VERSION ""

NS_ :

BS_:

BU_: VMCU TECU OBDScanT2 IC3 EMS ECUspare2 ECUspare1 DACU CIOM BBM

BO_ 2147484579 VMCU_BB2_07P: 8 VMCU
 SG_ Pto1BadCondition : 4|4@1+ (1,0) [0|0] ""  BBM,IC3
 SG_ PtosStatus_UB_ISig_4 : 40|1@1+ (1,0) [0|0] ""  EMS,CIOM,BBM,IC3
 SG_ Pto4BadCondition : 12|4@1+ (1,0) [0|0] ""  IC3,BBM
 SG_ Pto2BadCondition : 8|4@1+ (1,0) [0|0] ""  IC3,BBM
 SG_ PtoRequest : 18|2@1+ (1,0) [0|0] ""  EMS
 SG_ Pto2ConsentRequest : 32|2@1+ (1,0) [0|0] ""  TECU
 SG_ PBStatusDisplay_cmd_ISig_4 : 42|2@1+ (1,0) [0|0] ""  IC3
 SG_ Pto4DrivingRequest : 28|2@1+ (1,0) [0|0] ""  BBM
 SG_ Pto3Indication : 58|2@1+ (1,0) [0|0] ""  CIOM
 SG_ Pto2Status_ISig_4 : 22|2@1+ (1,0) [0|0] ""  IC3,TECU,CIOM,BBM
 SG_ Pto4Status_ISig_4 : 34|2@1+ (1,0) [0|0] ""  CIOM,IC3,BBM
 SG_ RampLevelRequestACK_ISig_4 : 44|2@1+ (1,0) [0|0] ""  CIOM
 SG_ Pto3BadCondition : 0|4@1+ (1,0) [0|0] ""  IC3,BBM
 SG_ PtosStatus_ISig_4 : 36|2@1+ (1,0) [0|0] ""  BBM,CIOM,EMS,IC3
 SG_ FrontWheelDriveAutoStatus_ISig_4 : 46|2@1+ (1,0) [0|0] ""  BBM,IC3
 SG_ Pto1ConsentRequest : 24|2@1+ (1,0) [0|0] ""  TECU
 SG_ Pto4Indication : 60|2@1+ (1,0) [0|0] ""  CIOM
 SG_ Pto1FeedbackStatus_UB_ISig_4 : 41|1@1+ (1,0) [0|0] ""  BBM,IC3
 SG_ Pto1Indication : 53|2@1+ (1,0) [0|0] ""  CIOM
 SG_ Pto3Status_ISig_4 : 16|2@1+ (1,0) [0|0] ""  BBM,IC3,CIOM
 SG_ Pto2Indication : 56|2@1+ (1,0) [0|0] ""  CIOM
 SG_ Pto1FeedbackStatus_ISig_4 : 38|2@1+ (1,0) [0|0] ""  BBM
 SG_ TransferCaseOrSplitboxPTOMode_IS : 26|2@1+ (1,0) [0|0] ""  TECU,BBM
 SG_ DirIndRearLamp_Stat_ISig_4 : 50|3@1+ (1,0) [0|0] ""  IC3
 SG_ Pto1Status_ISig_4 : 20|2@1+ (1,0) [0|0] ""  CIOM,TECU,BBM,IC3
 SG_ Pto3DrivingRequest : 30|2@1+ (1,0) [0|0] ""  BBM

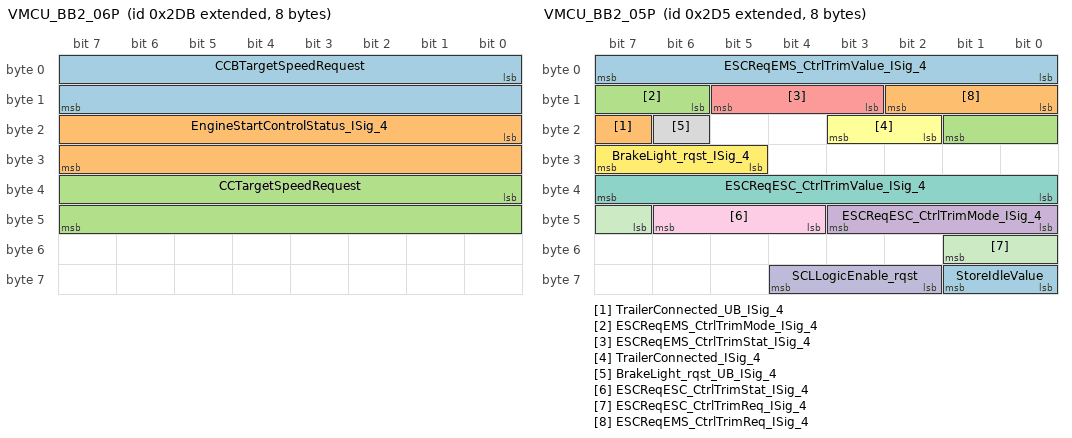
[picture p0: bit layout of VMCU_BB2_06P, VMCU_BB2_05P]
BO_ 2147484379 VMCU_BB2_06P: 8 VMCU
 SG_ CCBTargetSpeedRequest : 0|16@1+ (0.00390625,0) [0|255.99609375] "Km_per_h"  EMS,TECU
 SG_ EngineStartControlStatus_ISig_4 : 16|16@1+ (1,0) [0|0] ""  IC3,BBM
 SG_ CCTargetSpeedRequest : 32|16@1+ (0.00390625,0) [0|255.99609375] "Km_per_h"  TECU,EMS

BO_ 2147484373 VMCU_BB2_05P: 8 VMCU
 SG_ StoreIdleValue : 56|2@1+ (1,0) [0|0] ""  IC3,EMS
 SG_ TrailerConnected_UB_ISig_4 : 23|1@1+ (1,0) [0|0] ""  IC3,EMS,DACU,TECU,BBM
 SG_ ESCReqEMS_CtrlTrimMode_ISig_4 : 14|4@1+ (1,0) [0|0] ""  EMS,TECU,IC3
 SG_ ESCReqESC_CtrlTrimMode_ISig_4 : 40|4@1+ (1,0) [0|0] ""  CIOM,IC3,BBM
 SG_ ESCReqEMS_CtrlTrimStat_ISig_4 : 11|3@1+ (1,0) [0|0] ""  IC3,EMS,TECU
 SG_ TrailerConnected_ISig_4 : 18|2@1+ (1,0) [0|0] ""  TECU,IC3,EMS,DACU,BBM
 SG_ ESCReqESC_CtrlTrimValue_ISig_4 : 32|8@1+ (10,0) [0|2550] ""  BBM,IC3,CIOM
 SG_ BrakeLight_rqst_UB_ISig_4 : 22|1@1+ (1,0) [0|0] ""  BBM
 SG_ ESCReqESC_CtrlTrimStat_ISig_4 : 44|3@1+ (1,0) [0|0] ""  CIOM,BBM,IC3
 SG_ SCLLogicEnable_rqst : 58|3@1+ (1,0) [0|0] ""  CIOM
 SG_ ESCReqESC_CtrlTrimReq_ISig_4 : 47|3@1+ (1,0) [0|0] ""  IC3,CIOM,BBM
 SG_ BrakeLight_rqst_ISig_4 : 29|3@1+ (1,0) [0|0] ""  BBM
 SG_ ESCReqEMS_CtrlTrimValue_ISig_4 : 0|8@1+ (10,0) [0|2550] ""  IC3,TECU,EMS
 SG_ ESCReqEMS_CtrlTrimReq_ISig_4 : 8|3@1+ (1,0) [0|0] ""  IC3,TECU,EMS

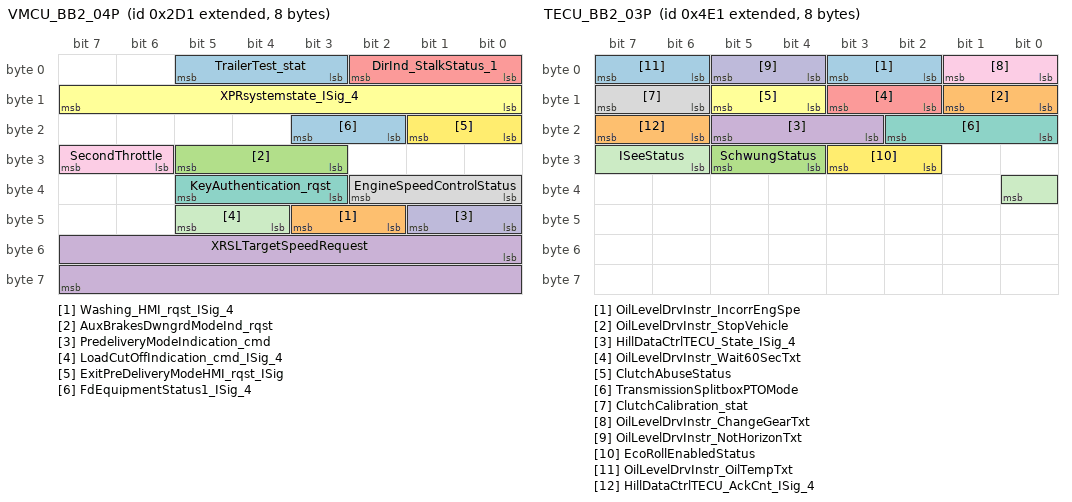
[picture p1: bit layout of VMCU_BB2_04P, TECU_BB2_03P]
BO_ 2147484369 VMCU_BB2_04P: 8 VMCU
 SG_ TrailerTest_stat : 3|3@1+ (1,0) [0|0] ""  IC3
 SG_ Washing_HMI_rqst_ISig_4 : 42|2@1+ (1,0) [0|0] ""  CIOM
 SG_ AuxBrakesDwngrdModeInd_rqst : 27|3@1+ (1,0) [0|0] ""  IC3
 SG_ XRSLTargetSpeedRequest : 48|16@1+ (0.00390625,0) [0|255.99609375] "Km_per_h"  EMS
 SG_ DirInd_StalkStatus_1 : 0|3@1+ (1,0) [0|0] ""  IC3
 SG_ XPRsystemstate_ISig_4 : 8|8@1+ (1,0) [0|255] "NotApplicable"  DACU,BBM
 SG_ KeyAuthentication_rqst : 35|3@1+ (1,0) [0|0] ""  CIOM
 SG_ EngineSpeedControlStatus : 32|3@1+ (1,0) [0|0] ""  CIOM,IC3,BBM
 SG_ SecondThrottle : 30|2@1+ (1,0) [0|0] ""  EMS,DACU
 SG_ PredeliveryModeIndication_cmd : 40|2@1+ (1,0) [0|0] ""  IC3,CIOM
 SG_ LoadCutOffIndication_cmd_ISig_4 : 44|2@1+ (1,0) [0|0] ""  IC3
 SG_ ExitPreDeliveryModeHMI_rqst_ISig : 16|2@1+ (1,0) [0|0] ""  CIOM
 SG_ FdEquipmentStatus1_ISig_4 : 18|2@1+ (1,0) [0|0] ""  BBM,IC3,CIOM

BO_ 2147484182 VMCU_BB2_03P: 8 VMCU
 SG_ ParkBrakeAlert_ISig_4 : 42|2@1+ (1,0) [0|0] ""  IC3
 SG_ IntLightMode_CoreRqst_IL_Mode : 48|3@1+ (1,0) [0|0] ""  IC3,CIOM
 SG_ WiperModeStatus_UB_ISig_4 : 55|1@1+ (1,0) [0|0] ""  CIOM,BBM,IC3,DACU
 SG_ SteeringColumnLockErrInd_rqst : 27|3@1+ (1,0) [0|0] ""  IC3
 SG_ ParkingLight_Indication : 30|2@1+ (1,0) [0|0] ""  CIOM
 SG_ DaytimeRunningLight_Indication : 16|2@1+ (1,0) [0|0] ""  CIOM
 SG_ EPBBackupMode_ISig_4 : 44|4@1+ (1,0) [0|0] ""  IC3
 SG_ WiperModeStatus_ISig_4 : 32|3@1+ (1,0) [0|0] ""  CIOM,DACU,IC3,BBM
 SG_ FrontFog_Indication : 22|2@1+ (1,0) [0|0] ""  CIOM
 SG_ PBReleaseAcceptance_stat_ISig_4 : 37|3@1+ (1,0) [0|0] ""  IC3
 SG_ ParkingBrake_stat_UB_ISig_4 : 54|1@1+ (1,0) [0|0] ""  IC3,EMS,CIOM,TECU,BBM
 SG_ DrivingLightPlus_Indication : 8|2@1+ (1,0) [0|0] ""  CIOM
 SG_ IntLightMode_CoreRqst_EventFlag : 51|1@1+ (1,0) [0|0] ""  CIOM,IC3
 SG_ ParkingBrake_stat_ISig_4 : 40|2@1+ (1,0) [0|0] ""  EMS,IC3,CIOM,BBM,TECU
 SG_ DrivingLight_Indication : 4|2@1+ (1,0) [0|0] ""  CIOM
 SG_ MirrorHeatingMode_ISig_4 : 24|3@1+ (1,0) [0|0] ""  CIOM
 SG_ RearFog_Indication : 35|2@1+ (1,0) [0|0] ""  CIOM
 SG_ InteriorLightLevelInd_cmd : 56|8@1+ (1,0) [0|255] "Percent"  CIOM

BO_ 2147484180 VMCU_BB2_02P: 8 VMCU
 SG_ LevelControlInformation_UB_ISig_ : 22|1@1+ (1,0) [0|0] ""  CIOM,IC3,TECU
 SG_ LiftAxle2LiftFuncSelected_ISig_4 : 11|3@1+ (1,0) [0|0] ""  IC3
 SG_ StopLevelChangeAck_ISig_4 : 6|2@1+ (1,0) [0|0] ""  CIOM
 SG_ HeightAdjustmentAllowed_ISig_4 : 38|2@1+ (1,0) [0|0] ""  CIOM
 SG_ LiftAxle2LowerACK_ISig_4 : 27|3@1+ (1,0) [0|0] ""  IC3
 SG_ LiftAxle2UpRequestACK_ISig_4 : 0|3@1+ (1,0) [0|0] ""  CIOM,IC3
 SG_ RideHeightStatus_ISig_4 : 44|4@1+ (1,0) [0|0] ""  CIOM,BBM
 SG_ RideHeightOutsideTargetRange_ISi : 32|3@1+ (1,0) [0|0] ""  IC3,CIOM
 SG_ LoadDistributionFuncSelected_ISi : 56|4@1+ (1,0) [0|0] ""  CIOM
 SG_ RideHeightStorageAck_ISig_4 : 30|2@1+ (1,0) [0|0] ""  CIOM
 SG_ LiftAxle2AutoLiftSelected_ISig_4 : 54|2@1+ (1,0) [0|0] ""  IC3
 SG_ LiftAxle1UpRequestACK_ISig_4 : 3|3@1+ (1,0) [0|0] ""  IC3,CIOM
 SG_ LiftAxle1PositionStatus_ISig_4 : 16|3@1+ (1,0) [0|0] ""  BBM,CIOM,TECU,DACU,IC3
 SG_ LiftAxle1LowerACK_ISig_4 : 24|3@1+ (1,0) [0|0] ""  IC3
 SG_ LiftAxle1AutoLiftSelected_ISig_4 : 52|2@1+ (1,0) [0|0] ""  IC3
 SG_ LiftAxle2PositionStatus_ISig_4 : 19|3@1+ (1,0) [0|0] ""  IC3,BBM,CIOM
 SG_ LevelControlInformation_ISig_4 : 48|4@1+ (1,0) [0|0] ""  TECU,IC3,CIOM
 SG_ LiftAxle1LiftFuncSelected_ISig_4 : 8|3@1+ (1,0) [0|0] ""  IC3
 SG_ LoadDistributionChangeACK_ISig_4 : 35|3@1+ (1,0) [0|0] ""  CIOM,IC3
 SG_ RampLevelStorageAck_ISig_4 : 14|2@1+ (1,0) [0|0] ""  CIOM
 SG_ LoadDistributionSelected_ISig_4 : 60|4@1+ (1,0) [0|0] ""  IC3,BBM,CIOM
 SG_ RideHeightFunctionStatus_ISig_4 : 40|4@1+ (1,0) [0|0] ""  CIOM

BO_ 2147484168 VMCU_BB2_01P: 8 VMCU
 SG_ GearSplit_Status_UB_ISig_4 : 13|1@1+ (1,0) [0|0] ""  IC3,BBM
 SG_ TransmLowRangeSenseSwitch_ISig_4 : 34|2@1+ (1,0) [0|0] ""  IC3,EMS
 SG_ TransmSystemPowerDown_rqst : 30|2@1+ (1,0) [0|0] ""  TECU
 SG_ TransmissionNeutralSwitch_ISig_4 : 8|2@1+ (1,0) [0|0] ""  BBM,EMS
 SG_ SecuredNeutralPosition_ISig_4 : 36|2@1+ (1,0) [0|0] ""  EMS,IC3,BBM
 SG_ EngineStopRequest_ISig_4 : 4|2@1+ (1,0) [0|0] ""  EMS
 SG_ TransmissionNeutralSwitch_UB_ISi : 32|1@1+ (1,0) [0|0] ""  EMS,BBM
 SG_ ReverseGearEngaged_ISig_4 : 0|2@1+ (1,0) [0|0] ""  DACU,EMS,CIOM,BBM,IC3
 SG_ TransmSystemPowerDown_rqst_UB : 33|1@1+ (1,0) [0|0] ""  TECU
 SG_ EngineCrankRequest : 14|2@1+ (1,0) [0|0] ""  EMS
 SG_ ParkBrakeActuationStatus_UB : 39|1@1+ (1,0) [0|0] ""  IC3,TECU,BBM
 SG_ ParkBrakeActuationStatus : 40|3@1+ (1,0) [0|0] ""  TECU,DACU,BBM,IC3
 SG_ EnginePreheat_rqst : 28|2@1+ (1,0) [0|0] ""  EMS
 SG_ ReverseGearEngaged_UB_ISig_4 : 12|1@1+ (1,0) [0|0] ""  EMS,DACU,IC3,CIOM,BBM
 SG_ AcceleratorPedalPositionBackup : 56|8@1+ (0.4,0) [0|102] "Percent"  EMS,TECU
 SG_ KeyPosition_ISig_4 : 16|3@1+ (1,0) [0|0] ""  CIOM,IC3
 SG_ GearSplit_Status_ISig_4 : 2|2@1+ (1,0) [0|0] ""  IC3,BBM
 SG_ FerryFunctionSwitchChangeACK_ISi : 45|2@1+ (1,0) [0|0] ""  CIOM
 SG_ SecuredNeutralPosition_UB_ISig_4 : 38|1@1+ (1,0) [0|0] ""  BBM,IC3,EMS
 SG_ DirectionIndication_cmd : 24|4@1+ (1,0) [0|0] ""  IC3
 SG_ IdleShutdownWarning : 6|2@1+ (1,0) [0|0] ""  IC3
 SG_ BackToDriveReqACK_ISig_4 : 43|2@1+ (1,0) [0|0] ""  CIOM
 SG_ EngineSystemPowerDownRequest_ISi : 22|2@1+ (1,0) [0|0] ""  EMS,IC3

BO_ 2671902706 TesterFuncDiagMsg_BB2: 8 VMCU
 SG_ FuncDiagDataTester_ISig_4 : 0|64@1+ (1,0) [0|0] ""  IC3,BBM,EMS,DACU,CIOM,TECU

BO_ 2147485094 TECU_BB2_06S_FCM: 8 CIOM
 SG_ TECU_BB2_06S_FCS : 0|64@1+ (1,0) [0|0] ""  TECU

BO_ 2147485093 TECU_BB2_06S: 11 TECU
 SG_ ECU5VIN_stat : 0|88@1+ (1,0) [0|0] ""  CIOM

BO_ 2147484587 TECU_BB2_05S_FCM: 8 CIOM
 SG_ TECU_BB2_05S_FCS : 0|64@1+ (1,0) [0|0] ""  TECU

BO_ 2147484586 TECU_BB2_05S: 16 TECU
 SG_ KeyID_EncryptedGBUnlockAuth : 0|128@1+ (1,0) [0|0] ""  CIOM

BO_ 2147485128 TECU_BB2_04S_FCM: 8 IC3
 SG_ TECU_BB2_04S_FCS : 0|64@1+ (1,0) [0|0] ""  TECU

BO_ 2147485127 TECU_BB2_04S: 284 TECU
 SG_ HillDataPkgTECU_ISig_4 : 0|2272@1+ (1,0) [0|0] ""  IC3

BO_ 2147484897 TECU_BB2_03P: 8 TECU
 SG_ OilLevelDrvInstr_IncorrEngSpe : 2|2@1+ (1,0) [0|0] ""  IC3
 SG_ OilLevelDrvInstr_StopVehicle : 8|2@1+ (1,0) [0|0] ""  IC3
 SG_ SchwungStatus : 28|2@1+ (1,0) [0|0] ""  VMCU
 SG_ HillDataCtrlTECU_State_ISig_4 : 19|3@1+ (1,0) [0|0] ""  IC3
 SG_ OilLevelDrvInstr_Wait60SecTxt : 10|2@1+ (1,0) [0|0] ""  IC3
 SG_ ClutchAbuseStatus : 12|2@1+ (1,0) [0|0] ""  IC3
 SG_ TransmissionSplitboxPTOMode : 16|3@1+ (1,0) [0|0] ""  IC3
 SG_ ClutchCalibration_stat : 14|2@1+ (1,0) [0|0] ""  IC3
 SG_ OilLevelDrvInstr_ChangeGearTxt : 0|2@1+ (1,0) [0|0] ""  IC3
 SG_ OilLevelDrvInstr_NotHorizonTxt : 4|2@1+ (1,0) [0|0] ""  IC3
 SG_ ISeeStatus : 30|3@1+ (1,0) [0|0] ""  IC3
 SG_ EcoRollEnabledStatus : 26|2@1+ (1,0) [0|0] ""  IC3
 SG_ OilLevelDrvInstr_OilTempTxt : 6|2@1+ (1,0) [0|0] ""  IC3
 SG_ HillDataCtrlTECU_AckCnt_ISig_4 : 22|2@1+ (1,0) [0|3] ""  IC3

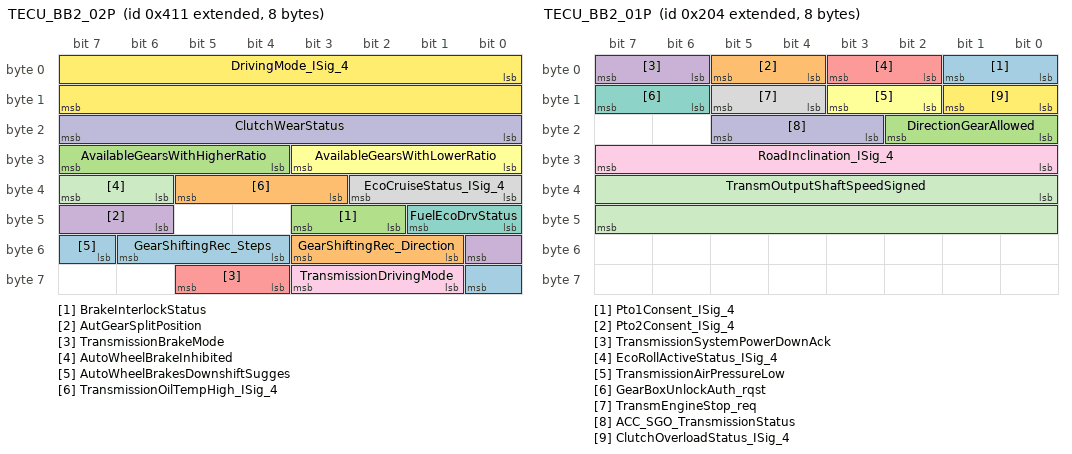
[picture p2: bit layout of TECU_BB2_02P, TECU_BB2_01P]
BO_ 2147484689 TECU_BB2_02P: 8 TECU
 SG_ GearShiftingRec_Steps : 52|3@1+ (1,0) [0|0] ""  IC3
 SG_ GearShiftingRec_Direction : 49|3@1+ (1,0) [0|0] ""  IC3
 SG_ BrakeInterlockStatus : 42|2@1+ (1,0) [0|0] ""  IC3,VMCU
 SG_ AutGearSplitPosition : 46|3@1+ (1,0) [0|0] ""  IC3
 SG_ TransmissionBrakeMode : 60|2@1+ (1,0) [0|0] ""  IC3
 SG_ AvailableGearsWithLowerRatio : 24|4@1+ (1,0) [0|15] "Count"  IC3
 SG_ FuelEcoDrvStatus : 40|2@1+ (1,0) [0|0] ""  VMCU
 SG_ EcoCruiseStatus_ISig_4 : 32|3@1+ (1,0) [0|0] ""  IC3,EMS
 SG_ TransmissionDrivingMode : 57|3@1+ (1,0) [0|0] ""  IC3
 SG_ ClutchWearStatus : 16|8@1+ (0.4,0) [0|102] "Percent"  VMCU
 SG_ AutoWheelBrakeInhibited : 38|2@1+ (1,0) [0|0] ""  EMS
 SG_ DrivingMode_ISig_4 : 0|16@1+ (1,0) [0|0] ""  VMCU,IC3
 SG_ AutoWheelBrakesDownshiftSugges : 55|2@1+ (1,0) [0|0] ""  IC3
 SG_ TransmissionOilTempHigh_ISig_4 : 35|3@1+ (1,0) [0|0] ""  BBM,IC3
 SG_ AvailableGearsWithHigherRatio : 28|4@1+ (1,0) [0|15] "Count"  VMCU,IC3

BO_ 2147484164 TECU_BB2_01P: 8 TECU
 SG_ Pto1Consent_ISig_4 : 0|2@1+ (1,0) [0|0] ""  BBM,VMCU
 SG_ Pto2Consent_ISig_4 : 4|2@1+ (1,0) [0|0] ""  BBM,VMCU
 SG_ DirectionGearAllowed : 16|3@1+ (1,0) [0|0] ""  VMCU
 SG_ TransmissionSystemPowerDownAck : 6|2@1+ (1,0) [0|0] ""  VMCU
 SG_ EcoRollActiveStatus_ISig_4 : 2|2@1+ (1,0) [0|0] ""  IC3,VMCU
 SG_ TransmissionAirPressureLow : 10|2@1+ (1,0) [0|0] ""  IC3
 SG_ GearBoxUnlockAuth_rqst : 14|2@1+ (1,0) [0|0] ""  CIOM
 SG_ TransmEngineStop_req : 12|2@1+ (1,0) [0|0] ""  EMS
 SG_ RoadInclination_ISig_4 : 24|8@1+ (0.2,-25) [-25|26] "Percent"  IC3,VMCU,EMS,DACU
 SG_ ACC_SGO_TransmissionStatus : 19|3@1+ (1,0) [0|0] ""  EMS,DACU
 SG_ TransmOutputShaftSpeedSigned : 32|16@1+ (0.125,-4000) [-4000|4191.875] "rpm"  DACU
 SG_ ClutchOverloadStatus_ISig_4 : 8|2@1+ (1,0) [0|0] ""  IC3,BBM

BO_ 2365530173 Reserved_CANid_02_BB2: 8 Vector__XXX

BO_ 2365530429 Reserved_CANid_01_BB2: 8 Vector__XXX

BO_ 2671833830 PhysDiagRespMsg_F2_E6_BB2: 8 BBM
 SG_ PhysDiagRespSig_F2_E6_ISig_4 : 0|64@1+ (1,0) [0|0] ""  VMCU

BO_ 2671833829 PhysDiagRespMsg_F2_E5_BB2: 8 BBM
 SG_ PhysDiagRespSig_F2_E5_ISig_4 : 0|64@1+ (1,0) [0|0] ""  VMCU

BO_ 2671833792 PhysDiagRespMsg_F2_C0_BB2: 8 CIOM
 SG_ PhysDiagRespSig_F2_C0_ISig_4 : 0|64@1+ (1,0) [0|0] ""  VMCU

BO_ 2671833762 PhysDiagRespMsg_F2_A2_BB2: 8 CIOM
 SG_ PhysDiagRespSig_F2_A2_ISig_4 : 0|64@1+ (1,0) [0|0] ""  VMCU

BO_ 2671833761 PhysDiagRespMsg_F2_A1_BB2: 8 CIOM
 SG_ PhysDiagRespSig_F2_A1_ISig_4 : 0|64@1+ (1,0) [0|0] ""  VMCU

BO_ 2671833760 PhysDiagRespMsg_F2_A0_BB2: 8 CIOM
 SG_ PhysDiagRespSig_F2_A0_ISig_4 : 0|64@1+ (1,0) [0|0] ""  VMCU

BO_ 2671833752 PhysDiagRespMsg_F2_98_BB2: 8 CIOM
 SG_ PhysDiagRespSig_F2_98_ISig_4 : 0|64@1+ (1,0) [0|0] ""  VMCU

BO_ 2671833731 PhysDiagRespMsg_F2_83_BB2: 8 IC3
 SG_ PhysDiagRespSig_F2_83_ISig_4 : 0|64@1+ (1,0) [0|0] ""  VMCU

BO_ 2671833730 PhysDiagRespMsg_F2_82_BB2: 8 IC3
 SG_ PhysDiagRespSig_F2_82_ISig_4 : 0|64@1+ (1,0) [0|0] ""  VMCU

BO_ 2671833697 PhysDiagRespMsg_F2_61_BB2: 8 IC3
 SG_ PhysDiagRespSig_F2_61_ISig_4 : 0|64@1+ (1,0) [0|0] ""  VMCU

BO_ 2671833696 PhysDiagRespMsg_F2_60_BB2: 8 IC3
 SG_ PhysDiagRespSig_F2_60_ISig_4 : 0|64@1+ (1,0) [0|0] ""  VMCU

BO_ 2671833683 PhysDiagRespMsg_F2_53_BB2: 8 CIOM
 SG_ PhysDiagRespSig_F2_53_ISig_4 : 0|64@1+ (1,0) [0|0] ""  VMCU

BO_ 2671833682 PhysDiagRespMsg_F2_52_BB2: 8 DACU
 SG_ PhysDiagRespSig_F2_52_ISig_4 : 0|64@1+ (1,0) [0|0] ""  VMCU

BO_ 2671833681 PhysDiagRespMsg_F2_51_BB2: 8 DACU
 SG_ PhysDiagRespSig_F2_51_ISig_4 : 0|64@1+ (1,0) [0|0] ""  VMCU

BO_ 2671833680 PhysDiagRespMsg_F2_50_BB2: 8 DACU
 SG_ PhysDiagRespSig_F2_50_ISig_4 : 0|64@1+ (1,0) [0|0] ""  VMCU

BO_ 2671833665 PhysDiagRespMsg_F2_41_BB2: 8 IC3
 SG_ PhysDiagRespSig_F2_41_ISig_4 : 0|64@1+ (1,0) [0|0] ""  VMCU

BO_ 2671833664 PhysDiagRespMsg_F2_40_BB2: 8 CIOM
 SG_ PhysDiagRespSig_F2_40_ISig_4 : 0|64@1+ (1,0) [0|0] ""  VMCU

BO_ 2671833638 PhysDiagRespMsg_F2_26_BB2: 8 CIOM
 SG_ PhysDiagRespSig_F2_26_ISig_4 : 0|64@1+ (1,0) [0|0] ""  VMCU

BO_ 2671833624 PhysDiagRespMsg_F2_18_BB2: 8 TECU
 SG_ PhysDiagRespSig_F2_18_ISig_4 : 0|64@1+ (1,0) [0|0] ""  VMCU

BO_ 2671833616 PhysDiagRespMsg_F2_10_BB2: 8 EMS
 SG_ PhysDiagRespSig_F2_10_ISig_4 : 0|64@1+ (1,0) [0|0] ""  VMCU

BO_ 2564485459 PhysDiagRespMsg_F1_53_BB2: 8 CIOM
 SG_ PhysDiagRespSig_F1_53_ISig_4 : 0|64@1+ (1,0) [0|0] ""  VMCU

BO_ 2564485392 PhysDiagRespMsg_F1_10_BB2_extra: 8 EMS
 SG_ PhysDiagRespSig_F1_10_extra : 0|64@1+ (1,0) [0|0] ""  OBDScanT2

BO_ 2671833360 PhysDiagRespMsg_F1_10_BB2: 8 EMS
 SG_ PhysDiagRespSig_F1_10_ISig_4 : 0|64@1+ (1,0) [0|0] ""  VMCU

BO_ 2671833700 PhysDiagReqMsg_F2_64_BB2: 8 IC3
 SG_ PhysDiagRespSig_F2_64_ISig_4 : 0|64@1+ (1,0) [0|0] ""  VMCU

BO_ 2671830770 PhysDiagReqMsg_E6_F2_BB2: 8 VMCU
 SG_ PhysDiagReqSig_E6_F2_ISig_4 : 0|64@1+ (1,0) [0|0] ""  BBM

BO_ 2671830514 PhysDiagReqMsg_E5_F2_BB2: 8 VMCU
 SG_ PhysDiagReqSig_E5_F2_ISig_4 : 0|64@1+ (1,0) [0|0] ""  BBM

BO_ 2671821042 PhysDiagReqMsg_C0_F2_BB2: 8 VMCU
 SG_ PhysDiagReqSig_C0_F2_ISig_4 : 0|64@1+ (1,0) [0|0] ""  CIOM

BO_ 2671813362 PhysDiagReqMsg_A2_F2_BB2: 8 VMCU
 SG_ PhysDiagReqSig_A2_F2_ISig_4 : 0|64@1+ (1,0) [0|0] ""  CIOM

BO_ 2671813106 PhysDiagReqMsg_A1_F2_BB2: 8 VMCU
 SG_ PhysDiagReqSig_A1_F2_ISig_4 : 0|64@1+ (1,0) [0|0] ""  CIOM

BO_ 2671812850 PhysDiagReqMsg_A0_F2_BB2: 8 VMCU
 SG_ PhysDiagReqSig_A0_F2_ISig_4 : 0|64@1+ (1,0) [0|0] ""  CIOM

BO_ 2671810802 PhysDiagReqMsg_98_F2_BB2: 8 VMCU
 SG_ PhysDiagReqSig_98_F2_ISig_4 : 0|64@1+ (1,0) [0|0] ""  CIOM

BO_ 2671805426 PhysDiagReqMsg_83_F2_BB2: 8 VMCU
 SG_ PhysDiagReqSig_83_F2_ISig_4 : 0|64@1+ (1,0) [0|0] ""  IC3

BO_ 2671805170 PhysDiagReqMsg_82_F2_BB2: 8 VMCU
 SG_ PhysDiagReqSig_82_F2_ISig_4 : 0|64@1+ (1,0) [0|0] ""  IC3

BO_ 2671797490 PhysDiagReqMsg_64_F2_BB2: 8 VMCU
 SG_ PhysDiagReqSig_64_F2_ISig_4 : 0|64@1+ (1,0) [0|0] ""  IC3

BO_ 2671796722 PhysDiagReqMsg_61_F2_BB2: 8 VMCU
 SG_ PhysDiagReqSig_61_F2_ISig_4 : 0|64@1+ (1,0) [0|0] ""  IC3

BO_ 2671796466 PhysDiagReqMsg_60_F2_BB2: 8 VMCU
 SG_ PhysDiagReqSig_60_F2_ISig_4 : 0|64@1+ (1,0) [0|0] ""  IC3

BO_ 2671793138 PhysDiagReqMsg_53_F2_BB2: 8 VMCU
 SG_ PhysDiagReqSig_53_F2_ISig_4 : 0|64@1+ (1,0) [0|0] ""  CIOM

BO_ 2564445169 PhysDiagReqMsg_53_F1_BB2: 8 VMCU
 SG_ PhysDiagReqSig_53_F1_ISig_4 : 0|64@1+ (1,0) [0|0] ""  CIOM

BO_ 2671792882 PhysDiagReqMsg_52_F2_BB2: 8 VMCU
 SG_ PhysDiagReqSig_52_F2_ISig_4 : 0|64@1+ (1,0) [0|0] ""  DACU

BO_ 2671792626 PhysDiagReqMsg_51_F2_BB2: 8 VMCU
 SG_ PhysDiagReqSig_51_F2_ISig_4 : 0|64@1+ (1,0) [0|0] ""  DACU

BO_ 2671792370 PhysDiagReqMsg_50_F2_BB2: 8 VMCU
 SG_ PhysDiagReqSig_50_F2_ISig_4 : 0|64@1+ (1,0) [0|0] ""  DACU

BO_ 2671788530 PhysDiagReqMsg_41_F2_BB2: 8 VMCU
 SG_ PhysDiagReqSig_41_F2_ISig_4 : 0|64@1+ (1,0) [0|0] ""  IC3

BO_ 2671788274 PhysDiagReqMsg_40_F2_BB2: 8 VMCU
 SG_ PhysDiagReqSig_40_F2_ISig_4 : 0|64@1+ (1,0) [0|0] ""  CIOM

BO_ 2671781618 PhysDiagReqMsg_26_F2_BB2: 8 VMCU
 SG_ PhysDiagReqSig_26_F2_ISig_4 : 0|64@1+ (1,0) [0|0] ""  CIOM

BO_ 2671778034 PhysDiagReqMsg_18_F2_BB2: 8 VMCU
 SG_ PhysDiagReqSig_18_F2_ISig_4 : 0|64@1+ (1,0) [0|0] ""  TECU

BO_ 2671775986 PhysDiagReqMsg_10_F2_BB2: 8 VMCU
 SG_ PhysDiagReqSig_10_F2_ISig_4 : 0|64@1+ (1,0) [0|0] ""  EMS

BO_ 2564428017 PhysDiagReqMsg_10_F1_BB2_extra: 8 OBDScanT2
 SG_ PhysDiagReqSig_10_F1_extra : 0|64@1+ (1,0) [0|0] ""  EMS

BO_ 2671775985 PhysDiagReqMsg_10_F1_BB2: 8 VMCU
 SG_ PhysDiagReqSig_10_F1_ISig_4 : 0|64@1+ (1,0) [0|0] ""  EMS

BO_ 2564502513 OBDFuncDiagMsg_BB2_extra: 8 OBDScanT2
 SG_ FuncDiagDataOBD_extra : 0|64@1+ (1,0) [0|0] ""  EMS

CM_ SG_ 2147484379 CCBTargetSpeedRequest "65024 - 65279 Error ; 65280 - 65535 Not available";
CM_ SG_ 2147484379 EngineStartControlStatus_ISig_4 "65534 Error ; 65535 Not available";
CM_ SG_ 2147484379 CCTargetSpeedRequest "65024 - 65279 Error ; 65280 - 65535 Not available";
CM_ SG_ 2147484373 ESCReqESC_CtrlTrimValue_ISig_4 "254 Error ; 255 Not available";
CM_ SG_ 2147484373 ESCReqEMS_CtrlTrimValue_ISig_4 "254 Error ; 255 Not available";
CM_ SG_ 2147484369 XRSLTargetSpeedRequest "65024 - 65279 Error ; 65280 - 65535 Not available";
CM_ SG_ 2147484689 AvailableGearsWithLowerRatio "14 Error ; 15 Not available";
CM_ SG_ 2147484689 ClutchWearStatus "254 Error ; 255 Not available";
CM_ SG_ 2147484689 AvailableGearsWithHigherRatio "14 Error ; 15 Not available";
CM_ SG_ 2147484164 RoadInclination_ISig_4 "254 Error ; 255 Not available";
CM_ BO_ 2365530173 "Request to reserve CANid from Powertrain (ACM ECU)";
CM_ BO_ 2365530429 "Request to reserve CANid from Powertrain (ACM ECU)";
CM_ BO_ 2671833696 "Note: old interface for HMIIOM, can be deleted when IC3 is configured with address 0x61.";
CM_ BO_ 2671796466 "Note: old interface for HMIIOM, can be deleted when IC3 is configured with address 0x61.";
BA_DEF_ BO_  "GenMsgStartDelayTime" INT 0 0;
BA_DEF_ BO_  "GenMsgDelayTime" INT 0 0;
BA_DEF_ BO_  "GenMsgCycleTime" INT 0 0;
BA_DEF_ BO_  "GenMsgSendType" ENUM  "Cyclic","NotUsed","NotUsed","NotUsed","NotUsed","NotUsed","NotUsed","IfActive","NoMsgSendType","NotUsed";
BA_DEF_ SG_  "GenSigStartValue" INT 0 0;
BA_DEF_ SG_  "GenSigCycleTimeActive" INT 0 0;
BA_DEF_ SG_  "GenSigCycleTime" INT 0 0;
BA_DEF_ SG_  "GenSigSendType" ENUM  "Cyclic","OnWrite","OnWriteWithRepetition","OnChange","OnChangeWithRepetition","IfActive","IfActiveWithRepetition","NoSigSendType","NotUsed","NotUsed","NotUsed","NotUsed","NotUsed";
BA_DEF_ BO_  "VFrameFormat" ENUM  "StandardCAN","ExtendedCAN","reserved","J1939PG";
BA_DEF_ SG_  "SigType" ENUM  "Default","Range","RangeSigned","ASCII","Discrete","Control","ReferencePGN","DTC","StringDelimiter","StringLength","StringLengthControl";
BA_DEF_ SG_  "SeToolVersion_SIGNAL" STRING ;
BA_DEF_ SG_  "SeToolUniqueID_SIGNAL" STRING ;
BA_DEF_ SG_  "SeToolOwnerSigGroup_SIGNAL" STRING ;
BA_DEF_ SG_  "SeToolOwnerSigGroupID_SIGNAL" STRING ;
BA_DEF_ SG_  "SeToolName_SIGNAL" STRING ;
BA_DEF_ SG_  "SeToolItemID_SIGNAL" STRING ;
BA_DEF_ SG_  "SeToolAncestorID_SIGNAL" STRING ;
BA_DEF_ SG_  "Platform_VMCU1_Sig" ENUM  "No","Yes";
BA_DEF_ BO_  "NmAsrMessage" ENUM  "No","Yes";
BA_DEF_ SG_  "NeedsUpdateBit" ENUM  "No","Yes";
BA_DEF_ SG_  "MmAnSignal" ENUM  "No","Yes";
BA_DEF_ SG_  "GenSigMaxLatency" INT 0 65535;
BA_DEF_ SG_  "GenSigILSupport" ENUM  "Yes","No";
BA_DEF_ BO_  "GenMsgRequestable" INT 0 1;
BA_DEF_ BO_  "GenMsgILSupport" ENUM  "No","Yes";
BA_DEF_ BO_  "DiagUUDTResponse" ENUM  "No","Yes";
BA_DEF_ BO_  "DiagState" ENUM  "No","Yes";
BA_DEF_ BO_  "DiagResponse" ENUM  "No","Yes";
BA_DEF_ BO_  "DiagRequest" ENUM  "No","Yes";
BA_DEF_ BO_  "DiagConnection" HEX 0 65535;
BA_DEF_ BO_  "CanTpSTmin" INT 0 255;
BA_DEF_ BO_  "CanTpFcFrameId" HEX 0 2147483647;
BA_DEF_ BO_  "CanTpBs" INT 0 255;
BA_DEF_ SG_  "SystemSignalLongSymbol" STRING ;
BA_DEF_REL_ BU_SG_REL_  "GenSigTimeoutTime" INT 0 65535;
BA_DEF_REL_ BU_SG_REL_  "GenSigFirstTimeoutTime" INT 0 65535;
BA_DEF_DEF_  "GenMsgStartDelayTime" 0;
BA_DEF_DEF_  "GenMsgDelayTime" 0;
BA_DEF_DEF_  "GenMsgCycleTime" 0;
BA_DEF_DEF_  "GenMsgSendType" "Cyclic";
BA_DEF_DEF_  "GenSigStartValue" 0;
BA_DEF_DEF_  "GenSigCycleTimeActive" 0;
BA_DEF_DEF_  "GenSigCycleTime" 0;
BA_DEF_DEF_  "GenSigSendType" "Cyclic";
BA_DEF_DEF_  "VFrameFormat" "ExtendedCAN";
BA_DEF_DEF_  "SigType" "Default";
BA_DEF_DEF_  "SeToolVersion_SIGNAL" "";
BA_DEF_DEF_  "SeToolUniqueID_SIGNAL" "";
BA_DEF_DEF_  "SeToolOwnerSigGroup_SIGNAL" "";
BA_DEF_DEF_  "SeToolOwnerSigGroupID_SIGNAL" "";
BA_DEF_DEF_  "SeToolName_SIGNAL" "";
BA_DEF_DEF_  "SeToolItemID_SIGNAL" "";
BA_DEF_DEF_  "SeToolAncestorID_SIGNAL" "";
BA_DEF_DEF_  "Platform_VMCU1_Sig" "No";
BA_DEF_DEF_  "NmAsrMessage" "No";
BA_DEF_DEF_  "NeedsUpdateBit" "No";
BA_DEF_DEF_  "MmAnSignal" "No";
BA_DEF_DEF_  "GenSigMaxLatency" 0;
BA_DEF_DEF_  "GenSigILSupport" "Yes";
BA_DEF_DEF_  "GenMsgRequestable" 1;
BA_DEF_DEF_  "GenMsgILSupport" "Yes";
BA_DEF_DEF_  "DiagUUDTResponse" "No";
BA_DEF_DEF_  "DiagState" "No";
BA_DEF_DEF_  "DiagResponse" "No";
BA_DEF_DEF_  "DiagRequest" "No";
BA_DEF_DEF_  "DiagConnection" 0;
BA_DEF_DEF_  "CanTpSTmin" 0;
BA_DEF_DEF_  "CanTpFcFrameId" 2147483647;
BA_DEF_DEF_  "CanTpBs" 255;
BA_DEF_DEF_REL_ "GenSigTimeoutTime" 0;
BA_DEF_DEF_REL_ "GenSigFirstTimeoutTime" 0;
BA_DEF_DEF_  "SystemSignalLongSymbol" "";
BA_ "GenMsgCycleTime" BO_ 2147484579 75;
BA_ "GenMsgStartDelayTime" BO_ 2147484579 25;
BA_ "GenMsgCycleTime" BO_ 2147484379 45;
BA_ "GenMsgStartDelayTime" BO_ 2147484379 5;
BA_ "GenMsgCycleTime" BO_ 2147484373 45;
BA_ "GenMsgStartDelayTime" BO_ 2147484373 10;
BA_ "GenMsgCycleTime" BO_ 2147484369 45;
BA_ "GenMsgStartDelayTime" BO_ 2147484369 25;
BA_ "GenMsgCycleTime" BO_ 2147484182 25;
BA_ "GenMsgStartDelayTime" BO_ 2147484182 5;
BA_ "GenMsgCycleTime" BO_ 2147484180 25;
BA_ "GenMsgStartDelayTime" BO_ 2147484180 10;
BA_ "GenMsgCycleTime" BO_ 2147484168 20;
BA_ "DiagConnection" BO_ 2671902706 62182;
BA_ "DiagState" BO_ 2671902706 1;
BA_ "GenMsgILSupport" BO_ 2671902706 0;
BA_ "GenMsgSendType" BO_ 2671902706 8;
BA_ "GenMsgILSupport" BO_ 2147485094 0;
BA_ "GenMsgSendType" BO_ 2147485094 8;
BA_ "CanTpFcFrameId" BO_ 2147485093 1446;
BA_ "GenMsgSendType" BO_ 2147485093 8;
BA_ "GenMsgDelayTime" BO_ 2147485093 110;
BA_ "GenMsgILSupport" BO_ 2147484587 0;
BA_ "GenMsgSendType" BO_ 2147484587 8;
BA_ "CanTpFcFrameId" BO_ 2147484586 939;
BA_ "GenMsgSendType" BO_ 2147484586 8;
BA_ "GenMsgDelayTime" BO_ 2147484586 20;
BA_ "CanTpSTmin" BO_ 2147485128 5;
BA_ "GenMsgILSupport" BO_ 2147485128 0;
BA_ "GenMsgSendType" BO_ 2147485128 8;
BA_ "CanTpFcFrameId" BO_ 2147485127 1480;
BA_ "CanTpSTmin" BO_ 2147485127 5;
BA_ "GenMsgSendType" BO_ 2147485127 8;
BA_ "GenMsgDelayTime" BO_ 2147485127 2290;
BA_ "GenMsgStartDelayTime" BO_ 2147485127 50;
BA_ "GenMsgCycleTime" BO_ 2147484897 500;
BA_ "GenMsgStartDelayTime" BO_ 2147484897 100;
BA_ "GenMsgCycleTime" BO_ 2147484689 100;
BA_ "GenMsgStartDelayTime" BO_ 2147484689 10;
BA_ "GenMsgCycleTime" BO_ 2147484164 25;
BA_ "GenMsgStartDelayTime" BO_ 2147484164 5;
BA_ "DiagConnection" BO_ 2671833830 62182;
BA_ "DiagResponse" BO_ 2671833830 1;
BA_ "GenMsgILSupport" BO_ 2671833830 0;
BA_ "GenMsgSendType" BO_ 2671833830 8;
BA_ "DiagConnection" BO_ 2671833829 62181;
BA_ "DiagResponse" BO_ 2671833829 1;
BA_ "GenMsgILSupport" BO_ 2671833829 0;
BA_ "GenMsgSendType" BO_ 2671833829 8;
BA_ "DiagConnection" BO_ 2671833792 62144;
BA_ "DiagResponse" BO_ 2671833792 1;
BA_ "GenMsgILSupport" BO_ 2671833792 0;
BA_ "GenMsgSendType" BO_ 2671833792 8;
BA_ "DiagConnection" BO_ 2671833762 62114;
BA_ "DiagResponse" BO_ 2671833762 1;
BA_ "GenMsgILSupport" BO_ 2671833762 0;
BA_ "GenMsgSendType" BO_ 2671833762 8;
BA_ "DiagConnection" BO_ 2671833761 62113;
BA_ "DiagResponse" BO_ 2671833761 1;
BA_ "GenMsgILSupport" BO_ 2671833761 0;
BA_ "GenMsgSendType" BO_ 2671833761 8;
BA_ "DiagConnection" BO_ 2671833760 62112;
BA_ "DiagResponse" BO_ 2671833760 1;
BA_ "GenMsgILSupport" BO_ 2671833760 0;
BA_ "GenMsgSendType" BO_ 2671833760 8;
BA_ "DiagConnection" BO_ 2671833752 62104;
BA_ "DiagResponse" BO_ 2671833752 1;
BA_ "GenMsgILSupport" BO_ 2671833752 0;
BA_ "GenMsgSendType" BO_ 2671833752 8;
BA_ "DiagConnection" BO_ 2671833731 62083;
BA_ "DiagResponse" BO_ 2671833731 1;
BA_ "GenMsgILSupport" BO_ 2671833731 0;
BA_ "GenMsgSendType" BO_ 2671833731 8;
BA_ "DiagConnection" BO_ 2671833730 62082;
BA_ "DiagResponse" BO_ 2671833730 1;
BA_ "GenMsgILSupport" BO_ 2671833730 0;
BA_ "GenMsgSendType" BO_ 2671833730 8;
BA_ "DiagConnection" BO_ 2671833697 62049;
BA_ "DiagResponse" BO_ 2671833697 1;
BA_ "GenMsgILSupport" BO_ 2671833697 0;
BA_ "GenMsgSendType" BO_ 2671833697 8;
BA_ "DiagConnection" BO_ 2671833696 62048;
BA_ "DiagResponse" BO_ 2671833696 1;
BA_ "GenMsgILSupport" BO_ 2671833696 0;
BA_ "GenMsgSendType" BO_ 2671833696 8;
BA_ "DiagConnection" BO_ 2671833683 62035;
BA_ "DiagResponse" BO_ 2671833683 1;
BA_ "GenMsgILSupport" BO_ 2671833683 0;
BA_ "GenMsgSendType" BO_ 2671833683 8;
BA_ "DiagConnection" BO_ 2671833682 62034;
BA_ "DiagResponse" BO_ 2671833682 1;
BA_ "GenMsgILSupport" BO_ 2671833682 0;
BA_ "GenMsgSendType" BO_ 2671833682 8;
BA_ "DiagConnection" BO_ 2671833681 62033;
BA_ "DiagResponse" BO_ 2671833681 1;
BA_ "GenMsgILSupport" BO_ 2671833681 0;
BA_ "GenMsgSendType" BO_ 2671833681 8;
BA_ "DiagConnection" BO_ 2671833680 62032;
BA_ "DiagResponse" BO_ 2671833680 1;
BA_ "GenMsgILSupport" BO_ 2671833680 0;
BA_ "GenMsgSendType" BO_ 2671833680 8;
BA_ "DiagConnection" BO_ 2671833665 62017;
BA_ "DiagResponse" BO_ 2671833665 1;
BA_ "GenMsgILSupport" BO_ 2671833665 0;
BA_ "GenMsgSendType" BO_ 2671833665 8;
BA_ "DiagConnection" BO_ 2671833664 62016;
BA_ "DiagResponse" BO_ 2671833664 1;
BA_ "GenMsgILSupport" BO_ 2671833664 0;
BA_ "GenMsgSendType" BO_ 2671833664 8;
BA_ "DiagConnection" BO_ 2671833638 61990;
BA_ "DiagResponse" BO_ 2671833638 1;
BA_ "GenMsgILSupport" BO_ 2671833638 0;
BA_ "GenMsgSendType" BO_ 2671833638 8;
BA_ "DiagConnection" BO_ 2671833624 61976;
BA_ "DiagResponse" BO_ 2671833624 1;
BA_ "GenMsgILSupport" BO_ 2671833624 0;
BA_ "GenMsgSendType" BO_ 2671833624 8;
BA_ "DiagConnection" BO_ 2671833616 61968;
BA_ "DiagResponse" BO_ 2671833616 1;
BA_ "GenMsgILSupport" BO_ 2671833616 0;
BA_ "GenMsgSendType" BO_ 2671833616 8;
BA_ "DiagConnection" BO_ 2564485459 61779;
BA_ "DiagResponse" BO_ 2564485459 1;
BA_ "GenMsgILSupport" BO_ 2564485459 0;
BA_ "GenMsgSendType" BO_ 2564485459 8;
BA_ "DiagConnection" BO_ 2564485392 63504;
BA_ "DiagResponse" BO_ 2564485392 1;
BA_ "GenMsgILSupport" BO_ 2564485392 0;
BA_ "GenMsgSendType" BO_ 2564485392 8;
BA_ "DiagConnection" BO_ 2671833360 61712;
BA_ "DiagResponse" BO_ 2671833360 1;
BA_ "GenMsgILSupport" BO_ 2671833360 0;
BA_ "GenMsgSendType" BO_ 2671833360 8;
BA_ "DiagConnection" BO_ 2671833700 62052;
BA_ "DiagResponse" BO_ 2671833700 1;
BA_ "GenMsgILSupport" BO_ 2671833700 0;
BA_ "GenMsgSendType" BO_ 2671833700 8;
BA_ "DiagConnection" BO_ 2671830770 62182;
BA_ "DiagRequest" BO_ 2671830770 1;
BA_ "GenMsgILSupport" BO_ 2671830770 0;
BA_ "GenMsgSendType" BO_ 2671830770 8;
BA_ "DiagConnection" BO_ 2671830514 62181;
BA_ "DiagRequest" BO_ 2671830514 1;
BA_ "GenMsgILSupport" BO_ 2671830514 0;
BA_ "GenMsgSendType" BO_ 2671830514 8;
BA_ "DiagConnection" BO_ 2671821042 62144;
BA_ "DiagRequest" BO_ 2671821042 1;
BA_ "GenMsgILSupport" BO_ 2671821042 0;
BA_ "GenMsgSendType" BO_ 2671821042 8;
BA_ "DiagConnection" BO_ 2671813362 62114;
BA_ "DiagRequest" BO_ 2671813362 1;
BA_ "GenMsgILSupport" BO_ 2671813362 0;
BA_ "GenMsgSendType" BO_ 2671813362 8;
BA_ "DiagConnection" BO_ 2671813106 62113;
BA_ "DiagRequest" BO_ 2671813106 1;
BA_ "GenMsgILSupport" BO_ 2671813106 0;
BA_ "GenMsgSendType" BO_ 2671813106 8;
BA_ "DiagConnection" BO_ 2671812850 62112;
BA_ "DiagRequest" BO_ 2671812850 1;
BA_ "GenMsgILSupport" BO_ 2671812850 0;
BA_ "GenMsgSendType" BO_ 2671812850 8;
BA_ "DiagConnection" BO_ 2671810802 62104;
BA_ "DiagRequest" BO_ 2671810802 1;
BA_ "GenMsgILSupport" BO_ 2671810802 0;
BA_ "GenMsgSendType" BO_ 2671810802 8;
BA_ "DiagConnection" BO_ 2671805426 62083;
BA_ "DiagRequest" BO_ 2671805426 1;
BA_ "GenMsgILSupport" BO_ 2671805426 0;
BA_ "GenMsgSendType" BO_ 2671805426 8;
BA_ "DiagConnection" BO_ 2671805170 62082;
BA_ "DiagRequest" BO_ 2671805170 1;
BA_ "GenMsgILSupport" BO_ 2671805170 0;
BA_ "GenMsgSendType" BO_ 2671805170 8;
BA_ "DiagConnection" BO_ 2671797490 62052;
BA_ "DiagRequest" BO_ 2671797490 1;
BA_ "GenMsgILSupport" BO_ 2671797490 0;
BA_ "GenMsgSendType" BO_ 2671797490 8;
BA_ "DiagConnection" BO_ 2671796722 62049;
BA_ "DiagRequest" BO_ 2671796722 1;
BA_ "GenMsgILSupport" BO_ 2671796722 0;
BA_ "GenMsgSendType" BO_ 2671796722 8;
BA_ "DiagConnection" BO_ 2671796466 62048;
BA_ "DiagRequest" BO_ 2671796466 1;
BA_ "GenMsgILSupport" BO_ 2671796466 0;
BA_ "GenMsgSendType" BO_ 2671796466 8;
BA_ "DiagConnection" BO_ 2671793138 62035;
BA_ "DiagRequest" BO_ 2671793138 1;
BA_ "GenMsgILSupport" BO_ 2671793138 0;
BA_ "GenMsgSendType" BO_ 2671793138 8;
BA_ "DiagConnection" BO_ 2564445169 61779;
BA_ "DiagRequest" BO_ 2564445169 1;
BA_ "GenMsgILSupport" BO_ 2564445169 0;
BA_ "GenMsgSendType" BO_ 2564445169 8;
BA_ "DiagConnection" BO_ 2671792882 62034;
BA_ "DiagRequest" BO_ 2671792882 1;
BA_ "GenMsgILSupport" BO_ 2671792882 0;
BA_ "GenMsgSendType" BO_ 2671792882 8;
BA_ "DiagConnection" BO_ 2671792626 62033;
BA_ "DiagRequest" BO_ 2671792626 1;
BA_ "GenMsgILSupport" BO_ 2671792626 0;
BA_ "GenMsgSendType" BO_ 2671792626 8;
BA_ "DiagConnection" BO_ 2671792370 62032;
BA_ "DiagRequest" BO_ 2671792370 1;
BA_ "GenMsgILSupport" BO_ 2671792370 0;
BA_ "GenMsgSendType" BO_ 2671792370 8;
BA_ "DiagConnection" BO_ 2671788530 62017;
BA_ "DiagRequest" BO_ 2671788530 1;
BA_ "GenMsgILSupport" BO_ 2671788530 0;
BA_ "GenMsgSendType" BO_ 2671788530 8;
BA_ "DiagConnection" BO_ 2671788274 62016;
BA_ "DiagRequest" BO_ 2671788274 1;
BA_ "GenMsgILSupport" BO_ 2671788274 0;
BA_ "GenMsgSendType" BO_ 2671788274 8;
BA_ "DiagConnection" BO_ 2671781618 61990;
BA_ "DiagRequest" BO_ 2671781618 1;
BA_ "GenMsgILSupport" BO_ 2671781618 0;
BA_ "GenMsgSendType" BO_ 2671781618 8;
BA_ "DiagConnection" BO_ 2671778034 61976;
BA_ "DiagRequest" BO_ 2671778034 1;
BA_ "GenMsgILSupport" BO_ 2671778034 0;
BA_ "GenMsgSendType" BO_ 2671778034 8;
BA_ "DiagConnection" BO_ 2671775986 61968;
BA_ "DiagRequest" BO_ 2671775986 1;
BA_ "GenMsgILSupport" BO_ 2671775986 0;
BA_ "GenMsgSendType" BO_ 2671775986 8;
BA_ "DiagConnection" BO_ 2564428017 63504;
BA_ "DiagRequest" BO_ 2564428017 1;
BA_ "GenMsgILSupport" BO_ 2564428017 0;
BA_ "GenMsgSendType" BO_ 2564428017 8;
BA_ "DiagConnection" BO_ 2671775985 61712;
BA_ "DiagRequest" BO_ 2671775985 1;
BA_ "GenMsgILSupport" BO_ 2671775985 0;
BA_ "GenMsgSendType" BO_ 2671775985 8;
BA_ "DiagConnection" BO_ 2564502513 63504;
BA_ "DiagState" BO_ 2564502513 1;
BA_ "GenMsgILSupport" BO_ 2564502513 0;
BA_ "GenMsgSendType" BO_ 2564502513 8;
BA_ "GenSigCycleTime" SG_ 2147484579 Pto1BadCondition 100;
BA_ "GenSigCycleTimeActive" SG_ 2147484579 Pto1BadCondition 100;
BA_ "GenSigStartValue" SG_ 2147484579 Pto1BadCondition 15;
BA_ "GenSigMaxLatency" SG_ 2147484579 Pto1BadCondition 110;
BA_ "Platform_VMCU1_Sig" SG_ 2147484579 Pto1BadCondition 1;
BA_ "SeToolAncestorID_SIGNAL" SG_ 2147484579 Pto1BadCondition "x0000001D042DDF2A";
BA_ "SeToolItemID_SIGNAL" SG_ 2147484579 Pto1BadCondition "x0000001D042DDF2A";
BA_ "SeToolName_SIGNAL" SG_ 2147484579 Pto1BadCondition "Pto1BadCondition";
BA_ "SeToolVersion_SIGNAL" SG_ 2147484579 Pto1BadCondition "1";
BA_ "GenSigSendType" SG_ 2147484579 PtosStatus_UB_ISig_4 7;
BA_ "Platform_VMCU1_Sig" SG_ 2147484579 PtosStatus_UB_ISig_4 1;
BA_ "GenSigCycleTime" SG_ 2147484579 Pto4BadCondition 100;
BA_ "GenSigCycleTimeActive" SG_ 2147484579 Pto4BadCondition 100;
BA_ "GenSigStartValue" SG_ 2147484579 Pto4BadCondition 15;
BA_ "GenSigMaxLatency" SG_ 2147484579 Pto4BadCondition 110;
BA_ "Platform_VMCU1_Sig" SG_ 2147484579 Pto4BadCondition 1;
BA_ "SeToolAncestorID_SIGNAL" SG_ 2147484579 Pto4BadCondition "x0000001D042DE32A";
BA_ "SeToolItemID_SIGNAL" SG_ 2147484579 Pto4BadCondition "x0000001D042DE32A";
BA_ "SeToolName_SIGNAL" SG_ 2147484579 Pto4BadCondition "Pto4BadCondition";
BA_ "SeToolVersion_SIGNAL" SG_ 2147484579 Pto4BadCondition "1";
BA_ "GenSigCycleTime" SG_ 2147484579 Pto2BadCondition 100;
BA_ "GenSigCycleTimeActive" SG_ 2147484579 Pto2BadCondition 100;
BA_ "GenSigStartValue" SG_ 2147484579 Pto2BadCondition 15;
BA_ "GenSigMaxLatency" SG_ 2147484579 Pto2BadCondition 110;
BA_ "Platform_VMCU1_Sig" SG_ 2147484579 Pto2BadCondition 1;
BA_ "SeToolAncestorID_SIGNAL" SG_ 2147484579 Pto2BadCondition "x0000001D042DE326";
BA_ "SeToolItemID_SIGNAL" SG_ 2147484579 Pto2BadCondition "x0000001D042DE326";
BA_ "SeToolName_SIGNAL" SG_ 2147484579 Pto2BadCondition "Pto2BadCondition";
BA_ "SeToolVersion_SIGNAL" SG_ 2147484579 Pto2BadCondition "1";
BA_ "GenSigCycleTime" SG_ 2147484579 PtoRequest 100;
BA_ "GenSigCycleTimeActive" SG_ 2147484579 PtoRequest 100;
BA_ "GenSigStartValue" SG_ 2147484579 PtoRequest 3;
BA_ "Platform_VMCU1_Sig" SG_ 2147484579 PtoRequest 1;
BA_ "GenSigCycleTime" SG_ 2147484579 Pto2ConsentRequest 100;
BA_ "GenSigCycleTimeActive" SG_ 2147484579 Pto2ConsentRequest 100;
BA_ "GenSigStartValue" SG_ 2147484579 Pto2ConsentRequest 3;
BA_ "GenSigMaxLatency" SG_ 2147484579 Pto2ConsentRequest 110;
BA_ "Platform_VMCU1_Sig" SG_ 2147484579 Pto2ConsentRequest 1;
BA_ "SeToolAncestorID_SIGNAL" SG_ 2147484579 Pto2ConsentRequest "x0000001D04156EA0";
BA_ "SeToolItemID_SIGNAL" SG_ 2147484579 Pto2ConsentRequest "x0000001D043A5C95";
BA_ "SeToolName_SIGNAL" SG_ 2147484579 Pto2ConsentRequest "Pto2ConsentRequest";
BA_ "SeToolVersion_SIGNAL" SG_ 2147484579 Pto2ConsentRequest "2";
BA_ "GenSigCycleTime" SG_ 2147484579 PBStatusDisplay_cmd_ISig_4 100;
BA_ "GenSigCycleTimeActive" SG_ 2147484579 PBStatusDisplay_cmd_ISig_4 100;
BA_ "GenSigStartValue" SG_ 2147484579 PBStatusDisplay_cmd_ISig_4 3;
BA_ "Platform_VMCU1_Sig" SG_ 2147484579 PBStatusDisplay_cmd_ISig_4 1;
BA_ "GenSigCycleTime" SG_ 2147484579 Pto4DrivingRequest 100;
BA_ "GenSigCycleTimeActive" SG_ 2147484579 Pto4DrivingRequest 100;
BA_ "GenSigStartValue" SG_ 2147484579 Pto4DrivingRequest 3;
BA_ "GenSigMaxLatency" SG_ 2147484579 Pto4DrivingRequest 110;
BA_ "Platform_VMCU1_Sig" SG_ 2147484579 Pto4DrivingRequest 1;
BA_ "SeToolAncestorID_SIGNAL" SG_ 2147484579 Pto4DrivingRequest "x0000001D041538FE";
BA_ "SeToolItemID_SIGNAL" SG_ 2147484579 Pto4DrivingRequest "x0000001D041538FE";
BA_ "SeToolName_SIGNAL" SG_ 2147484579 Pto4DrivingRequest "Pto4DrivingRequest";
BA_ "SeToolVersion_SIGNAL" SG_ 2147484579 Pto4DrivingRequest "1";
BA_ "GenSigCycleTime" SG_ 2147484579 Pto3Indication 100;
BA_ "GenSigCycleTimeActive" SG_ 2147484579 Pto3Indication 100;
BA_ "GenSigStartValue" SG_ 2147484579 Pto3Indication 3;
BA_ "Platform_VMCU1_Sig" SG_ 2147484579 Pto3Indication 1;
BA_ "GenSigCycleTime" SG_ 2147484579 Pto2Status_ISig_4 100;
BA_ "GenSigCycleTimeActive" SG_ 2147484579 Pto2Status_ISig_4 100;
BA_ "GenSigStartValue" SG_ 2147484579 Pto2Status_ISig_4 3;
BA_ "GenSigMaxLatency" SG_ 2147484579 Pto2Status_ISig_4 110;
BA_ "Platform_VMCU1_Sig" SG_ 2147484579 Pto2Status_ISig_4 1;
BA_ "SeToolAncestorID_SIGNAL" SG_ 2147484579 Pto2Status_ISig_4 "x0000001D041534A5";
BA_ "SeToolItemID_SIGNAL" SG_ 2147484579 Pto2Status_ISig_4 "x0000001D04321002";
BA_ "SeToolName_SIGNAL" SG_ 2147484579 Pto2Status_ISig_4 "Pto2Status";
BA_ "SeToolVersion_SIGNAL" SG_ 2147484579 Pto2Status_ISig_4 "3";
BA_ "GenSigCycleTime" SG_ 2147484579 Pto4Status_ISig_4 100;
BA_ "GenSigCycleTimeActive" SG_ 2147484579 Pto4Status_ISig_4 100;
BA_ "GenSigStartValue" SG_ 2147484579 Pto4Status_ISig_4 3;
BA_ "GenSigMaxLatency" SG_ 2147484579 Pto4Status_ISig_4 110;
BA_ "Platform_VMCU1_Sig" SG_ 2147484579 Pto4Status_ISig_4 1;
BA_ "SeToolAncestorID_SIGNAL" SG_ 2147484579 Pto4Status_ISig_4 "x0000001D041534AC";
BA_ "SeToolItemID_SIGNAL" SG_ 2147484579 Pto4Status_ISig_4 "x0000001D04321056";
BA_ "SeToolName_SIGNAL" SG_ 2147484579 Pto4Status_ISig_4 "Pto4Status";
BA_ "SeToolVersion_SIGNAL" SG_ 2147484579 Pto4Status_ISig_4 "3";
BA_ "GenSigCycleTime" SG_ 2147484579 RampLevelRequestACK_ISig_4 100;
BA_ "GenSigCycleTimeActive" SG_ 2147484579 RampLevelRequestACK_ISig_4 100;
BA_ "GenSigStartValue" SG_ 2147484579 RampLevelRequestACK_ISig_4 3;
BA_ "Platform_VMCU1_Sig" SG_ 2147484579 RampLevelRequestACK_ISig_4 1;
BA_ "GenSigCycleTime" SG_ 2147484579 Pto3BadCondition 100;
BA_ "GenSigCycleTimeActive" SG_ 2147484579 Pto3BadCondition 100;
BA_ "GenSigStartValue" SG_ 2147484579 Pto3BadCondition 15;
BA_ "GenSigMaxLatency" SG_ 2147484579 Pto3BadCondition 110;
BA_ "Platform_VMCU1_Sig" SG_ 2147484579 Pto3BadCondition 1;
BA_ "SeToolAncestorID_SIGNAL" SG_ 2147484579 Pto3BadCondition "x0000001D042DE328";
BA_ "SeToolItemID_SIGNAL" SG_ 2147484579 Pto3BadCondition "x0000001D042DE328";
BA_ "SeToolName_SIGNAL" SG_ 2147484579 Pto3BadCondition "Pto3BadCondition";
BA_ "SeToolVersion_SIGNAL" SG_ 2147484579 Pto3BadCondition "1";
BA_ "GenSigCycleTime" SG_ 2147484579 PtosStatus_ISig_4 100;
BA_ "GenSigCycleTimeActive" SG_ 2147484579 PtosStatus_ISig_4 100;
BA_ "GenSigStartValue" SG_ 2147484579 PtosStatus_ISig_4 3;
BA_ "GenSigMaxLatency" SG_ 2147484579 PtosStatus_ISig_4 110;
BA_ "NeedsUpdateBit" SG_ 2147484579 PtosStatus_ISig_4 1;
BA_ "Platform_VMCU1_Sig" SG_ 2147484579 PtosStatus_ISig_4 1;
BA_ "SeToolAncestorID_SIGNAL" SG_ 2147484579 PtosStatus_ISig_4 "x0000001D042CA490";
BA_ "SeToolItemID_SIGNAL" SG_ 2147484579 PtosStatus_ISig_4 "x0000001D042CA490";
BA_ "SeToolName_SIGNAL" SG_ 2147484579 PtosStatus_ISig_4 "PtosStatus";
BA_ "SeToolVersion_SIGNAL" SG_ 2147484579 PtosStatus_ISig_4 "1";
BA_ "GenSigCycleTime" SG_ 2147484579 FrontWheelDriveAutoStatus_ISig_4 100;
BA_ "GenSigCycleTimeActive" SG_ 2147484579 FrontWheelDriveAutoStatus_ISig_4 100;
BA_ "GenSigStartValue" SG_ 2147484579 FrontWheelDriveAutoStatus_ISig_4 3;
BA_ "Platform_VMCU1_Sig" SG_ 2147484579 FrontWheelDriveAutoStatus_ISig_4 1;
BA_ "GenSigCycleTime" SG_ 2147484579 Pto1ConsentRequest 100;
BA_ "GenSigCycleTimeActive" SG_ 2147484579 Pto1ConsentRequest 100;
BA_ "GenSigStartValue" SG_ 2147484579 Pto1ConsentRequest 3;
BA_ "GenSigMaxLatency" SG_ 2147484579 Pto1ConsentRequest 110;
BA_ "Platform_VMCU1_Sig" SG_ 2147484579 Pto1ConsentRequest 1;
BA_ "SeToolAncestorID_SIGNAL" SG_ 2147484579 Pto1ConsentRequest "x0000001D04156E9D";
BA_ "SeToolItemID_SIGNAL" SG_ 2147484579 Pto1ConsentRequest "x0000001D043A5C3F";
BA_ "SeToolName_SIGNAL" SG_ 2147484579 Pto1ConsentRequest "Pto1ConsentRequest";
BA_ "SeToolVersion_SIGNAL" SG_ 2147484579 Pto1ConsentRequest "2";
BA_ "GenSigCycleTime" SG_ 2147484579 Pto4Indication 100;
BA_ "GenSigCycleTimeActive" SG_ 2147484579 Pto4Indication 100;
BA_ "GenSigStartValue" SG_ 2147484579 Pto4Indication 3;
BA_ "Platform_VMCU1_Sig" SG_ 2147484579 Pto4Indication 1;
BA_ "GenSigSendType" SG_ 2147484579 Pto1FeedbackStatus_UB_ISig_4 7;
BA_ "Platform_VMCU1_Sig" SG_ 2147484579 Pto1FeedbackStatus_UB_ISig_4 1;
BA_ "GenSigCycleTime" SG_ 2147484579 Pto1Indication 100;
BA_ "GenSigCycleTimeActive" SG_ 2147484579 Pto1Indication 100;
BA_ "GenSigStartValue" SG_ 2147484579 Pto1Indication 3;
BA_ "Platform_VMCU1_Sig" SG_ 2147484579 Pto1Indication 1;
BA_ "GenSigCycleTime" SG_ 2147484579 Pto3Status_ISig_4 100;
BA_ "GenSigCycleTimeActive" SG_ 2147484579 Pto3Status_ISig_4 100;
BA_ "GenSigStartValue" SG_ 2147484579 Pto3Status_ISig_4 3;
BA_ "GenSigMaxLatency" SG_ 2147484579 Pto3Status_ISig_4 110;
BA_ "Platform_VMCU1_Sig" SG_ 2147484579 Pto3Status_ISig_4 1;
BA_ "SeToolAncestorID_SIGNAL" SG_ 2147484579 Pto3Status_ISig_4 "x0000001D041534A7";
BA_ "SeToolItemID_SIGNAL" SG_ 2147484579 Pto3Status_ISig_4 "x0000001D04321034";
BA_ "SeToolName_SIGNAL" SG_ 2147484579 Pto3Status_ISig_4 "Pto3Status";
BA_ "SeToolVersion_SIGNAL" SG_ 2147484579 Pto3Status_ISig_4 "3";
BA_ "GenSigCycleTime" SG_ 2147484579 Pto2Indication 100;
BA_ "GenSigCycleTimeActive" SG_ 2147484579 Pto2Indication 100;
BA_ "GenSigStartValue" SG_ 2147484579 Pto2Indication 3;
BA_ "Platform_VMCU1_Sig" SG_ 2147484579 Pto2Indication 1;
BA_ "GenSigCycleTime" SG_ 2147484579 Pto1FeedbackStatus_ISig_4 100;
BA_ "GenSigCycleTimeActive" SG_ 2147484579 Pto1FeedbackStatus_ISig_4 100;
BA_ "GenSigStartValue" SG_ 2147484579 Pto1FeedbackStatus_ISig_4 3;
BA_ "GenSigMaxLatency" SG_ 2147484579 Pto1FeedbackStatus_ISig_4 110;
BA_ "NeedsUpdateBit" SG_ 2147484579 Pto1FeedbackStatus_ISig_4 1;
BA_ "Platform_VMCU1_Sig" SG_ 2147484579 Pto1FeedbackStatus_ISig_4 1;
BA_ "SeToolAncestorID_SIGNAL" SG_ 2147484579 Pto1FeedbackStatus_ISig_4 "x0000001D041538D8";
BA_ "SeToolItemID_SIGNAL" SG_ 2147484579 Pto1FeedbackStatus_ISig_4 "x0000001D041538D8";
BA_ "SeToolName_SIGNAL" SG_ 2147484579 Pto1FeedbackStatus_ISig_4 "Pto1FeedbackStatus";
BA_ "SeToolVersion_SIGNAL" SG_ 2147484579 Pto1FeedbackStatus_ISig_4 "1";
BA_ "GenSigCycleTime" SG_ 2147484579 TransferCaseOrSplitboxPTOMode_IS 100;
BA_ "GenSigCycleTimeActive" SG_ 2147484579 TransferCaseOrSplitboxPTOMode_IS 100;
BA_ "GenSigStartValue" SG_ 2147484579 TransferCaseOrSplitboxPTOMode_IS 3;
BA_ "Platform_VMCU1_Sig" SG_ 2147484579 TransferCaseOrSplitboxPTOMode_IS 1;
BA_ "SeToolAncestorID_SIGNAL" SG_ 2147484579 TransferCaseOrSplitboxPTOMode_IS "x0000001D0419DC89";
BA_ "SeToolItemID_SIGNAL" SG_ 2147484579 TransferCaseOrSplitboxPTOMode_IS "x0000001D0419DC89";
BA_ "SeToolName_SIGNAL" SG_ 2147484579 TransferCaseOrSplitboxPTOMode_IS "SplitBoxPtoStatus";
BA_ "SeToolVersion_SIGNAL" SG_ 2147484579 TransferCaseOrSplitboxPTOMode_IS "1";
BA_ "SystemSignalLongSymbol" SG_ 2147484579 TransferCaseOrSplitboxPTOMode_IS "TransferCaseOrSplitboxPTOMode_ISig_4";
BA_ "GenSigCycleTime" SG_ 2147484579 DirIndRearLamp_Stat_ISig_4 100;
BA_ "GenSigCycleTimeActive" SG_ 2147484579 DirIndRearLamp_Stat_ISig_4 100;
BA_ "GenSigStartValue" SG_ 2147484579 DirIndRearLamp_Stat_ISig_4 7;
BA_ "Platform_VMCU1_Sig" SG_ 2147484579 DirIndRearLamp_Stat_ISig_4 1;
BA_ "GenSigCycleTime" SG_ 2147484579 Pto1Status_ISig_4 100;
BA_ "GenSigCycleTimeActive" SG_ 2147484579 Pto1Status_ISig_4 100;
BA_ "GenSigStartValue" SG_ 2147484579 Pto1Status_ISig_4 3;
BA_ "GenSigMaxLatency" SG_ 2147484579 Pto1Status_ISig_4 110;
BA_ "Platform_VMCU1_Sig" SG_ 2147484579 Pto1Status_ISig_4 1;
BA_ "SeToolAncestorID_SIGNAL" SG_ 2147484579 Pto1Status_ISig_4 "x0000001D041534A3";
BA_ "SeToolItemID_SIGNAL" SG_ 2147484579 Pto1Status_ISig_4 "x0000001D04320FF9";
BA_ "SeToolName_SIGNAL" SG_ 2147484579 Pto1Status_ISig_4 "Pto1Status";
BA_ "SeToolVersion_SIGNAL" SG_ 2147484579 Pto1Status_ISig_4 "3";
BA_ "GenSigCycleTime" SG_ 2147484579 Pto3DrivingRequest 100;
BA_ "GenSigCycleTimeActive" SG_ 2147484579 Pto3DrivingRequest 100;
BA_ "GenSigStartValue" SG_ 2147484579 Pto3DrivingRequest 3;
BA_ "GenSigMaxLatency" SG_ 2147484579 Pto3DrivingRequest 110;
BA_ "Platform_VMCU1_Sig" SG_ 2147484579 Pto3DrivingRequest 1;
BA_ "SeToolAncestorID_SIGNAL" SG_ 2147484579 Pto3DrivingRequest "x0000001D041538FC";
BA_ "SeToolItemID_SIGNAL" SG_ 2147484579 Pto3DrivingRequest "x0000001D041538FC";
BA_ "SeToolName_SIGNAL" SG_ 2147484579 Pto3DrivingRequest "Pto3DrivingRequest";
BA_ "SeToolVersion_SIGNAL" SG_ 2147484579 Pto3DrivingRequest "1";
BA_ "GenSigCycleTime" SG_ 2147484379 CCBTargetSpeedRequest 100;
BA_ "GenSigCycleTimeActive" SG_ 2147484379 CCBTargetSpeedRequest 100;
BA_ "GenSigStartValue" SG_ 2147484379 CCBTargetSpeedRequest 65535;
BA_ "GenSigMaxLatency" SG_ 2147484379 CCBTargetSpeedRequest 57;
BA_ "Platform_VMCU1_Sig" SG_ 2147484379 CCBTargetSpeedRequest 1;
BA_ "SeToolAncestorID_SIGNAL" SG_ 2147484379 CCBTargetSpeedRequest "x0000001D043FE028";
BA_ "SeToolItemID_SIGNAL" SG_ 2147484379 CCBTargetSpeedRequest "x0000001D043FE028";
BA_ "SeToolName_SIGNAL" SG_ 2147484379 CCBTargetSpeedRequest "CCBTargetSpeedRequest";
BA_ "SeToolVersion_SIGNAL" SG_ 2147484379 CCBTargetSpeedRequest "1";
BA_ "GenSigCycleTime" SG_ 2147484379 EngineStartControlStatus_ISig_4 100;
BA_ "GenSigCycleTimeActive" SG_ 2147484379 EngineStartControlStatus_ISig_4 100;
BA_ "GenSigStartValue" SG_ 2147484379 EngineStartControlStatus_ISig_4 65535;
BA_ "GenSigMaxLatency" SG_ 2147484379 EngineStartControlStatus_ISig_4 57;
BA_ "Platform_VMCU1_Sig" SG_ 2147484379 EngineStartControlStatus_ISig_4 1;
BA_ "SeToolAncestorID_SIGNAL" SG_ 2147484379 EngineStartControlStatus_ISig_4 "x0000001D041E8EE9";
BA_ "SeToolItemID_SIGNAL" SG_ 2147484379 EngineStartControlStatus_ISig_4 "x0000001D0425C909";
BA_ "SeToolName_SIGNAL" SG_ 2147484379 EngineStartControlStatus_ISig_4 "EngineStartControlStatus";
BA_ "SeToolVersion_SIGNAL" SG_ 2147484379 EngineStartControlStatus_ISig_4 "3";
BA_ "GenSigCycleTime" SG_ 2147484379 CCTargetSpeedRequest 100;
BA_ "GenSigCycleTimeActive" SG_ 2147484379 CCTargetSpeedRequest 100;
BA_ "GenSigStartValue" SG_ 2147484379 CCTargetSpeedRequest 65535;
BA_ "GenSigMaxLatency" SG_ 2147484379 CCTargetSpeedRequest 57;
BA_ "Platform_VMCU1_Sig" SG_ 2147484379 CCTargetSpeedRequest 1;
BA_ "SeToolAncestorID_SIGNAL" SG_ 2147484379 CCTargetSpeedRequest "x0000001D043FE024";
BA_ "SeToolItemID_SIGNAL" SG_ 2147484379 CCTargetSpeedRequest "x0000001D043FE024";
BA_ "SeToolName_SIGNAL" SG_ 2147484379 CCTargetSpeedRequest "CCTargetSpeedRequest";
BA_ "SeToolVersion_SIGNAL" SG_ 2147484379 CCTargetSpeedRequest "1";
BA_ "GenSigCycleTime" SG_ 2147484373 StoreIdleValue 100;
BA_ "GenSigCycleTimeActive" SG_ 2147484373 StoreIdleValue 100;
BA_ "GenSigStartValue" SG_ 2147484373 StoreIdleValue 3;
BA_ "Platform_VMCU1_Sig" SG_ 2147484373 StoreIdleValue 1;
BA_ "GenSigSendType" SG_ 2147484373 TrailerConnected_UB_ISig_4 7;
BA_ "Platform_VMCU1_Sig" SG_ 2147484373 TrailerConnected_UB_ISig_4 1;
BA_ "GenSigCycleTime" SG_ 2147484373 ESCReqEMS_CtrlTrimMode_ISig_4 100;
BA_ "GenSigCycleTimeActive" SG_ 2147484373 ESCReqEMS_CtrlTrimMode_ISig_4 100;
BA_ "GenSigStartValue" SG_ 2147484373 ESCReqEMS_CtrlTrimMode_ISig_4 15;
BA_ "GenSigMaxLatency" SG_ 2147484373 ESCReqEMS_CtrlTrimMode_ISig_4 56;
BA_ "Platform_VMCU1_Sig" SG_ 2147484373 ESCReqEMS_CtrlTrimMode_ISig_4 1;
BA_ "SeToolAncestorID_SIGNAL" SG_ 2147484373 ESCReqEMS_CtrlTrimMode_ISig_4 "x0000001D042A710F";
BA_ "SeToolItemID_SIGNAL" SG_ 2147484373 ESCReqEMS_CtrlTrimMode_ISig_4 "x0000001D042A710F";
BA_ "SeToolName_SIGNAL" SG_ 2147484373 ESCReqEMS_CtrlTrimMode_ISig_4 "CtrlTrimMode";
BA_ "SeToolOwnerSigGroupID_SIGNAL" SG_ 2147484373 ESCReqEMS_CtrlTrimMode_ISig_4 "x0000001D043D5DDC";
BA_ "SeToolOwnerSigGroup_SIGNAL" SG_ 2147484373 ESCReqEMS_CtrlTrimMode_ISig_4 "ESCReqEMS";
BA_ "SeToolVersion_SIGNAL" SG_ 2147484373 ESCReqEMS_CtrlTrimMode_ISig_4 "1";
BA_ "GenSigCycleTime" SG_ 2147484373 ESCReqESC_CtrlTrimMode_ISig_4 100;
BA_ "GenSigCycleTimeActive" SG_ 2147484373 ESCReqESC_CtrlTrimMode_ISig_4 100;
BA_ "GenSigStartValue" SG_ 2147484373 ESCReqESC_CtrlTrimMode_ISig_4 15;
BA_ "GenSigMaxLatency" SG_ 2147484373 ESCReqESC_CtrlTrimMode_ISig_4 56;
BA_ "Platform_VMCU1_Sig" SG_ 2147484373 ESCReqESC_CtrlTrimMode_ISig_4 1;
BA_ "SeToolAncestorID_SIGNAL" SG_ 2147484373 ESCReqESC_CtrlTrimMode_ISig_4 "x0000001D042A710F";
BA_ "SeToolItemID_SIGNAL" SG_ 2147484373 ESCReqESC_CtrlTrimMode_ISig_4 "x0000001D042A710F";
BA_ "SeToolName_SIGNAL" SG_ 2147484373 ESCReqESC_CtrlTrimMode_ISig_4 "CtrlTrimMode";
BA_ "SeToolOwnerSigGroupID_SIGNAL" SG_ 2147484373 ESCReqESC_CtrlTrimMode_ISig_4 "x0000001D043D5DD2";
BA_ "SeToolOwnerSigGroup_SIGNAL" SG_ 2147484373 ESCReqESC_CtrlTrimMode_ISig_4 "ESCReqESC";
BA_ "SeToolVersion_SIGNAL" SG_ 2147484373 ESCReqESC_CtrlTrimMode_ISig_4 "1";
BA_ "GenSigCycleTime" SG_ 2147484373 ESCReqEMS_CtrlTrimStat_ISig_4 100;
BA_ "GenSigCycleTimeActive" SG_ 2147484373 ESCReqEMS_CtrlTrimStat_ISig_4 100;
BA_ "GenSigStartValue" SG_ 2147484373 ESCReqEMS_CtrlTrimStat_ISig_4 7;
BA_ "GenSigMaxLatency" SG_ 2147484373 ESCReqEMS_CtrlTrimStat_ISig_4 56;
BA_ "Platform_VMCU1_Sig" SG_ 2147484373 ESCReqEMS_CtrlTrimStat_ISig_4 1;
BA_ "SeToolAncestorID_SIGNAL" SG_ 2147484373 ESCReqEMS_CtrlTrimStat_ISig_4 "x0000001D042A710D";
BA_ "SeToolItemID_SIGNAL" SG_ 2147484373 ESCReqEMS_CtrlTrimStat_ISig_4 "x0000001D042A710D";
BA_ "SeToolName_SIGNAL" SG_ 2147484373 ESCReqEMS_CtrlTrimStat_ISig_4 "CtrlTrimStat";
BA_ "SeToolOwnerSigGroupID_SIGNAL" SG_ 2147484373 ESCReqEMS_CtrlTrimStat_ISig_4 "x0000001D043D5DDC";
BA_ "SeToolOwnerSigGroup_SIGNAL" SG_ 2147484373 ESCReqEMS_CtrlTrimStat_ISig_4 "ESCReqEMS";
BA_ "SeToolVersion_SIGNAL" SG_ 2147484373 ESCReqEMS_CtrlTrimStat_ISig_4 "1";
BA_ "GenSigCycleTime" SG_ 2147484373 TrailerConnected_ISig_4 100;
BA_ "GenSigCycleTimeActive" SG_ 2147484373 TrailerConnected_ISig_4 100;
BA_ "GenSigStartValue" SG_ 2147484373 TrailerConnected_ISig_4 3;
BA_ "NeedsUpdateBit" SG_ 2147484373 TrailerConnected_ISig_4 1;
BA_ "Platform_VMCU1_Sig" SG_ 2147484373 TrailerConnected_ISig_4 1;
BA_ "GenSigCycleTime" SG_ 2147484373 ESCReqESC_CtrlTrimValue_ISig_4 100;
BA_ "GenSigCycleTimeActive" SG_ 2147484373 ESCReqESC_CtrlTrimValue_ISig_4 100;
BA_ "GenSigStartValue" SG_ 2147484373 ESCReqESC_CtrlTrimValue_ISig_4 255;
BA_ "GenSigMaxLatency" SG_ 2147484373 ESCReqESC_CtrlTrimValue_ISig_4 56;
BA_ "Platform_VMCU1_Sig" SG_ 2147484373 ESCReqESC_CtrlTrimValue_ISig_4 1;
BA_ "SeToolAncestorID_SIGNAL" SG_ 2147484373 ESCReqESC_CtrlTrimValue_ISig_4 "x0000001D042A7114";
BA_ "SeToolItemID_SIGNAL" SG_ 2147484373 ESCReqESC_CtrlTrimValue_ISig_4 "x0000001D042A7114";
BA_ "SeToolName_SIGNAL" SG_ 2147484373 ESCReqESC_CtrlTrimValue_ISig_4 "CtrlTrimValue";
BA_ "SeToolOwnerSigGroupID_SIGNAL" SG_ 2147484373 ESCReqESC_CtrlTrimValue_ISig_4 "x0000001D043D5DD2";
BA_ "SeToolOwnerSigGroup_SIGNAL" SG_ 2147484373 ESCReqESC_CtrlTrimValue_ISig_4 "ESCReqESC";
BA_ "SeToolVersion_SIGNAL" SG_ 2147484373 ESCReqESC_CtrlTrimValue_ISig_4 "1";
BA_ "GenSigSendType" SG_ 2147484373 BrakeLight_rqst_UB_ISig_4 7;
BA_ "Platform_VMCU1_Sig" SG_ 2147484373 BrakeLight_rqst_UB_ISig_4 1;
BA_ "GenSigCycleTime" SG_ 2147484373 ESCReqESC_CtrlTrimStat_ISig_4 100;
BA_ "GenSigCycleTimeActive" SG_ 2147484373 ESCReqESC_CtrlTrimStat_ISig_4 100;
BA_ "GenSigStartValue" SG_ 2147484373 ESCReqESC_CtrlTrimStat_ISig_4 7;
BA_ "GenSigMaxLatency" SG_ 2147484373 ESCReqESC_CtrlTrimStat_ISig_4 56;
BA_ "Platform_VMCU1_Sig" SG_ 2147484373 ESCReqESC_CtrlTrimStat_ISig_4 1;
BA_ "SeToolAncestorID_SIGNAL" SG_ 2147484373 ESCReqESC_CtrlTrimStat_ISig_4 "x0000001D042A710D";
BA_ "SeToolItemID_SIGNAL" SG_ 2147484373 ESCReqESC_CtrlTrimStat_ISig_4 "x0000001D042A710D";
BA_ "SeToolName_SIGNAL" SG_ 2147484373 ESCReqESC_CtrlTrimStat_ISig_4 "CtrlTrimStat";
BA_ "SeToolOwnerSigGroupID_SIGNAL" SG_ 2147484373 ESCReqESC_CtrlTrimStat_ISig_4 "x0000001D043D5DD2";
BA_ "SeToolOwnerSigGroup_SIGNAL" SG_ 2147484373 ESCReqESC_CtrlTrimStat_ISig_4 "ESCReqESC";
BA_ "SeToolVersion_SIGNAL" SG_ 2147484373 ESCReqESC_CtrlTrimStat_ISig_4 "1";
BA_ "GenSigCycleTime" SG_ 2147484373 SCLLogicEnable_rqst 100;
BA_ "GenSigCycleTimeActive" SG_ 2147484373 SCLLogicEnable_rqst 100;
BA_ "GenSigStartValue" SG_ 2147484373 SCLLogicEnable_rqst 7;
BA_ "GenSigMaxLatency" SG_ 2147484373 SCLLogicEnable_rqst 55;
BA_ "Platform_VMCU1_Sig" SG_ 2147484373 SCLLogicEnable_rqst 1;
BA_ "SeToolAncestorID_SIGNAL" SG_ 2147484373 SCLLogicEnable_rqst "x0000001D043B4FEF";
BA_ "SeToolItemID_SIGNAL" SG_ 2147484373 SCLLogicEnable_rqst "x0000001D043FB671";
BA_ "SeToolName_SIGNAL" SG_ 2147484373 SCLLogicEnable_rqst "SCLLogicEnable_rqst";
BA_ "SeToolVersion_SIGNAL" SG_ 2147484373 SCLLogicEnable_rqst "2";
BA_ "GenSigCycleTime" SG_ 2147484373 ESCReqESC_CtrlTrimReq_ISig_4 100;
BA_ "GenSigCycleTimeActive" SG_ 2147484373 ESCReqESC_CtrlTrimReq_ISig_4 100;
BA_ "GenSigStartValue" SG_ 2147484373 ESCReqESC_CtrlTrimReq_ISig_4 7;
BA_ "GenSigMaxLatency" SG_ 2147484373 ESCReqESC_CtrlTrimReq_ISig_4 56;
BA_ "Platform_VMCU1_Sig" SG_ 2147484373 ESCReqESC_CtrlTrimReq_ISig_4 1;
BA_ "SeToolAncestorID_SIGNAL" SG_ 2147484373 ESCReqESC_CtrlTrimReq_ISig_4 "x0000001D042A710B";
BA_ "SeToolItemID_SIGNAL" SG_ 2147484373 ESCReqESC_CtrlTrimReq_ISig_4 "x0000001D042A710B";
BA_ "SeToolName_SIGNAL" SG_ 2147484373 ESCReqESC_CtrlTrimReq_ISig_4 "CtrlTrimReq";
BA_ "SeToolOwnerSigGroupID_SIGNAL" SG_ 2147484373 ESCReqESC_CtrlTrimReq_ISig_4 "x0000001D043D5DD2";
BA_ "SeToolOwnerSigGroup_SIGNAL" SG_ 2147484373 ESCReqESC_CtrlTrimReq_ISig_4 "ESCReqESC";
BA_ "SeToolVersion_SIGNAL" SG_ 2147484373 ESCReqESC_CtrlTrimReq_ISig_4 "1";
BA_ "GenSigCycleTime" SG_ 2147484373 BrakeLight_rqst_ISig_4 100;
BA_ "GenSigCycleTimeActive" SG_ 2147484373 BrakeLight_rqst_ISig_4 100;
BA_ "GenSigStartValue" SG_ 2147484373 BrakeLight_rqst_ISig_4 7;
BA_ "NeedsUpdateBit" SG_ 2147484373 BrakeLight_rqst_ISig_4 1;
BA_ "Platform_VMCU1_Sig" SG_ 2147484373 BrakeLight_rqst_ISig_4 1;
BA_ "GenSigCycleTime" SG_ 2147484373 ESCReqEMS_CtrlTrimValue_ISig_4 100;
BA_ "GenSigCycleTimeActive" SG_ 2147484373 ESCReqEMS_CtrlTrimValue_ISig_4 100;
BA_ "GenSigStartValue" SG_ 2147484373 ESCReqEMS_CtrlTrimValue_ISig_4 255;
BA_ "GenSigMaxLatency" SG_ 2147484373 ESCReqEMS_CtrlTrimValue_ISig_4 56;
BA_ "Platform_VMCU1_Sig" SG_ 2147484373 ESCReqEMS_CtrlTrimValue_ISig_4 1;
BA_ "SeToolAncestorID_SIGNAL" SG_ 2147484373 ESCReqEMS_CtrlTrimValue_ISig_4 "x0000001D042A7114";
BA_ "SeToolItemID_SIGNAL" SG_ 2147484373 ESCReqEMS_CtrlTrimValue_ISig_4 "x0000001D042A7114";
BA_ "SeToolName_SIGNAL" SG_ 2147484373 ESCReqEMS_CtrlTrimValue_ISig_4 "CtrlTrimValue";
BA_ "SeToolOwnerSigGroupID_SIGNAL" SG_ 2147484373 ESCReqEMS_CtrlTrimValue_ISig_4 "x0000001D043D5DDC";
BA_ "SeToolOwnerSigGroup_SIGNAL" SG_ 2147484373 ESCReqEMS_CtrlTrimValue_ISig_4 "ESCReqEMS";
BA_ "SeToolVersion_SIGNAL" SG_ 2147484373 ESCReqEMS_CtrlTrimValue_ISig_4 "1";
BA_ "GenSigCycleTime" SG_ 2147484373 ESCReqEMS_CtrlTrimReq_ISig_4 100;
BA_ "GenSigCycleTimeActive" SG_ 2147484373 ESCReqEMS_CtrlTrimReq_ISig_4 100;
BA_ "GenSigStartValue" SG_ 2147484373 ESCReqEMS_CtrlTrimReq_ISig_4 7;
BA_ "GenSigMaxLatency" SG_ 2147484373 ESCReqEMS_CtrlTrimReq_ISig_4 56;
BA_ "Platform_VMCU1_Sig" SG_ 2147484373 ESCReqEMS_CtrlTrimReq_ISig_4 1;
BA_ "SeToolAncestorID_SIGNAL" SG_ 2147484373 ESCReqEMS_CtrlTrimReq_ISig_4 "x0000001D042A710B";
BA_ "SeToolItemID_SIGNAL" SG_ 2147484373 ESCReqEMS_CtrlTrimReq_ISig_4 "x0000001D042A710B";
BA_ "SeToolName_SIGNAL" SG_ 2147484373 ESCReqEMS_CtrlTrimReq_ISig_4 "CtrlTrimReq";
BA_ "SeToolOwnerSigGroupID_SIGNAL" SG_ 2147484373 ESCReqEMS_CtrlTrimReq_ISig_4 "x0000001D043D5DDC";
BA_ "SeToolOwnerSigGroup_SIGNAL" SG_ 2147484373 ESCReqEMS_CtrlTrimReq_ISig_4 "ESCReqEMS";
BA_ "SeToolVersion_SIGNAL" SG_ 2147484373 ESCReqEMS_CtrlTrimReq_ISig_4 "1";
BA_ "GenSigCycleTime" SG_ 2147484369 TrailerTest_stat 100;
BA_ "GenSigCycleTimeActive" SG_ 2147484369 TrailerTest_stat 100;
BA_ "GenSigStartValue" SG_ 2147484369 TrailerTest_stat 7;
BA_ "GenSigMaxLatency" SG_ 2147484369 TrailerTest_stat 55;
BA_ "Platform_VMCU1_Sig" SG_ 2147484369 TrailerTest_stat 1;
BA_ "SeToolAncestorID_SIGNAL" SG_ 2147484369 TrailerTest_stat "x0000001D042E1ADE";
BA_ "SeToolItemID_SIGNAL" SG_ 2147484369 TrailerTest_stat "x0000001D042E1ADE";
BA_ "SeToolName_SIGNAL" SG_ 2147484369 TrailerTest_stat "TrailerTest_stat";
BA_ "SeToolVersion_SIGNAL" SG_ 2147484369 TrailerTest_stat "1";
BA_ "GenSigCycleTime" SG_ 2147484369 Washing_HMI_rqst_ISig_4 100;
BA_ "GenSigCycleTimeActive" SG_ 2147484369 Washing_HMI_rqst_ISig_4 100;
BA_ "GenSigStartValue" SG_ 2147484369 Washing_HMI_rqst_ISig_4 3;
BA_ "Platform_VMCU1_Sig" SG_ 2147484369 Washing_HMI_rqst_ISig_4 1;
BA_ "GenSigCycleTime" SG_ 2147484369 AuxBrakesDwngrdModeInd_rqst 100;
BA_ "GenSigCycleTimeActive" SG_ 2147484369 AuxBrakesDwngrdModeInd_rqst 100;
BA_ "GenSigStartValue" SG_ 2147484369 AuxBrakesDwngrdModeInd_rqst 7;
BA_ "GenSigMaxLatency" SG_ 2147484369 AuxBrakesDwngrdModeInd_rqst 55;
BA_ "Platform_VMCU1_Sig" SG_ 2147484369 AuxBrakesDwngrdModeInd_rqst 1;
BA_ "SeToolAncestorID_SIGNAL" SG_ 2147484369 AuxBrakesDwngrdModeInd_rqst "x0000001D0414CED7";
BA_ "SeToolItemID_SIGNAL" SG_ 2147484369 AuxBrakesDwngrdModeInd_rqst "x0000001D04327A04";
BA_ "SeToolName_SIGNAL" SG_ 2147484369 AuxBrakesDwngrdModeInd_rqst "AuxBrakesDowngradedModeIndicationReq";
BA_ "SeToolVersion_SIGNAL" SG_ 2147484369 AuxBrakesDwngrdModeInd_rqst "2";
BA_ "GenSigCycleTime" SG_ 2147484369 XRSLTargetSpeedRequest 100;
BA_ "GenSigCycleTimeActive" SG_ 2147484369 XRSLTargetSpeedRequest 100;
BA_ "GenSigStartValue" SG_ 2147484369 XRSLTargetSpeedRequest 65535;
BA_ "Platform_VMCU1_Sig" SG_ 2147484369 XRSLTargetSpeedRequest 1;
BA_ "GenSigCycleTime" SG_ 2147484369 DirInd_StalkStatus_1 100;
BA_ "GenSigCycleTimeActive" SG_ 2147484369 DirInd_StalkStatus_1 100;
BA_ "GenSigStartValue" SG_ 2147484369 DirInd_StalkStatus_1 7;
BA_ "SeToolAncestorID_SIGNAL" SG_ 2147484369 DirInd_StalkStatus_1 "x0000001D04261502";
BA_ "SeToolItemID_SIGNAL" SG_ 2147484369 DirInd_StalkStatus_1 "x0000001D043A8A48";
BA_ "SeToolName_SIGNAL" SG_ 2147484369 DirInd_StalkStatus_1 "DirInd_StalkStatus_1";
BA_ "SeToolVersion_SIGNAL" SG_ 2147484369 DirInd_StalkStatus_1 "3";
BA_ "GenSigCycleTime" SG_ 2147484369 XPRsystemstate_ISig_4 100;
BA_ "GenSigCycleTimeActive" SG_ 2147484369 XPRsystemstate_ISig_4 100;
BA_ "GenSigStartValue" SG_ 2147484369 XPRsystemstate_ISig_4 255;
BA_ "Platform_VMCU1_Sig" SG_ 2147484369 XPRsystemstate_ISig_4 1;
BA_ "GenSigCycleTime" SG_ 2147484369 KeyAuthentication_rqst 100;
BA_ "GenSigCycleTimeActive" SG_ 2147484369 KeyAuthentication_rqst 100;
BA_ "GenSigStartValue" SG_ 2147484369 KeyAuthentication_rqst 7;
BA_ "Platform_VMCU1_Sig" SG_ 2147484369 KeyAuthentication_rqst 1;
BA_ "GenSigCycleTime" SG_ 2147484369 EngineSpeedControlStatus 100;
BA_ "GenSigCycleTimeActive" SG_ 2147484369 EngineSpeedControlStatus 100;
BA_ "GenSigStartValue" SG_ 2147484369 EngineSpeedControlStatus 7;
BA_ "GenSigMaxLatency" SG_ 2147484369 EngineSpeedControlStatus 55;
BA_ "Platform_VMCU1_Sig" SG_ 2147484369 EngineSpeedControlStatus 1;
BA_ "SeToolAncestorID_SIGNAL" SG_ 2147484369 EngineSpeedControlStatus "x0000001D04154AB5";
BA_ "SeToolItemID_SIGNAL" SG_ 2147484369 EngineSpeedControlStatus "x0000001D043DFB57";
BA_ "SeToolName_SIGNAL" SG_ 2147484369 EngineSpeedControlStatus "EngineSpeedControlStatus";
BA_ "SeToolVersion_SIGNAL" SG_ 2147484369 EngineSpeedControlStatus "2";
BA_ "GenSigCycleTime" SG_ 2147484369 SecondThrottle 100;
BA_ "GenSigCycleTimeActive" SG_ 2147484369 SecondThrottle 100;
BA_ "GenSigStartValue" SG_ 2147484369 SecondThrottle 3;
BA_ "GenSigMaxLatency" SG_ 2147484369 SecondThrottle 55;
BA_ "Platform_VMCU1_Sig" SG_ 2147484369 SecondThrottle 1;
BA_ "SeToolAncestorID_SIGNAL" SG_ 2147484369 SecondThrottle "x0000001D0425A500";
BA_ "SeToolItemID_SIGNAL" SG_ 2147484369 SecondThrottle "x0000001D0425A500";
BA_ "SeToolName_SIGNAL" SG_ 2147484369 SecondThrottle "SecondThrottle";
BA_ "SeToolVersion_SIGNAL" SG_ 2147484369 SecondThrottle "1";
BA_ "GenSigCycleTime" SG_ 2147484369 PredeliveryModeIndication_cmd 100;
BA_ "GenSigCycleTimeActive" SG_ 2147484369 PredeliveryModeIndication_cmd 100;
BA_ "GenSigStartValue" SG_ 2147484369 PredeliveryModeIndication_cmd 3;
BA_ "Platform_VMCU1_Sig" SG_ 2147484369 PredeliveryModeIndication_cmd 1;
BA_ "GenSigCycleTime" SG_ 2147484369 LoadCutOffIndication_cmd_ISig_4 100;
BA_ "GenSigCycleTimeActive" SG_ 2147484369 LoadCutOffIndication_cmd_ISig_4 100;
BA_ "GenSigStartValue" SG_ 2147484369 LoadCutOffIndication_cmd_ISig_4 3;
BA_ "Platform_VMCU1_Sig" SG_ 2147484369 LoadCutOffIndication_cmd_ISig_4 1;
BA_ "GenSigCycleTime" SG_ 2147484369 ExitPreDeliveryModeHMI_rqst_ISig 100;
BA_ "GenSigCycleTimeActive" SG_ 2147484369 ExitPreDeliveryModeHMI_rqst_ISig 100;
BA_ "GenSigStartValue" SG_ 2147484369 ExitPreDeliveryModeHMI_rqst_ISig 3;
BA_ "Platform_VMCU1_Sig" SG_ 2147484369 ExitPreDeliveryModeHMI_rqst_ISig 1;
BA_ "SystemSignalLongSymbol" SG_ 2147484369 ExitPreDeliveryModeHMI_rqst_ISig "ExitPreDeliveryModeHMI_rqst_ISig_4";
BA_ "GenSigCycleTime" SG_ 2147484369 FdEquipmentStatus1_ISig_4 100;
BA_ "GenSigCycleTimeActive" SG_ 2147484369 FdEquipmentStatus1_ISig_4 100;
BA_ "GenSigStartValue" SG_ 2147484369 FdEquipmentStatus1_ISig_4 3;
BA_ "GenSigMaxLatency" SG_ 2147484369 FdEquipmentStatus1_ISig_4 55;
BA_ "Platform_VMCU1_Sig" SG_ 2147484369 FdEquipmentStatus1_ISig_4 1;
BA_ "SeToolAncestorID_SIGNAL" SG_ 2147484369 FdEquipmentStatus1_ISig_4 "x0000001D041709FA";
BA_ "SeToolItemID_SIGNAL" SG_ 2147484369 FdEquipmentStatus1_ISig_4 "x0000001D041709FA";
BA_ "SeToolName_SIGNAL" SG_ 2147484369 FdEquipmentStatus1_ISig_4 "FdEquipmentStatus1";
BA_ "SeToolVersion_SIGNAL" SG_ 2147484369 FdEquipmentStatus1_ISig_4 "1";
BA_ "GenSigCycleTime" SG_ 2147484182 ParkBrakeAlert_ISig_4 100;
BA_ "GenSigCycleTimeActive" SG_ 2147484182 ParkBrakeAlert_ISig_4 100;
BA_ "GenSigStartValue" SG_ 2147484182 ParkBrakeAlert_ISig_4 3;
BA_ "Platform_VMCU1_Sig" SG_ 2147484182 ParkBrakeAlert_ISig_4 1;
BA_ "GenSigCycleTime" SG_ 2147484182 IntLightMode_CoreRqst_IL_Mode 100;
BA_ "GenSigCycleTimeActive" SG_ 2147484182 IntLightMode_CoreRqst_IL_Mode 100;
BA_ "GenSigStartValue" SG_ 2147484182 IntLightMode_CoreRqst_IL_Mode 7;
BA_ "Platform_VMCU1_Sig" SG_ 2147484182 IntLightMode_CoreRqst_IL_Mode 1;
BA_ "GenSigSendType" SG_ 2147484182 WiperModeStatus_UB_ISig_4 7;
BA_ "Platform_VMCU1_Sig" SG_ 2147484182 WiperModeStatus_UB_ISig_4 1;
BA_ "GenSigCycleTime" SG_ 2147484182 SteeringColumnLockErrInd_rqst 100;
BA_ "GenSigCycleTimeActive" SG_ 2147484182 SteeringColumnLockErrInd_rqst 100;
BA_ "GenSigStartValue" SG_ 2147484182 SteeringColumnLockErrInd_rqst 7;
BA_ "GenSigMaxLatency" SG_ 2147484182 SteeringColumnLockErrInd_rqst 29;
BA_ "Platform_VMCU1_Sig" SG_ 2147484182 SteeringColumnLockErrInd_rqst 1;
BA_ "SeToolAncestorID_SIGNAL" SG_ 2147484182 SteeringColumnLockErrInd_rqst "x0000001D0419C337";
BA_ "SeToolItemID_SIGNAL" SG_ 2147484182 SteeringColumnLockErrInd_rqst "x0000001D0419C337";
BA_ "SeToolName_SIGNAL" SG_ 2147484182 SteeringColumnLockErrInd_rqst "SteeringColumnLockErrorIndication_rqst";
BA_ "SeToolVersion_SIGNAL" SG_ 2147484182 SteeringColumnLockErrInd_rqst "1";
BA_ "GenSigCycleTime" SG_ 2147484182 ParkingLight_Indication 100;
BA_ "GenSigCycleTimeActive" SG_ 2147484182 ParkingLight_Indication 100;
BA_ "GenSigStartValue" SG_ 2147484182 ParkingLight_Indication 3;
BA_ "GenSigMaxLatency" SG_ 2147484182 ParkingLight_Indication 29;
BA_ "Platform_VMCU1_Sig" SG_ 2147484182 ParkingLight_Indication 1;
BA_ "SeToolAncestorID_SIGNAL" SG_ 2147484182 ParkingLight_Indication "x0000001D041A7C03";
BA_ "SeToolItemID_SIGNAL" SG_ 2147484182 ParkingLight_Indication "x0000001D043C4080";
BA_ "SeToolName_SIGNAL" SG_ 2147484182 ParkingLight_Indication "ParkingLight_Indication";
BA_ "SeToolVersion_SIGNAL" SG_ 2147484182 ParkingLight_Indication "3";
BA_ "GenSigCycleTime" SG_ 2147484182 DaytimeRunningLight_Indication 100;
BA_ "GenSigCycleTimeActive" SG_ 2147484182 DaytimeRunningLight_Indication 100;
BA_ "GenSigStartValue" SG_ 2147484182 DaytimeRunningLight_Indication 3;
BA_ "GenSigMaxLatency" SG_ 2147484182 DaytimeRunningLight_Indication 29;
BA_ "Platform_VMCU1_Sig" SG_ 2147484182 DaytimeRunningLight_Indication 1;
BA_ "SeToolAncestorID_SIGNAL" SG_ 2147484182 DaytimeRunningLight_Indication "x0000001D041A7C03";
BA_ "SeToolItemID_SIGNAL" SG_ 2147484182 DaytimeRunningLight_Indication "x0000001D043C4080";
BA_ "SeToolName_SIGNAL" SG_ 2147484182 DaytimeRunningLight_Indication "DaytimeRunningLight_Indication";
BA_ "SeToolVersion_SIGNAL" SG_ 2147484182 DaytimeRunningLight_Indication "3";
BA_ "GenSigCycleTime" SG_ 2147484182 EPBBackupMode_ISig_4 100;
BA_ "GenSigCycleTimeActive" SG_ 2147484182 EPBBackupMode_ISig_4 100;
BA_ "GenSigStartValue" SG_ 2147484182 EPBBackupMode_ISig_4 15;
BA_ "Platform_VMCU1_Sig" SG_ 2147484182 EPBBackupMode_ISig_4 1;
BA_ "GenSigCycleTime" SG_ 2147484182 WiperModeStatus_ISig_4 100;
BA_ "GenSigCycleTimeActive" SG_ 2147484182 WiperModeStatus_ISig_4 100;
BA_ "GenSigStartValue" SG_ 2147484182 WiperModeStatus_ISig_4 7;
BA_ "GenSigMaxLatency" SG_ 2147484182 WiperModeStatus_ISig_4 29;
BA_ "NeedsUpdateBit" SG_ 2147484182 WiperModeStatus_ISig_4 1;
BA_ "Platform_VMCU1_Sig" SG_ 2147484182 WiperModeStatus_ISig_4 1;
BA_ "SeToolAncestorID_SIGNAL" SG_ 2147484182 WiperModeStatus_ISig_4 "x0000001D0410D271";
BA_ "SeToolItemID_SIGNAL" SG_ 2147484182 WiperModeStatus_ISig_4 "x0000001D0410D271";
BA_ "SeToolName_SIGNAL" SG_ 2147484182 WiperModeStatus_ISig_4 "WiperModeStatus";
BA_ "SeToolVersion_SIGNAL" SG_ 2147484182 WiperModeStatus_ISig_4 "1";
BA_ "GenSigCycleTime" SG_ 2147484182 FrontFog_Indication 100;
BA_ "GenSigCycleTimeActive" SG_ 2147484182 FrontFog_Indication 100;
BA_ "GenSigStartValue" SG_ 2147484182 FrontFog_Indication 3;
BA_ "GenSigMaxLatency" SG_ 2147484182 FrontFog_Indication 29;
BA_ "Platform_VMCU1_Sig" SG_ 2147484182 FrontFog_Indication 1;
BA_ "SeToolAncestorID_SIGNAL" SG_ 2147484182 FrontFog_Indication "x0000001D041A7C03";
BA_ "SeToolItemID_SIGNAL" SG_ 2147484182 FrontFog_Indication "x0000001D043C4080";
BA_ "SeToolName_SIGNAL" SG_ 2147484182 FrontFog_Indication "FrontFog_Indication";
BA_ "SeToolVersion_SIGNAL" SG_ 2147484182 FrontFog_Indication "3";
BA_ "GenSigCycleTime" SG_ 2147484182 PBReleaseAcceptance_stat_ISig_4 100;
BA_ "GenSigCycleTimeActive" SG_ 2147484182 PBReleaseAcceptance_stat_ISig_4 100;
BA_ "GenSigStartValue" SG_ 2147484182 PBReleaseAcceptance_stat_ISig_4 7;
BA_ "Platform_VMCU1_Sig" SG_ 2147484182 PBReleaseAcceptance_stat_ISig_4 1;
BA_ "GenSigSendType" SG_ 2147484182 ParkingBrake_stat_UB_ISig_4 7;
BA_ "Platform_VMCU1_Sig" SG_ 2147484182 ParkingBrake_stat_UB_ISig_4 1;
BA_ "GenSigCycleTime" SG_ 2147484182 DrivingLightPlus_Indication 100;
BA_ "GenSigCycleTimeActive" SG_ 2147484182 DrivingLightPlus_Indication 100;
BA_ "GenSigStartValue" SG_ 2147484182 DrivingLightPlus_Indication 3;
BA_ "GenSigMaxLatency" SG_ 2147484182 DrivingLightPlus_Indication 29;
BA_ "Platform_VMCU1_Sig" SG_ 2147484182 DrivingLightPlus_Indication 1;
BA_ "SeToolAncestorID_SIGNAL" SG_ 2147484182 DrivingLightPlus_Indication "x0000001D041A7C03";
BA_ "SeToolItemID_SIGNAL" SG_ 2147484182 DrivingLightPlus_Indication "x0000001D043C4080";
BA_ "SeToolName_SIGNAL" SG_ 2147484182 DrivingLightPlus_Indication "DrivingLightPlus_Indication";
BA_ "SeToolVersion_SIGNAL" SG_ 2147484182 DrivingLightPlus_Indication "3";
BA_ "GenSigCycleTime" SG_ 2147484182 IntLightMode_CoreRqst_EventFlag 100;
BA_ "GenSigCycleTimeActive" SG_ 2147484182 IntLightMode_CoreRqst_EventFlag 100;
BA_ "Platform_VMCU1_Sig" SG_ 2147484182 IntLightMode_CoreRqst_EventFlag 1;
BA_ "GenSigCycleTime" SG_ 2147484182 ParkingBrake_stat_ISig_4 100;
BA_ "GenSigCycleTimeActive" SG_ 2147484182 ParkingBrake_stat_ISig_4 100;
BA_ "GenSigStartValue" SG_ 2147484182 ParkingBrake_stat_ISig_4 3;
BA_ "NeedsUpdateBit" SG_ 2147484182 ParkingBrake_stat_ISig_4 1;
BA_ "Platform_VMCU1_Sig" SG_ 2147484182 ParkingBrake_stat_ISig_4 1;
BA_ "GenSigCycleTime" SG_ 2147484182 DrivingLight_Indication 100;
BA_ "GenSigCycleTimeActive" SG_ 2147484182 DrivingLight_Indication 100;
BA_ "GenSigStartValue" SG_ 2147484182 DrivingLight_Indication 3;
BA_ "GenSigMaxLatency" SG_ 2147484182 DrivingLight_Indication 29;
BA_ "Platform_VMCU1_Sig" SG_ 2147484182 DrivingLight_Indication 1;
BA_ "SeToolAncestorID_SIGNAL" SG_ 2147484182 DrivingLight_Indication "x0000001D041A7C03";
BA_ "SeToolItemID_SIGNAL" SG_ 2147484182 DrivingLight_Indication "x0000001D043C4080";
BA_ "SeToolName_SIGNAL" SG_ 2147484182 DrivingLight_Indication "DrivingLight_Indication";
BA_ "SeToolVersion_SIGNAL" SG_ 2147484182 DrivingLight_Indication "3";
BA_ "GenSigCycleTime" SG_ 2147484182 MirrorHeatingMode_ISig_4 100;
BA_ "GenSigCycleTimeActive" SG_ 2147484182 MirrorHeatingMode_ISig_4 100;
BA_ "GenSigStartValue" SG_ 2147484182 MirrorHeatingMode_ISig_4 7;
BA_ "GenSigMaxLatency" SG_ 2147484182 MirrorHeatingMode_ISig_4 29;
BA_ "Platform_VMCU1_Sig" SG_ 2147484182 MirrorHeatingMode_ISig_4 1;
BA_ "SeToolAncestorID_SIGNAL" SG_ 2147484182 MirrorHeatingMode_ISig_4 "x0000001D0412C1DB";
BA_ "SeToolItemID_SIGNAL" SG_ 2147484182 MirrorHeatingMode_ISig_4 "x0000001D0412C1DB";
BA_ "SeToolName_SIGNAL" SG_ 2147484182 MirrorHeatingMode_ISig_4 "MirrorHeatingMode";
BA_ "SeToolVersion_SIGNAL" SG_ 2147484182 MirrorHeatingMode_ISig_4 "1";
BA_ "GenSigCycleTime" SG_ 2147484182 RearFog_Indication 100;
BA_ "GenSigCycleTimeActive" SG_ 2147484182 RearFog_Indication 100;
BA_ "GenSigStartValue" SG_ 2147484182 RearFog_Indication 3;
BA_ "GenSigMaxLatency" SG_ 2147484182 RearFog_Indication 29;
BA_ "Platform_VMCU1_Sig" SG_ 2147484182 RearFog_Indication 1;
BA_ "SeToolAncestorID_SIGNAL" SG_ 2147484182 RearFog_Indication "x0000001D041A7C03";
BA_ "SeToolItemID_SIGNAL" SG_ 2147484182 RearFog_Indication "x0000001D043C4080";
BA_ "SeToolName_SIGNAL" SG_ 2147484182 RearFog_Indication "RearFog_Indication";
BA_ "SeToolVersion_SIGNAL" SG_ 2147484182 RearFog_Indication "3";
BA_ "GenSigCycleTime" SG_ 2147484182 InteriorLightLevelInd_cmd 100;
BA_ "GenSigCycleTimeActive" SG_ 2147484182 InteriorLightLevelInd_cmd 100;
BA_ "GenSigStartValue" SG_ 2147484182 InteriorLightLevelInd_cmd 255;
BA_ "Platform_VMCU1_Sig" SG_ 2147484182 InteriorLightLevelInd_cmd 1;
BA_ "GenSigSendType" SG_ 2147484180 LevelControlInformation_UB_ISig_ 7;
BA_ "Platform_VMCU1_Sig" SG_ 2147484180 LevelControlInformation_UB_ISig_ 1;
BA_ "SystemSignalLongSymbol" SG_ 2147484180 LevelControlInformation_UB_ISig_ "LevelControlInformation_UB_ISig_4";
BA_ "GenSigCycleTime" SG_ 2147484180 LiftAxle2LiftFuncSelected_ISig_4 100;
BA_ "GenSigCycleTimeActive" SG_ 2147484180 LiftAxle2LiftFuncSelected_ISig_4 100;
BA_ "GenSigStartValue" SG_ 2147484180 LiftAxle2LiftFuncSelected_ISig_4 7;
BA_ "SeToolAncestorID_SIGNAL" SG_ 2147484180 LiftAxle2LiftFuncSelected_ISig_4 "x0000001D04134C4B";
BA_ "SeToolItemID_SIGNAL" SG_ 2147484180 LiftAxle2LiftFuncSelected_ISig_4 "x0000001D04134C4B";
BA_ "SeToolName_SIGNAL" SG_ 2147484180 LiftAxle2LiftFuncSelected_ISig_4 "LiftAxle2LiftAutoFunctionSelected";
BA_ "SeToolVersion_SIGNAL" SG_ 2147484180 LiftAxle2LiftFuncSelected_ISig_4 "1";
BA_ "GenSigCycleTime" SG_ 2147484180 StopLevelChangeAck_ISig_4 100;
BA_ "GenSigCycleTimeActive" SG_ 2147484180 StopLevelChangeAck_ISig_4 100;
BA_ "GenSigStartValue" SG_ 2147484180 StopLevelChangeAck_ISig_4 3;
BA_ "GenSigMaxLatency" SG_ 2147484180 StopLevelChangeAck_ISig_4 28;
BA_ "Platform_VMCU1_Sig" SG_ 2147484180 StopLevelChangeAck_ISig_4 1;
BA_ "SeToolAncestorID_SIGNAL" SG_ 2147484180 StopLevelChangeAck_ISig_4 "x0000001D0412ECBE";
BA_ "SeToolItemID_SIGNAL" SG_ 2147484180 StopLevelChangeAck_ISig_4 "x0000001D0412ECBE";
BA_ "SeToolName_SIGNAL" SG_ 2147484180 StopLevelChangeAck_ISig_4 "StopLevelChangeAck";
BA_ "SeToolVersion_SIGNAL" SG_ 2147484180 StopLevelChangeAck_ISig_4 "1";
BA_ "GenSigCycleTime" SG_ 2147484180 HeightAdjustmentAllowed_ISig_4 100;
BA_ "GenSigCycleTimeActive" SG_ 2147484180 HeightAdjustmentAllowed_ISig_4 100;
BA_ "GenSigStartValue" SG_ 2147484180 HeightAdjustmentAllowed_ISig_4 3;
BA_ "Platform_VMCU1_Sig" SG_ 2147484180 HeightAdjustmentAllowed_ISig_4 1;
BA_ "GenSigCycleTime" SG_ 2147484180 LiftAxle2LowerACK_ISig_4 100;
BA_ "GenSigCycleTimeActive" SG_ 2147484180 LiftAxle2LowerACK_ISig_4 100;
BA_ "GenSigStartValue" SG_ 2147484180 LiftAxle2LowerACK_ISig_4 7;
BA_ "GenSigCycleTime" SG_ 2147484180 LiftAxle2UpRequestACK_ISig_4 100;
BA_ "GenSigCycleTimeActive" SG_ 2147484180 LiftAxle2UpRequestACK_ISig_4 100;
BA_ "GenSigStartValue" SG_ 2147484180 LiftAxle2UpRequestACK_ISig_4 7;
BA_ "GenSigMaxLatency" SG_ 2147484180 LiftAxle2UpRequestACK_ISig_4 28;
BA_ "Platform_VMCU1_Sig" SG_ 2147484180 LiftAxle2UpRequestACK_ISig_4 1;
BA_ "SeToolAncestorID_SIGNAL" SG_ 2147484180 LiftAxle2UpRequestACK_ISig_4 "x0000001D043E0E16";
BA_ "SeToolItemID_SIGNAL" SG_ 2147484180 LiftAxle2UpRequestACK_ISig_4 "x0000001D043E0E16";
BA_ "SeToolName_SIGNAL" SG_ 2147484180 LiftAxle2UpRequestACK_ISig_4 "LiftAxle2UpRequestACK";
BA_ "SeToolVersion_SIGNAL" SG_ 2147484180 LiftAxle2UpRequestACK_ISig_4 "1";
BA_ "GenSigCycleTime" SG_ 2147484180 RideHeightStatus_ISig_4 100;
BA_ "GenSigCycleTimeActive" SG_ 2147484180 RideHeightStatus_ISig_4 100;
BA_ "GenSigStartValue" SG_ 2147484180 RideHeightStatus_ISig_4 15;
BA_ "GenSigMaxLatency" SG_ 2147484180 RideHeightStatus_ISig_4 28;
BA_ "Platform_VMCU1_Sig" SG_ 2147484180 RideHeightStatus_ISig_4 1;
BA_ "SeToolAncestorID_SIGNAL" SG_ 2147484180 RideHeightStatus_ISig_4 "x0000001D041304DF";
BA_ "SeToolItemID_SIGNAL" SG_ 2147484180 RideHeightStatus_ISig_4 "x0000001D0442415B";
BA_ "SeToolName_SIGNAL" SG_ 2147484180 RideHeightStatus_ISig_4 "RideHeightStatus";
BA_ "SeToolVersion_SIGNAL" SG_ 2147484180 RideHeightStatus_ISig_4 "3";
BA_ "GenSigCycleTime" SG_ 2147484180 RideHeightOutsideTargetRange_ISi 100;
BA_ "GenSigCycleTimeActive" SG_ 2147484180 RideHeightOutsideTargetRange_ISi 100;
BA_ "GenSigStartValue" SG_ 2147484180 RideHeightOutsideTargetRange_ISi 7;
BA_ "GenSigMaxLatency" SG_ 2147484180 RideHeightOutsideTargetRange_ISi 28;
BA_ "Platform_VMCU1_Sig" SG_ 2147484180 RideHeightOutsideTargetRange_ISi 1;
BA_ "SeToolAncestorID_SIGNAL" SG_ 2147484180 RideHeightOutsideTargetRange_ISi "x0000001D041F15D9";
BA_ "SeToolItemID_SIGNAL" SG_ 2147484180 RideHeightOutsideTargetRange_ISi "x0000001D041F15D9";
BA_ "SeToolName_SIGNAL" SG_ 2147484180 RideHeightOutsideTargetRange_ISi "RideHeightOutsideTargetRange";
BA_ "SeToolVersion_SIGNAL" SG_ 2147484180 RideHeightOutsideTargetRange_ISi "1";
BA_ "SystemSignalLongSymbol" SG_ 2147484180 RideHeightOutsideTargetRange_ISi "RideHeightOutsideTargetRange_ISig_4";
BA_ "GenSigCycleTime" SG_ 2147484180 LoadDistributionFuncSelected_ISi 100;
BA_ "GenSigCycleTimeActive" SG_ 2147484180 LoadDistributionFuncSelected_ISi 100;
BA_ "GenSigStartValue" SG_ 2147484180 LoadDistributionFuncSelected_ISi 15;
BA_ "GenSigMaxLatency" SG_ 2147484180 LoadDistributionFuncSelected_ISi 28;
BA_ "Platform_VMCU1_Sig" SG_ 2147484180 LoadDistributionFuncSelected_ISi 1;
BA_ "SeToolAncestorID_SIGNAL" SG_ 2147484180 LoadDistributionFuncSelected_ISi "x0000001D04355313";
BA_ "SeToolItemID_SIGNAL" SG_ 2147484180 LoadDistributionFuncSelected_ISi "x0000001D043AB18A";
BA_ "SeToolName_SIGNAL" SG_ 2147484180 LoadDistributionFuncSelected_ISi "LoadDistributionRequested";
BA_ "SeToolVersion_SIGNAL" SG_ 2147484180 LoadDistributionFuncSelected_ISi "2";
BA_ "SystemSignalLongSymbol" SG_ 2147484180 LoadDistributionFuncSelected_ISi "LoadDistributionFuncSelected_ISig_4";
BA_ "GenSigCycleTime" SG_ 2147484180 RideHeightStorageAck_ISig_4 100;
BA_ "GenSigCycleTimeActive" SG_ 2147484180 RideHeightStorageAck_ISig_4 100;
BA_ "GenSigStartValue" SG_ 2147484180 RideHeightStorageAck_ISig_4 3;
BA_ "GenSigMaxLatency" SG_ 2147484180 RideHeightStorageAck_ISig_4 28;
BA_ "Platform_VMCU1_Sig" SG_ 2147484180 RideHeightStorageAck_ISig_4 1;
BA_ "SeToolAncestorID_SIGNAL" SG_ 2147484180 RideHeightStorageAck_ISig_4 "x0000001D0421D044";
BA_ "SeToolItemID_SIGNAL" SG_ 2147484180 RideHeightStorageAck_ISig_4 "x0000001D0421D044";
BA_ "SeToolName_SIGNAL" SG_ 2147484180 RideHeightStorageAck_ISig_4 "RideHeightStorageAck";
BA_ "SeToolVersion_SIGNAL" SG_ 2147484180 RideHeightStorageAck_ISig_4 "1";
BA_ "GenSigCycleTime" SG_ 2147484180 LiftAxle2AutoLiftSelected_ISig_4 100;
BA_ "GenSigCycleTimeActive" SG_ 2147484180 LiftAxle2AutoLiftSelected_ISig_4 100;
BA_ "GenSigStartValue" SG_ 2147484180 LiftAxle2AutoLiftSelected_ISig_4 3;
BA_ "GenSigCycleTime" SG_ 2147484180 LiftAxle1UpRequestACK_ISig_4 100;
BA_ "GenSigCycleTimeActive" SG_ 2147484180 LiftAxle1UpRequestACK_ISig_4 100;
BA_ "GenSigStartValue" SG_ 2147484180 LiftAxle1UpRequestACK_ISig_4 7;
BA_ "GenSigMaxLatency" SG_ 2147484180 LiftAxle1UpRequestACK_ISig_4 28;
BA_ "Platform_VMCU1_Sig" SG_ 2147484180 LiftAxle1UpRequestACK_ISig_4 1;
BA_ "SeToolAncestorID_SIGNAL" SG_ 2147484180 LiftAxle1UpRequestACK_ISig_4 "x0000001D043E0DFD";
BA_ "SeToolItemID_SIGNAL" SG_ 2147484180 LiftAxle1UpRequestACK_ISig_4 "x0000001D043E0DFD";
BA_ "SeToolName_SIGNAL" SG_ 2147484180 LiftAxle1UpRequestACK_ISig_4 "LiftAxle1UpRequestACK";
BA_ "SeToolVersion_SIGNAL" SG_ 2147484180 LiftAxle1UpRequestACK_ISig_4 "1";
BA_ "GenSigCycleTime" SG_ 2147484180 LiftAxle1PositionStatus_ISig_4 100;
BA_ "GenSigCycleTimeActive" SG_ 2147484180 LiftAxle1PositionStatus_ISig_4 100;
BA_ "GenSigStartValue" SG_ 2147484180 LiftAxle1PositionStatus_ISig_4 7;
BA_ "GenSigMaxLatency" SG_ 2147484180 LiftAxle1PositionStatus_ISig_4 28;
BA_ "Platform_VMCU1_Sig" SG_ 2147484180 LiftAxle1PositionStatus_ISig_4 1;
BA_ "SeToolAncestorID_SIGNAL" SG_ 2147484180 LiftAxle1PositionStatus_ISig_4 "x0000001D04131A08";
BA_ "SeToolItemID_SIGNAL" SG_ 2147484180 LiftAxle1PositionStatus_ISig_4 "x0000001D0423C412";
BA_ "SeToolName_SIGNAL" SG_ 2147484180 LiftAxle1PositionStatus_ISig_4 "LiftAxle1PositionStatus";
BA_ "SeToolVersion_SIGNAL" SG_ 2147484180 LiftAxle1PositionStatus_ISig_4 "2";
BA_ "GenSigCycleTime" SG_ 2147484180 LiftAxle1LowerACK_ISig_4 100;
BA_ "GenSigCycleTimeActive" SG_ 2147484180 LiftAxle1LowerACK_ISig_4 100;
BA_ "GenSigStartValue" SG_ 2147484180 LiftAxle1LowerACK_ISig_4 7;
BA_ "GenSigCycleTime" SG_ 2147484180 LiftAxle1AutoLiftSelected_ISig_4 100;
BA_ "GenSigCycleTimeActive" SG_ 2147484180 LiftAxle1AutoLiftSelected_ISig_4 100;
BA_ "GenSigStartValue" SG_ 2147484180 LiftAxle1AutoLiftSelected_ISig_4 3;
BA_ "GenSigCycleTime" SG_ 2147484180 LiftAxle2PositionStatus_ISig_4 100;
BA_ "GenSigCycleTimeActive" SG_ 2147484180 LiftAxle2PositionStatus_ISig_4 100;
BA_ "GenSigStartValue" SG_ 2147484180 LiftAxle2PositionStatus_ISig_4 7;
BA_ "GenSigMaxLatency" SG_ 2147484180 LiftAxle2PositionStatus_ISig_4 28;
BA_ "Platform_VMCU1_Sig" SG_ 2147484180 LiftAxle2PositionStatus_ISig_4 1;
BA_ "SeToolAncestorID_SIGNAL" SG_ 2147484180 LiftAxle2PositionStatus_ISig_4 "x0000001D04131A0A";
BA_ "SeToolItemID_SIGNAL" SG_ 2147484180 LiftAxle2PositionStatus_ISig_4 "x0000001D04295880";
BA_ "SeToolName_SIGNAL" SG_ 2147484180 LiftAxle2PositionStatus_ISig_4 "LiftAxle2PositionStatus";
BA_ "SeToolVersion_SIGNAL" SG_ 2147484180 LiftAxle2PositionStatus_ISig_4 "3";
BA_ "GenSigCycleTime" SG_ 2147484180 LevelControlInformation_ISig_4 100;
BA_ "GenSigCycleTimeActive" SG_ 2147484180 LevelControlInformation_ISig_4 100;
BA_ "GenSigStartValue" SG_ 2147484180 LevelControlInformation_ISig_4 15;
BA_ "GenSigMaxLatency" SG_ 2147484180 LevelControlInformation_ISig_4 28;
BA_ "NeedsUpdateBit" SG_ 2147484180 LevelControlInformation_ISig_4 1;
BA_ "Platform_VMCU1_Sig" SG_ 2147484180 LevelControlInformation_ISig_4 1;
BA_ "SeToolAncestorID_SIGNAL" SG_ 2147484180 LevelControlInformation_ISig_4 "x0000001D04290369";
BA_ "SeToolItemID_SIGNAL" SG_ 2147484180 LevelControlInformation_ISig_4 "x0000001D04290369";
BA_ "SeToolName_SIGNAL" SG_ 2147484180 LevelControlInformation_ISig_4 "LevelControlInformation";
BA_ "SeToolVersion_SIGNAL" SG_ 2147484180 LevelControlInformation_ISig_4 "1";
BA_ "GenSigCycleTime" SG_ 2147484180 LiftAxle1LiftFuncSelected_ISig_4 100;
BA_ "GenSigCycleTimeActive" SG_ 2147484180 LiftAxle1LiftFuncSelected_ISig_4 100;
BA_ "GenSigStartValue" SG_ 2147484180 LiftAxle1LiftFuncSelected_ISig_4 7;
BA_ "SeToolAncestorID_SIGNAL" SG_ 2147484180 LiftAxle1LiftFuncSelected_ISig_4 "x0000001D04134C43";
BA_ "SeToolItemID_SIGNAL" SG_ 2147484180 LiftAxle1LiftFuncSelected_ISig_4 "x0000001D04134C43";
BA_ "SeToolName_SIGNAL" SG_ 2147484180 LiftAxle1LiftFuncSelected_ISig_4 "LiftAxle1LiftAutoFunctionSelected";
BA_ "SeToolVersion_SIGNAL" SG_ 2147484180 LiftAxle1LiftFuncSelected_ISig_4 "1";
BA_ "GenSigCycleTime" SG_ 2147484180 LoadDistributionChangeACK_ISig_4 100;
BA_ "GenSigCycleTimeActive" SG_ 2147484180 LoadDistributionChangeACK_ISig_4 100;
BA_ "GenSigStartValue" SG_ 2147484180 LoadDistributionChangeACK_ISig_4 7;
BA_ "GenSigMaxLatency" SG_ 2147484180 LoadDistributionChangeACK_ISig_4 28;
BA_ "Platform_VMCU1_Sig" SG_ 2147484180 LoadDistributionChangeACK_ISig_4 1;
BA_ "SeToolAncestorID_SIGNAL" SG_ 2147484180 LoadDistributionChangeACK_ISig_4 "x0000001D04176D2D";
BA_ "SeToolItemID_SIGNAL" SG_ 2147484180 LoadDistributionChangeACK_ISig_4 "x0000001D0440C942";
BA_ "SeToolName_SIGNAL" SG_ 2147484180 LoadDistributionChangeACK_ISig_4 "LoadDistributionChangeAck";
BA_ "SeToolVersion_SIGNAL" SG_ 2147484180 LoadDistributionChangeACK_ISig_4 "2";
BA_ "GenSigCycleTime" SG_ 2147484180 RampLevelStorageAck_ISig_4 100;
BA_ "GenSigCycleTimeActive" SG_ 2147484180 RampLevelStorageAck_ISig_4 100;
BA_ "GenSigStartValue" SG_ 2147484180 RampLevelStorageAck_ISig_4 3;
BA_ "GenSigMaxLatency" SG_ 2147484180 RampLevelStorageAck_ISig_4 28;
BA_ "Platform_VMCU1_Sig" SG_ 2147484180 RampLevelStorageAck_ISig_4 1;
BA_ "SeToolAncestorID_SIGNAL" SG_ 2147484180 RampLevelStorageAck_ISig_4 "x0000001D0421FE10";
BA_ "SeToolItemID_SIGNAL" SG_ 2147484180 RampLevelStorageAck_ISig_4 "x0000001D0421FE10";
BA_ "SeToolName_SIGNAL" SG_ 2147484180 RampLevelStorageAck_ISig_4 "RampLevelStorageAck";
BA_ "SeToolVersion_SIGNAL" SG_ 2147484180 RampLevelStorageAck_ISig_4 "1";
BA_ "GenSigCycleTime" SG_ 2147484180 LoadDistributionSelected_ISig_4 100;
BA_ "GenSigCycleTimeActive" SG_ 2147484180 LoadDistributionSelected_ISig_4 100;
BA_ "GenSigStartValue" SG_ 2147484180 LoadDistributionSelected_ISig_4 15;
BA_ "GenSigMaxLatency" SG_ 2147484180 LoadDistributionSelected_ISig_4 112;
BA_ "Platform_VMCU1_Sig" SG_ 2147484180 LoadDistributionSelected_ISig_4 1;
BA_ "GenSigCycleTime" SG_ 2147484180 RideHeightFunctionStatus_ISig_4 100;
BA_ "GenSigCycleTimeActive" SG_ 2147484180 RideHeightFunctionStatus_ISig_4 100;
BA_ "GenSigStartValue" SG_ 2147484180 RideHeightFunctionStatus_ISig_4 15;
BA_ "GenSigMaxLatency" SG_ 2147484180 RideHeightFunctionStatus_ISig_4 28;
BA_ "Platform_VMCU1_Sig" SG_ 2147484180 RideHeightFunctionStatus_ISig_4 1;
BA_ "SeToolAncestorID_SIGNAL" SG_ 2147484180 RideHeightFunctionStatus_ISig_4 "x0000001D042186C7";
BA_ "SeToolItemID_SIGNAL" SG_ 2147484180 RideHeightFunctionStatus_ISig_4 "x0000001D043FB877";
BA_ "SeToolName_SIGNAL" SG_ 2147484180 RideHeightFunctionStatus_ISig_4 "RideHeightFunctionStatus";
BA_ "SeToolVersion_SIGNAL" SG_ 2147484180 RideHeightFunctionStatus_ISig_4 "2";
BA_ "GenSigSendType" SG_ 2147484168 GearSplit_Status_UB_ISig_4 7;
BA_ "Platform_VMCU1_Sig" SG_ 2147484168 GearSplit_Status_UB_ISig_4 1;
BA_ "GenSigCycleTime" SG_ 2147484168 TransmLowRangeSenseSwitch_ISig_4 100;
BA_ "GenSigCycleTimeActive" SG_ 2147484168 TransmLowRangeSenseSwitch_ISig_4 100;
BA_ "GenSigStartValue" SG_ 2147484168 TransmLowRangeSenseSwitch_ISig_4 3;
BA_ "Platform_VMCU1_Sig" SG_ 2147484168 TransmLowRangeSenseSwitch_ISig_4 1;
BA_ "GenSigCycleTime" SG_ 2147484168 TransmSystemPowerDown_rqst 100;
BA_ "GenSigCycleTimeActive" SG_ 2147484168 TransmSystemPowerDown_rqst 100;
BA_ "GenSigStartValue" SG_ 2147484168 TransmSystemPowerDown_rqst 3;
BA_ "GenSigMaxLatency" SG_ 2147484168 TransmSystemPowerDown_rqst 26;
BA_ "NeedsUpdateBit" SG_ 2147484168 TransmSystemPowerDown_rqst 1;
BA_ "Platform_VMCU1_Sig" SG_ 2147484168 TransmSystemPowerDown_rqst 1;
BA_ "SeToolAncestorID_SIGNAL" SG_ 2147484168 TransmSystemPowerDown_rqst "x0000001D0437CB03";
BA_ "SeToolItemID_SIGNAL" SG_ 2147484168 TransmSystemPowerDown_rqst "x0000001D0437CB03";
BA_ "SeToolName_SIGNAL" SG_ 2147484168 TransmSystemPowerDown_rqst "TransmissionSystemPowerDownRequest";
BA_ "SeToolVersion_SIGNAL" SG_ 2147484168 TransmSystemPowerDown_rqst "1";
BA_ "GenSigCycleTime" SG_ 2147484168 TransmissionNeutralSwitch_ISig_4 100;
BA_ "GenSigCycleTimeActive" SG_ 2147484168 TransmissionNeutralSwitch_ISig_4 100;
BA_ "GenSigStartValue" SG_ 2147484168 TransmissionNeutralSwitch_ISig_4 3;
BA_ "GenSigMaxLatency" SG_ 2147484168 TransmissionNeutralSwitch_ISig_4 26;
BA_ "NeedsUpdateBit" SG_ 2147484168 TransmissionNeutralSwitch_ISig_4 1;
BA_ "Platform_VMCU1_Sig" SG_ 2147484168 TransmissionNeutralSwitch_ISig_4 1;
BA_ "SeToolAncestorID_SIGNAL" SG_ 2147484168 TransmissionNeutralSwitch_ISig_4 "x0000001D0412E2B6";
BA_ "SeToolItemID_SIGNAL" SG_ 2147484168 TransmissionNeutralSwitch_ISig_4 "x0000001D042FD0C5";
BA_ "SeToolName_SIGNAL" SG_ 2147484168 TransmissionNeutralSwitch_ISig_4 "TransmissionNeutralSwitch";
BA_ "SeToolVersion_SIGNAL" SG_ 2147484168 TransmissionNeutralSwitch_ISig_4 "2";
BA_ "GenSigCycleTime" SG_ 2147484168 SecuredNeutralPosition_ISig_4 100;
BA_ "GenSigCycleTimeActive" SG_ 2147484168 SecuredNeutralPosition_ISig_4 100;
BA_ "GenSigStartValue" SG_ 2147484168 SecuredNeutralPosition_ISig_4 3;
BA_ "NeedsUpdateBit" SG_ 2147484168 SecuredNeutralPosition_ISig_4 1;
BA_ "Platform_VMCU1_Sig" SG_ 2147484168 SecuredNeutralPosition_ISig_4 1;
BA_ "SeToolAncestorID_SIGNAL" SG_ 2147484168 SecuredNeutralPosition_ISig_4 "x0000001D04127A25";
BA_ "SeToolItemID_SIGNAL" SG_ 2147484168 SecuredNeutralPosition_ISig_4 "x0000001D043C813E";
BA_ "SeToolName_SIGNAL" SG_ 2147484168 SecuredNeutralPosition_ISig_4 "SecuredNeutralPosition";
BA_ "SeToolVersion_SIGNAL" SG_ 2147484168 SecuredNeutralPosition_ISig_4 "2";
BA_ "GenSigCycleTime" SG_ 2147484168 EngineStopRequest_ISig_4 100;
BA_ "GenSigCycleTimeActive" SG_ 2147484168 EngineStopRequest_ISig_4 100;
BA_ "GenSigStartValue" SG_ 2147484168 EngineStopRequest_ISig_4 3;
BA_ "GenSigMaxLatency" SG_ 2147484168 EngineStopRequest_ISig_4 26;
BA_ "Platform_VMCU1_Sig" SG_ 2147484168 EngineStopRequest_ISig_4 1;
BA_ "SeToolAncestorID_SIGNAL" SG_ 2147484168 EngineStopRequest_ISig_4 "x0000001D042883AC";
BA_ "SeToolItemID_SIGNAL" SG_ 2147484168 EngineStopRequest_ISig_4 "x0000001D042883AC";
BA_ "SeToolName_SIGNAL" SG_ 2147484168 EngineStopRequest_ISig_4 "EngineStopRequest";
BA_ "SeToolVersion_SIGNAL" SG_ 2147484168 EngineStopRequest_ISig_4 "1";
BA_ "GenSigSendType" SG_ 2147484168 TransmissionNeutralSwitch_UB_ISi 7;
BA_ "Platform_VMCU1_Sig" SG_ 2147484168 TransmissionNeutralSwitch_UB_ISi 1;
BA_ "SystemSignalLongSymbol" SG_ 2147484168 TransmissionNeutralSwitch_UB_ISi "TransmissionNeutralSwitch_UB_ISig_4";
BA_ "GenSigCycleTime" SG_ 2147484168 ReverseGearEngaged_ISig_4 100;
BA_ "GenSigCycleTimeActive" SG_ 2147484168 ReverseGearEngaged_ISig_4 100;
BA_ "GenSigStartValue" SG_ 2147484168 ReverseGearEngaged_ISig_4 3;
BA_ "GenSigMaxLatency" SG_ 2147484168 ReverseGearEngaged_ISig_4 26;
BA_ "NeedsUpdateBit" SG_ 2147484168 ReverseGearEngaged_ISig_4 1;
BA_ "Platform_VMCU1_Sig" SG_ 2147484168 ReverseGearEngaged_ISig_4 1;
BA_ "SeToolAncestorID_SIGNAL" SG_ 2147484168 ReverseGearEngaged_ISig_4 "x0000001D0413A2F1";
BA_ "SeToolItemID_SIGNAL" SG_ 2147484168 ReverseGearEngaged_ISig_4 "x0000001D0413A2F1";
BA_ "SeToolName_SIGNAL" SG_ 2147484168 ReverseGearEngaged_ISig_4 "ReverseGearEngaged";
BA_ "SeToolVersion_SIGNAL" SG_ 2147484168 ReverseGearEngaged_ISig_4 "1";
BA_ "GenSigSendType" SG_ 2147484168 TransmSystemPowerDown_rqst_UB 7;
BA_ "Platform_VMCU1_Sig" SG_ 2147484168 TransmSystemPowerDown_rqst_UB 1;
BA_ "GenSigCycleTime" SG_ 2147484168 EngineCrankRequest 100;
BA_ "GenSigCycleTimeActive" SG_ 2147484168 EngineCrankRequest 100;
BA_ "GenSigStartValue" SG_ 2147484168 EngineCrankRequest 3;
BA_ "GenSigMaxLatency" SG_ 2147484168 EngineCrankRequest 26;
BA_ "Platform_VMCU1_Sig" SG_ 2147484168 EngineCrankRequest 1;
BA_ "SeToolAncestorID_SIGNAL" SG_ 2147484168 EngineCrankRequest "x0000001D0418E20E";
BA_ "SeToolItemID_SIGNAL" SG_ 2147484168 EngineCrankRequest "x0000001D0421DFDE";
BA_ "SeToolName_SIGNAL" SG_ 2147484168 EngineCrankRequest "EngineCrankRequest";
BA_ "SeToolVersion_SIGNAL" SG_ 2147484168 EngineCrankRequest "2";
BA_ "GenSigSendType" SG_ 2147484168 ParkBrakeActuationStatus_UB 7;
BA_ "Platform_VMCU1_Sig" SG_ 2147484168 ParkBrakeActuationStatus_UB 1;
BA_ "GenSigCycleTime" SG_ 2147484168 ParkBrakeActuationStatus 100;
BA_ "GenSigCycleTimeActive" SG_ 2147484168 ParkBrakeActuationStatus 100;
BA_ "GenSigStartValue" SG_ 2147484168 ParkBrakeActuationStatus 7;
BA_ "NeedsUpdateBit" SG_ 2147484168 ParkBrakeActuationStatus 1;
BA_ "Platform_VMCU1_Sig" SG_ 2147484168 ParkBrakeActuationStatus 1;
BA_ "SeToolAncestorID_SIGNAL" SG_ 2147484168 ParkBrakeActuationStatus "x0000001D041497B7";
BA_ "SeToolItemID_SIGNAL" SG_ 2147484168 ParkBrakeActuationStatus "x0000001D0433084A";
BA_ "SeToolName_SIGNAL" SG_ 2147484168 ParkBrakeActuationStatus "ParkBrakeActuationStatus";
BA_ "SeToolVersion_SIGNAL" SG_ 2147484168 ParkBrakeActuationStatus "2";
BA_ "GenSigCycleTime" SG_ 2147484168 EnginePreheat_rqst 100;
BA_ "GenSigCycleTimeActive" SG_ 2147484168 EnginePreheat_rqst 100;
BA_ "GenSigStartValue" SG_ 2147484168 EnginePreheat_rqst 3;
BA_ "GenSigMaxLatency" SG_ 2147484168 EnginePreheat_rqst 26;
BA_ "Platform_VMCU1_Sig" SG_ 2147484168 EnginePreheat_rqst 1;
BA_ "SeToolAncestorID_SIGNAL" SG_ 2147484168 EnginePreheat_rqst "x0000001D0419A3FC";
BA_ "SeToolItemID_SIGNAL" SG_ 2147484168 EnginePreheat_rqst "x0000001D04218951";
BA_ "SeToolName_SIGNAL" SG_ 2147484168 EnginePreheat_rqst "EnginePreheat_rqst";
BA_ "SeToolVersion_SIGNAL" SG_ 2147484168 EnginePreheat_rqst "2";
BA_ "GenSigSendType" SG_ 2147484168 ReverseGearEngaged_UB_ISig_4 7;
BA_ "Platform_VMCU1_Sig" SG_ 2147484168 ReverseGearEngaged_UB_ISig_4 1;
BA_ "GenSigCycleTime" SG_ 2147484168 AcceleratorPedalPositionBackup 100;
BA_ "GenSigCycleTimeActive" SG_ 2147484168 AcceleratorPedalPositionBackup 100;
BA_ "GenSigStartValue" SG_ 2147484168 AcceleratorPedalPositionBackup 255;
BA_ "Platform_VMCU1_Sig" SG_ 2147484168 AcceleratorPedalPositionBackup 1;
BA_ "GenSigCycleTime" SG_ 2147484168 KeyPosition_ISig_4 100;
BA_ "GenSigCycleTimeActive" SG_ 2147484168 KeyPosition_ISig_4 100;
BA_ "GenSigStartValue" SG_ 2147484168 KeyPosition_ISig_4 7;
BA_ "GenSigMaxLatency" SG_ 2147484168 KeyPosition_ISig_4 26;
BA_ "Platform_VMCU1_Sig" SG_ 2147484168 KeyPosition_ISig_4 1;
BA_ "SeToolAncestorID_SIGNAL" SG_ 2147484168 KeyPosition_ISig_4 "x0000001D0410D5F7";
BA_ "SeToolItemID_SIGNAL" SG_ 2147484168 KeyPosition_ISig_4 "x0000001D0410D5F7";
BA_ "SeToolName_SIGNAL" SG_ 2147484168 KeyPosition_ISig_4 "KeyPosition";
BA_ "SeToolVersion_SIGNAL" SG_ 2147484168 KeyPosition_ISig_4 "1";
BA_ "GenSigCycleTime" SG_ 2147484168 GearSplit_Status_ISig_4 100;
BA_ "GenSigCycleTimeActive" SG_ 2147484168 GearSplit_Status_ISig_4 100;
BA_ "GenSigStartValue" SG_ 2147484168 GearSplit_Status_ISig_4 3;
BA_ "NeedsUpdateBit" SG_ 2147484168 GearSplit_Status_ISig_4 1;
BA_ "Platform_VMCU1_Sig" SG_ 2147484168 GearSplit_Status_ISig_4 1;
BA_ "GenSigCycleTime" SG_ 2147484168 FerryFunctionSwitchChangeACK_ISi 100;
BA_ "GenSigCycleTimeActive" SG_ 2147484168 FerryFunctionSwitchChangeACK_ISi 100;
BA_ "GenSigStartValue" SG_ 2147484168 FerryFunctionSwitchChangeACK_ISi 3;
BA_ "Platform_VMCU1_Sig" SG_ 2147484168 FerryFunctionSwitchChangeACK_ISi 1;
BA_ "SystemSignalLongSymbol" SG_ 2147484168 FerryFunctionSwitchChangeACK_ISi "FerryFunctionSwitchChangeACK_ISig_4";
BA_ "GenSigSendType" SG_ 2147484168 SecuredNeutralPosition_UB_ISig_4 7;
BA_ "Platform_VMCU1_Sig" SG_ 2147484168 SecuredNeutralPosition_UB_ISig_4 1;
BA_ "GenSigCycleTime" SG_ 2147484168 DirectionIndication_cmd 100;
BA_ "GenSigCycleTimeActive" SG_ 2147484168 DirectionIndication_cmd 100;
BA_ "GenSigStartValue" SG_ 2147484168 DirectionIndication_cmd 15;
BA_ "GenSigMaxLatency" SG_ 2147484168 DirectionIndication_cmd 26;
BA_ "Platform_VMCU1_Sig" SG_ 2147484168 DirectionIndication_cmd 1;
BA_ "SeToolAncestorID_SIGNAL" SG_ 2147484168 DirectionIndication_cmd "x0000001D042C9D17";
BA_ "SeToolItemID_SIGNAL" SG_ 2147484168 DirectionIndication_cmd "x0000001D0433EF63";
BA_ "SeToolName_SIGNAL" SG_ 2147484168 DirectionIndication_cmd "DirectionIndication_cmd";
BA_ "SeToolVersion_SIGNAL" SG_ 2147484168 DirectionIndication_cmd "2";
BA_ "GenSigCycleTime" SG_ 2147484168 IdleShutdownWarning 100;
BA_ "GenSigCycleTimeActive" SG_ 2147484168 IdleShutdownWarning 100;
BA_ "GenSigStartValue" SG_ 2147484168 IdleShutdownWarning 3;
BA_ "GenSigMaxLatency" SG_ 2147484168 IdleShutdownWarning 26;
BA_ "Platform_VMCU1_Sig" SG_ 2147484168 IdleShutdownWarning 1;
BA_ "SeToolAncestorID_SIGNAL" SG_ 2147484168 IdleShutdownWarning "x0000001D0417E7DE";
BA_ "SeToolItemID_SIGNAL" SG_ 2147484168 IdleShutdownWarning "x0000001D0417E7DE";
BA_ "SeToolName_SIGNAL" SG_ 2147484168 IdleShutdownWarning "IdleShutdownWarning";
BA_ "SeToolVersion_SIGNAL" SG_ 2147484168 IdleShutdownWarning "1";
BA_ "GenSigCycleTime" SG_ 2147484168 BackToDriveReqACK_ISig_4 100;
BA_ "GenSigCycleTimeActive" SG_ 2147484168 BackToDriveReqACK_ISig_4 100;
BA_ "GenSigStartValue" SG_ 2147484168 BackToDriveReqACK_ISig_4 3;
BA_ "Platform_VMCU1_Sig" SG_ 2147484168 BackToDriveReqACK_ISig_4 1;
BA_ "GenSigCycleTime" SG_ 2147484168 EngineSystemPowerDownRequest_ISi 100;
BA_ "GenSigCycleTimeActive" SG_ 2147484168 EngineSystemPowerDownRequest_ISi 100;
BA_ "GenSigStartValue" SG_ 2147484168 EngineSystemPowerDownRequest_ISi 3;
BA_ "GenSigMaxLatency" SG_ 2147484168 EngineSystemPowerDownRequest_ISi 26;
BA_ "Platform_VMCU1_Sig" SG_ 2147484168 EngineSystemPowerDownRequest_ISi 1;
BA_ "SeToolAncestorID_SIGNAL" SG_ 2147484168 EngineSystemPowerDownRequest_ISi "x0000001D0436C642";
BA_ "SeToolItemID_SIGNAL" SG_ 2147484168 EngineSystemPowerDownRequest_ISi "x0000001D0436C642";
BA_ "SeToolName_SIGNAL" SG_ 2147484168 EngineSystemPowerDownRequest_ISi "EngineSystemPowerDownRequest";
BA_ "SeToolVersion_SIGNAL" SG_ 2147484168 EngineSystemPowerDownRequest_ISi "1";
BA_ "SystemSignalLongSymbol" SG_ 2147484168 EngineSystemPowerDownRequest_ISi "EngineSystemPowerDownRequest_ISig_4";
BA_ "GenSigSendType" SG_ 2671902706 FuncDiagDataTester_ISig_4 7;
BA_ "Platform_VMCU1_Sig" SG_ 2671902706 FuncDiagDataTester_ISig_4 1;
BA_ "GenSigSendType" SG_ 2147485094 TECU_BB2_06S_FCS 7;
BA_ "GenSigSendType" SG_ 2147485093 ECU5VIN_stat 1;
BA_ "GenSigMaxLatency" SG_ 2147485093 ECU5VIN_stat 1000;
BA_ "GenSigSendType" SG_ 2147484587 TECU_BB2_05S_FCS 7;
BA_ "GenSigSendType" SG_ 2147484586 KeyID_EncryptedGBUnlockAuth 1;
BA_ "GenSigMaxLatency" SG_ 2147484586 KeyID_EncryptedGBUnlockAuth 1000;
BA_ "GenSigSendType" SG_ 2147485128 TECU_BB2_04S_FCS 7;
BA_ "Platform_VMCU1_Sig" SG_ 2147485128 TECU_BB2_04S_FCS 1;
BA_ "GenSigSendType" SG_ 2147485127 HillDataPkgTECU_ISig_4 1;
BA_ "GenSigMaxLatency" SG_ 2147485127 HillDataPkgTECU_ISig_4 2500;
BA_ "Platform_VMCU1_Sig" SG_ 2147485127 HillDataPkgTECU_ISig_4 1;
BA_ "GenSigCycleTime" SG_ 2147484897 OilLevelDrvInstr_IncorrEngSpe 100;
BA_ "GenSigCycleTimeActive" SG_ 2147484897 OilLevelDrvInstr_IncorrEngSpe 100;
BA_ "GenSigStartValue" SG_ 2147484897 OilLevelDrvInstr_IncorrEngSpe 3;
BA_ "Platform_VMCU1_Sig" SG_ 2147484897 OilLevelDrvInstr_IncorrEngSpe 1;
BA_ "GenSigCycleTime" SG_ 2147484897 OilLevelDrvInstr_StopVehicle 100;
BA_ "GenSigCycleTimeActive" SG_ 2147484897 OilLevelDrvInstr_StopVehicle 100;
BA_ "GenSigStartValue" SG_ 2147484897 OilLevelDrvInstr_StopVehicle 3;
BA_ "Platform_VMCU1_Sig" SG_ 2147484897 OilLevelDrvInstr_StopVehicle 1;
BA_ "GenSigCycleTime" SG_ 2147484897 SchwungStatus 100;
BA_ "GenSigCycleTimeActive" SG_ 2147484897 SchwungStatus 100;
BA_ "GenSigStartValue" SG_ 2147484897 SchwungStatus 3;
BA_ "GenSigCycleTime" SG_ 2147484897 HillDataCtrlTECU_State_ISig_4 100;
BA_ "GenSigCycleTimeActive" SG_ 2147484897 HillDataCtrlTECU_State_ISig_4 100;
BA_ "GenSigStartValue" SG_ 2147484897 HillDataCtrlTECU_State_ISig_4 7;
BA_ "Platform_VMCU1_Sig" SG_ 2147484897 HillDataCtrlTECU_State_ISig_4 1;
BA_ "GenSigCycleTime" SG_ 2147484897 OilLevelDrvInstr_Wait60SecTxt 100;
BA_ "GenSigCycleTimeActive" SG_ 2147484897 OilLevelDrvInstr_Wait60SecTxt 100;
BA_ "GenSigStartValue" SG_ 2147484897 OilLevelDrvInstr_Wait60SecTxt 3;
BA_ "Platform_VMCU1_Sig" SG_ 2147484897 OilLevelDrvInstr_Wait60SecTxt 1;
BA_ "GenSigCycleTime" SG_ 2147484897 ClutchAbuseStatus 100;
BA_ "GenSigCycleTimeActive" SG_ 2147484897 ClutchAbuseStatus 100;
BA_ "GenSigStartValue" SG_ 2147484897 ClutchAbuseStatus 3;
BA_ "Platform_VMCU1_Sig" SG_ 2147484897 ClutchAbuseStatus 1;
BA_ "GenSigCycleTime" SG_ 2147484897 TransmissionSplitboxPTOMode 100;
BA_ "GenSigCycleTimeActive" SG_ 2147484897 TransmissionSplitboxPTOMode 100;
BA_ "GenSigStartValue" SG_ 2147484897 TransmissionSplitboxPTOMode 7;
BA_ "GenSigCycleTime" SG_ 2147484897 ClutchCalibration_stat 100;
BA_ "GenSigCycleTimeActive" SG_ 2147484897 ClutchCalibration_stat 100;
BA_ "GenSigStartValue" SG_ 2147484897 ClutchCalibration_stat 3;
BA_ "GenSigCycleTime" SG_ 2147484897 OilLevelDrvInstr_ChangeGearTxt 100;
BA_ "GenSigCycleTimeActive" SG_ 2147484897 OilLevelDrvInstr_ChangeGearTxt 100;
BA_ "GenSigStartValue" SG_ 2147484897 OilLevelDrvInstr_ChangeGearTxt 3;
BA_ "Platform_VMCU1_Sig" SG_ 2147484897 OilLevelDrvInstr_ChangeGearTxt 1;
BA_ "GenSigCycleTime" SG_ 2147484897 OilLevelDrvInstr_NotHorizonTxt 100;
BA_ "GenSigCycleTimeActive" SG_ 2147484897 OilLevelDrvInstr_NotHorizonTxt 100;
BA_ "GenSigStartValue" SG_ 2147484897 OilLevelDrvInstr_NotHorizonTxt 3;
BA_ "Platform_VMCU1_Sig" SG_ 2147484897 OilLevelDrvInstr_NotHorizonTxt 1;
BA_ "GenSigCycleTime" SG_ 2147484897 ISeeStatus 100;
BA_ "GenSigCycleTimeActive" SG_ 2147484897 ISeeStatus 100;
BA_ "GenSigStartValue" SG_ 2147484897 ISeeStatus 7;
BA_ "GenSigCycleTime" SG_ 2147484897 EcoRollEnabledStatus 100;
BA_ "GenSigCycleTimeActive" SG_ 2147484897 EcoRollEnabledStatus 100;
BA_ "GenSigStartValue" SG_ 2147484897 EcoRollEnabledStatus 3;
BA_ "GenSigCycleTime" SG_ 2147484897 OilLevelDrvInstr_OilTempTxt 100;
BA_ "GenSigCycleTimeActive" SG_ 2147484897 OilLevelDrvInstr_OilTempTxt 100;
BA_ "GenSigStartValue" SG_ 2147484897 OilLevelDrvInstr_OilTempTxt 3;
BA_ "Platform_VMCU1_Sig" SG_ 2147484897 OilLevelDrvInstr_OilTempTxt 1;
BA_ "GenSigCycleTime" SG_ 2147484897 HillDataCtrlTECU_AckCnt_ISig_4 100;
BA_ "GenSigCycleTimeActive" SG_ 2147484897 HillDataCtrlTECU_AckCnt_ISig_4 100;
BA_ "Platform_VMCU1_Sig" SG_ 2147484897 HillDataCtrlTECU_AckCnt_ISig_4 1;
BA_ "GenSigCycleTime" SG_ 2147484689 GearShiftingRec_Steps 100;
BA_ "GenSigCycleTimeActive" SG_ 2147484689 GearShiftingRec_Steps 100;
BA_ "GenSigStartValue" SG_ 2147484689 GearShiftingRec_Steps 7;
BA_ "GenSigCycleTime" SG_ 2147484689 GearShiftingRec_Direction 100;
BA_ "GenSigCycleTimeActive" SG_ 2147484689 GearShiftingRec_Direction 100;
BA_ "GenSigStartValue" SG_ 2147484689 GearShiftingRec_Direction 7;
BA_ "GenSigCycleTime" SG_ 2147484689 BrakeInterlockStatus 100;
BA_ "GenSigCycleTimeActive" SG_ 2147484689 BrakeInterlockStatus 100;
BA_ "Platform_VMCU1_Sig" SG_ 2147484689 BrakeInterlockStatus 1;
BA_ "GenSigCycleTime" SG_ 2147484689 AutGearSplitPosition 100;
BA_ "GenSigCycleTimeActive" SG_ 2147484689 AutGearSplitPosition 100;
BA_ "GenSigStartValue" SG_ 2147484689 AutGearSplitPosition 7;
BA_ "Platform_VMCU1_Sig" SG_ 2147484689 AutGearSplitPosition 1;
BA_ "GenSigCycleTime" SG_ 2147484689 TransmissionBrakeMode 100;
BA_ "GenSigCycleTimeActive" SG_ 2147484689 TransmissionBrakeMode 100;
BA_ "GenSigStartValue" SG_ 2147484689 TransmissionBrakeMode 3;
BA_ "GenSigCycleTime" SG_ 2147484689 AvailableGearsWithLowerRatio 100;
BA_ "GenSigCycleTimeActive" SG_ 2147484689 AvailableGearsWithLowerRatio 100;
BA_ "GenSigStartValue" SG_ 2147484689 AvailableGearsWithLowerRatio 15;
BA_ "GenSigMaxLatency" SG_ 2147484689 AvailableGearsWithLowerRatio 26;
BA_ "Platform_VMCU1_Sig" SG_ 2147484689 AvailableGearsWithLowerRatio 1;
BA_ "SeToolAncestorID_SIGNAL" SG_ 2147484689 AvailableGearsWithLowerRatio "x0000001D0416F544";
BA_ "SeToolItemID_SIGNAL" SG_ 2147484689 AvailableGearsWithLowerRatio "x0000001D0436DC28";
BA_ "SeToolName_SIGNAL" SG_ 2147484689 AvailableGearsWithLowerRatio "NumberOfAvailableGearsWithLowerRatio";
BA_ "SeToolVersion_SIGNAL" SG_ 2147484689 AvailableGearsWithLowerRatio "2";
BA_ "GenSigCycleTime" SG_ 2147484689 FuelEcoDrvStatus 100;
BA_ "GenSigCycleTimeActive" SG_ 2147484689 FuelEcoDrvStatus 100;
BA_ "GenSigStartValue" SG_ 2147484689 FuelEcoDrvStatus 3;
BA_ "Platform_VMCU1_Sig" SG_ 2147484689 FuelEcoDrvStatus 1;
BA_ "GenSigCycleTime" SG_ 2147484689 EcoCruiseStatus_ISig_4 100;
BA_ "GenSigCycleTimeActive" SG_ 2147484689 EcoCruiseStatus_ISig_4 100;
BA_ "GenSigStartValue" SG_ 2147484689 EcoCruiseStatus_ISig_4 7;
BA_ "Platform_VMCU1_Sig" SG_ 2147484689 EcoCruiseStatus_ISig_4 1;
BA_ "GenSigCycleTime" SG_ 2147484689 TransmissionDrivingMode 100;
BA_ "GenSigCycleTimeActive" SG_ 2147484689 TransmissionDrivingMode 100;
BA_ "GenSigStartValue" SG_ 2147484689 TransmissionDrivingMode 7;
BA_ "GenSigCycleTime" SG_ 2147484689 ClutchWearStatus 100;
BA_ "GenSigCycleTimeActive" SG_ 2147484689 ClutchWearStatus 100;
BA_ "GenSigStartValue" SG_ 2147484689 ClutchWearStatus 255;
BA_ "GenSigMaxLatency" SG_ 2147484689 ClutchWearStatus 26;
BA_ "Platform_VMCU1_Sig" SG_ 2147484689 ClutchWearStatus 1;
BA_ "SeToolAncestorID_SIGNAL" SG_ 2147484689 ClutchWearStatus "x0000001D0419DCE7";
BA_ "SeToolItemID_SIGNAL" SG_ 2147484689 ClutchWearStatus "x0000001D0419DCE7";
BA_ "SeToolName_SIGNAL" SG_ 2147484689 ClutchWearStatus "ClutchWearStatus";
BA_ "SeToolVersion_SIGNAL" SG_ 2147484689 ClutchWearStatus "1";
BA_ "GenSigCycleTime" SG_ 2147484689 AutoWheelBrakeInhibited 100;
BA_ "GenSigCycleTimeActive" SG_ 2147484689 AutoWheelBrakeInhibited 100;
BA_ "GenSigStartValue" SG_ 2147484689 AutoWheelBrakeInhibited 3;
BA_ "Platform_VMCU1_Sig" SG_ 2147484689 AutoWheelBrakeInhibited 1;
BA_ "GenSigCycleTime" SG_ 2147484689 DrivingMode_ISig_4 100;
BA_ "GenSigCycleTimeActive" SG_ 2147484689 DrivingMode_ISig_4 100;
BA_ "GenSigMaxLatency" SG_ 2147484689 DrivingMode_ISig_4 26;
BA_ "Platform_VMCU1_Sig" SG_ 2147484689 DrivingMode_ISig_4 1;
BA_ "SigType" SG_ 2147484689 DrivingMode_ISig_4 3;
BA_ "SeToolAncestorID_SIGNAL" SG_ 2147484689 DrivingMode_ISig_4 "x0000001D0413D7DC";
BA_ "SeToolItemID_SIGNAL" SG_ 2147484689 DrivingMode_ISig_4 "x0000001D0435EBD7";
BA_ "SeToolName_SIGNAL" SG_ 2147484689 DrivingMode_ISig_4 "DrivingMode";
BA_ "SeToolVersion_SIGNAL" SG_ 2147484689 DrivingMode_ISig_4 "4";
BA_ "GenSigCycleTime" SG_ 2147484689 AutoWheelBrakesDownshiftSugges 100;
BA_ "GenSigCycleTimeActive" SG_ 2147484689 AutoWheelBrakesDownshiftSugges 100;
BA_ "GenSigStartValue" SG_ 2147484689 AutoWheelBrakesDownshiftSugges 3;
BA_ "GenSigCycleTime" SG_ 2147484689 TransmissionOilTempHigh_ISig_4 100;
BA_ "GenSigCycleTimeActive" SG_ 2147484689 TransmissionOilTempHigh_ISig_4 100;
BA_ "GenSigStartValue" SG_ 2147484689 TransmissionOilTempHigh_ISig_4 7;
BA_ "GenSigMaxLatency" SG_ 2147484689 TransmissionOilTempHigh_ISig_4 26;
BA_ "Platform_VMCU1_Sig" SG_ 2147484689 TransmissionOilTempHigh_ISig_4 1;
BA_ "SeToolAncestorID_SIGNAL" SG_ 2147484689 TransmissionOilTempHigh_ISig_4 "x0000001D0415A8B5";
BA_ "SeToolItemID_SIGNAL" SG_ 2147484689 TransmissionOilTempHigh_ISig_4 "x0000001D04239BC4";
BA_ "SeToolName_SIGNAL" SG_ 2147484689 TransmissionOilTempHigh_ISig_4 "TransmissionOilTempHigh";
BA_ "SeToolVersion_SIGNAL" SG_ 2147484689 TransmissionOilTempHigh_ISig_4 "2";
BA_ "GenSigCycleTime" SG_ 2147484689 AvailableGearsWithHigherRatio 100;
BA_ "GenSigCycleTimeActive" SG_ 2147484689 AvailableGearsWithHigherRatio 100;
BA_ "GenSigStartValue" SG_ 2147484689 AvailableGearsWithHigherRatio 15;
BA_ "GenSigMaxLatency" SG_ 2147484689 AvailableGearsWithHigherRatio 26;
BA_ "Platform_VMCU1_Sig" SG_ 2147484689 AvailableGearsWithHigherRatio 1;
BA_ "SeToolAncestorID_SIGNAL" SG_ 2147484689 AvailableGearsWithHigherRatio "x0000001D0416F542";
BA_ "SeToolItemID_SIGNAL" SG_ 2147484689 AvailableGearsWithHigherRatio "x0000001D0436D7D6";
BA_ "SeToolName_SIGNAL" SG_ 2147484689 AvailableGearsWithHigherRatio "NumberOfAvailableGearsWithHigherRatio";
BA_ "SeToolVersion_SIGNAL" SG_ 2147484689 AvailableGearsWithHigherRatio "2";
BA_ "GenSigCycleTime" SG_ 2147484164 Pto1Consent_ISig_4 100;
BA_ "GenSigCycleTimeActive" SG_ 2147484164 Pto1Consent_ISig_4 100;
BA_ "GenSigStartValue" SG_ 2147484164 Pto1Consent_ISig_4 3;
BA_ "GenSigMaxLatency" SG_ 2147484164 Pto1Consent_ISig_4 26;
BA_ "Platform_VMCU1_Sig" SG_ 2147484164 Pto1Consent_ISig_4 1;
BA_ "SeToolAncestorID_SIGNAL" SG_ 2147484164 Pto1Consent_ISig_4 "x0000001D04156EBD";
BA_ "SeToolItemID_SIGNAL" SG_ 2147484164 Pto1Consent_ISig_4 "x0000001D043A5CEC";
BA_ "SeToolName_SIGNAL" SG_ 2147484164 Pto1Consent_ISig_4 "Pto1Consent";
BA_ "SeToolVersion_SIGNAL" SG_ 2147484164 Pto1Consent_ISig_4 "2";
BA_ "GenSigCycleTime" SG_ 2147484164 Pto2Consent_ISig_4 100;
BA_ "GenSigCycleTimeActive" SG_ 2147484164 Pto2Consent_ISig_4 100;
BA_ "GenSigStartValue" SG_ 2147484164 Pto2Consent_ISig_4 3;
BA_ "GenSigMaxLatency" SG_ 2147484164 Pto2Consent_ISig_4 26;
BA_ "Platform_VMCU1_Sig" SG_ 2147484164 Pto2Consent_ISig_4 1;
BA_ "SeToolAncestorID_SIGNAL" SG_ 2147484164 Pto2Consent_ISig_4 "x0000001D04156EBF";
BA_ "SeToolItemID_SIGNAL" SG_ 2147484164 Pto2Consent_ISig_4 "x0000001D043A5D14";
BA_ "SeToolName_SIGNAL" SG_ 2147484164 Pto2Consent_ISig_4 "Pto2Consent";
BA_ "SeToolVersion_SIGNAL" SG_ 2147484164 Pto2Consent_ISig_4 "2";
BA_ "GenSigCycleTime" SG_ 2147484164 DirectionGearAllowed 100;
BA_ "GenSigCycleTimeActive" SG_ 2147484164 DirectionGearAllowed 100;
BA_ "GenSigStartValue" SG_ 2147484164 DirectionGearAllowed 7;
BA_ "GenSigMaxLatency" SG_ 2147484164 DirectionGearAllowed 26;
BA_ "Platform_VMCU1_Sig" SG_ 2147484164 DirectionGearAllowed 1;
BA_ "SeToolAncestorID_SIGNAL" SG_ 2147484164 DirectionGearAllowed "x0000001D0416F6B7";
BA_ "SeToolItemID_SIGNAL" SG_ 2147484164 DirectionGearAllowed "x0000001D0416F6B7";
BA_ "SeToolName_SIGNAL" SG_ 2147484164 DirectionGearAllowed "DirectionGearAllowed";
BA_ "SeToolVersion_SIGNAL" SG_ 2147484164 DirectionGearAllowed "1";
BA_ "GenSigCycleTime" SG_ 2147484164 TransmissionSystemPowerDownAck 100;
BA_ "GenSigCycleTimeActive" SG_ 2147484164 TransmissionSystemPowerDownAck 100;
BA_ "GenSigStartValue" SG_ 2147484164 TransmissionSystemPowerDownAck 3;
BA_ "GenSigMaxLatency" SG_ 2147484164 TransmissionSystemPowerDownAck 26;
BA_ "Platform_VMCU1_Sig" SG_ 2147484164 TransmissionSystemPowerDownAck 1;
BA_ "SeToolAncestorID_SIGNAL" SG_ 2147484164 TransmissionSystemPowerDownAck "x0000001D0437CB4B";
BA_ "SeToolItemID_SIGNAL" SG_ 2147484164 TransmissionSystemPowerDownAck "x0000001D0437CB4B";
BA_ "SeToolName_SIGNAL" SG_ 2147484164 TransmissionSystemPowerDownAck "TransmissionSystemPowerDownAck";
BA_ "SeToolVersion_SIGNAL" SG_ 2147484164 TransmissionSystemPowerDownAck "1";
BA_ "GenSigCycleTime" SG_ 2147484164 EcoRollActiveStatus_ISig_4 100;
BA_ "GenSigCycleTimeActive" SG_ 2147484164 EcoRollActiveStatus_ISig_4 100;
BA_ "GenSigStartValue" SG_ 2147484164 EcoRollActiveStatus_ISig_4 3;
BA_ "GenSigMaxLatency" SG_ 2147484164 EcoRollActiveStatus_ISig_4 26;
BA_ "Platform_VMCU1_Sig" SG_ 2147484164 EcoRollActiveStatus_ISig_4 1;
BA_ "SeToolAncestorID_SIGNAL" SG_ 2147484164 EcoRollActiveStatus_ISig_4 "x0000001D043EEFC6";
BA_ "SeToolItemID_SIGNAL" SG_ 2147484164 EcoRollActiveStatus_ISig_4 "x0000001D043EEFC6";
BA_ "SeToolName_SIGNAL" SG_ 2147484164 EcoRollActiveStatus_ISig_4 "Eco-RollActiveStatus";
BA_ "SeToolVersion_SIGNAL" SG_ 2147484164 EcoRollActiveStatus_ISig_4 "1";
BA_ "GenSigCycleTime" SG_ 2147484164 TransmissionAirPressureLow 100;
BA_ "GenSigCycleTimeActive" SG_ 2147484164 TransmissionAirPressureLow 100;
BA_ "GenSigStartValue" SG_ 2147484164 TransmissionAirPressureLow 3;
BA_ "GenSigMaxLatency" SG_ 2147484164 TransmissionAirPressureLow 26;
BA_ "Platform_VMCU1_Sig" SG_ 2147484164 TransmissionAirPressureLow 1;
BA_ "SeToolAncestorID_SIGNAL" SG_ 2147484164 TransmissionAirPressureLow "x0000001D04215F7D";
BA_ "SeToolItemID_SIGNAL" SG_ 2147484164 TransmissionAirPressureLow "x0000001D04215F7D";
BA_ "SeToolName_SIGNAL" SG_ 2147484164 TransmissionAirPressureLow "TransmissionAirPressureLow";
BA_ "SeToolVersion_SIGNAL" SG_ 2147484164 TransmissionAirPressureLow "1";
BA_ "GenSigCycleTime" SG_ 2147484164 GearBoxUnlockAuth_rqst 100;
BA_ "GenSigCycleTimeActive" SG_ 2147484164 GearBoxUnlockAuth_rqst 100;
BA_ "GenSigStartValue" SG_ 2147484164 GearBoxUnlockAuth_rqst 3;
BA_ "GenSigCycleTime" SG_ 2147484164 TransmEngineStop_req 100;
BA_ "GenSigCycleTimeActive" SG_ 2147484164 TransmEngineStop_req 100;
BA_ "GenSigStartValue" SG_ 2147484164 TransmEngineStop_req 3;
BA_ "GenSigMaxLatency" SG_ 2147484164 TransmEngineStop_req 26;
BA_ "Platform_VMCU1_Sig" SG_ 2147484164 TransmEngineStop_req 1;
BA_ "GenSigCycleTime" SG_ 2147484164 RoadInclination_ISig_4 100;
BA_ "GenSigCycleTimeActive" SG_ 2147484164 RoadInclination_ISig_4 100;
BA_ "GenSigStartValue" SG_ 2147484164 RoadInclination_ISig_4 255;
BA_ "GenSigMaxLatency" SG_ 2147484164 RoadInclination_ISig_4 26;
BA_ "Platform_VMCU1_Sig" SG_ 2147484164 RoadInclination_ISig_4 1;
BA_ "SeToolAncestorID_SIGNAL" SG_ 2147484164 RoadInclination_ISig_4 "x0000001D043FA322";
BA_ "SeToolItemID_SIGNAL" SG_ 2147484164 RoadInclination_ISig_4 "x0000001D043FA322";
BA_ "SeToolName_SIGNAL" SG_ 2147484164 RoadInclination_ISig_4 "RoadInclination";
BA_ "SeToolVersion_SIGNAL" SG_ 2147484164 RoadInclination_ISig_4 "1";
BA_ "GenSigCycleTime" SG_ 2147484164 ACC_SGO_TransmissionStatus 100;
BA_ "GenSigCycleTimeActive" SG_ 2147484164 ACC_SGO_TransmissionStatus 100;
BA_ "GenSigStartValue" SG_ 2147484164 ACC_SGO_TransmissionStatus 7;
BA_ "Platform_VMCU1_Sig" SG_ 2147484164 ACC_SGO_TransmissionStatus 1;
BA_ "GenSigCycleTime" SG_ 2147484164 TransmOutputShaftSpeedSigned 100;
BA_ "GenSigCycleTimeActive" SG_ 2147484164 TransmOutputShaftSpeedSigned 100;
BA_ "GenSigStartValue" SG_ 2147484164 TransmOutputShaftSpeedSigned 65535;
BA_ "GenSigCycleTime" SG_ 2147484164 ClutchOverloadStatus_ISig_4 100;
BA_ "GenSigCycleTimeActive" SG_ 2147484164 ClutchOverloadStatus_ISig_4 100;
BA_ "GenSigStartValue" SG_ 2147484164 ClutchOverloadStatus_ISig_4 3;
BA_ "GenSigMaxLatency" SG_ 2147484164 ClutchOverloadStatus_ISig_4 26;
BA_ "Platform_VMCU1_Sig" SG_ 2147484164 ClutchOverloadStatus_ISig_4 1;
BA_ "SeToolAncestorID_SIGNAL" SG_ 2147484164 ClutchOverloadStatus_ISig_4 "x0000001D041744A1";
BA_ "SeToolItemID_SIGNAL" SG_ 2147484164 ClutchOverloadStatus_ISig_4 "x0000001D041744A1";
BA_ "SeToolName_SIGNAL" SG_ 2147484164 ClutchOverloadStatus_ISig_4 "ClutchOverloadStatus";
BA_ "SeToolVersion_SIGNAL" SG_ 2147484164 ClutchOverloadStatus_ISig_4 "1";
BA_ "GenSigSendType" SG_ 2671833830 PhysDiagRespSig_F2_E6_ISig_4 7;
BA_ "Platform_VMCU1_Sig" SG_ 2671833830 PhysDiagRespSig_F2_E6_ISig_4 1;
BA_ "GenSigSendType" SG_ 2671833829 PhysDiagRespSig_F2_E5_ISig_4 7;
BA_ "GenSigSendType" SG_ 2671833792 PhysDiagRespSig_F2_C0_ISig_4 7;
BA_ "Platform_VMCU1_Sig" SG_ 2671833792 PhysDiagRespSig_F2_C0_ISig_4 1;
BA_ "GenSigSendType" SG_ 2671833762 PhysDiagRespSig_F2_A2_ISig_4 7;
BA_ "Platform_VMCU1_Sig" SG_ 2671833762 PhysDiagRespSig_F2_A2_ISig_4 1;
BA_ "GenSigSendType" SG_ 2671833761 PhysDiagRespSig_F2_A1_ISig_4 7;
BA_ "Platform_VMCU1_Sig" SG_ 2671833761 PhysDiagRespSig_F2_A1_ISig_4 1;
BA_ "GenSigSendType" SG_ 2671833760 PhysDiagRespSig_F2_A0_ISig_4 7;
BA_ "Platform_VMCU1_Sig" SG_ 2671833760 PhysDiagRespSig_F2_A0_ISig_4 1;
BA_ "GenSigSendType" SG_ 2671833752 PhysDiagRespSig_F2_98_ISig_4 7;
BA_ "Platform_VMCU1_Sig" SG_ 2671833752 PhysDiagRespSig_F2_98_ISig_4 1;
BA_ "GenSigSendType" SG_ 2671833731 PhysDiagRespSig_F2_83_ISig_4 7;
BA_ "GenSigSendType" SG_ 2671833730 PhysDiagRespSig_F2_82_ISig_4 7;
BA_ "Platform_VMCU1_Sig" SG_ 2671833730 PhysDiagRespSig_F2_82_ISig_4 1;
BA_ "GenSigSendType" SG_ 2671833697 PhysDiagRespSig_F2_61_ISig_4 7;
BA_ "Platform_VMCU1_Sig" SG_ 2671833697 PhysDiagRespSig_F2_61_ISig_4 1;
BA_ "GenSigSendType" SG_ 2671833696 PhysDiagRespSig_F2_60_ISig_4 7;
BA_ "Platform_VMCU1_Sig" SG_ 2671833696 PhysDiagRespSig_F2_60_ISig_4 1;
BA_ "GenSigSendType" SG_ 2671833683 PhysDiagRespSig_F2_53_ISig_4 7;
BA_ "Platform_VMCU1_Sig" SG_ 2671833683 PhysDiagRespSig_F2_53_ISig_4 1;
BA_ "GenSigSendType" SG_ 2671833682 PhysDiagRespSig_F2_52_ISig_4 7;
BA_ "Platform_VMCU1_Sig" SG_ 2671833682 PhysDiagRespSig_F2_52_ISig_4 1;
BA_ "GenSigSendType" SG_ 2671833681 PhysDiagRespSig_F2_51_ISig_4 7;
BA_ "Platform_VMCU1_Sig" SG_ 2671833681 PhysDiagRespSig_F2_51_ISig_4 1;
BA_ "GenSigSendType" SG_ 2671833680 PhysDiagRespSig_F2_50_ISig_4 7;
BA_ "Platform_VMCU1_Sig" SG_ 2671833680 PhysDiagRespSig_F2_50_ISig_4 1;
BA_ "GenSigSendType" SG_ 2671833665 PhysDiagRespSig_F2_41_ISig_4 7;
BA_ "Platform_VMCU1_Sig" SG_ 2671833665 PhysDiagRespSig_F2_41_ISig_4 1;
BA_ "GenSigSendType" SG_ 2671833664 PhysDiagRespSig_F2_40_ISig_4 7;
BA_ "Platform_VMCU1_Sig" SG_ 2671833664 PhysDiagRespSig_F2_40_ISig_4 1;
BA_ "GenSigSendType" SG_ 2671833638 PhysDiagRespSig_F2_26_ISig_4 7;
BA_ "Platform_VMCU1_Sig" SG_ 2671833638 PhysDiagRespSig_F2_26_ISig_4 1;
BA_ "GenSigSendType" SG_ 2671833624 PhysDiagRespSig_F2_18_ISig_4 7;
BA_ "Platform_VMCU1_Sig" SG_ 2671833624 PhysDiagRespSig_F2_18_ISig_4 1;
BA_ "GenSigSendType" SG_ 2671833616 PhysDiagRespSig_F2_10_ISig_4 7;
BA_ "Platform_VMCU1_Sig" SG_ 2671833616 PhysDiagRespSig_F2_10_ISig_4 1;
BA_ "GenSigSendType" SG_ 2564485459 PhysDiagRespSig_F1_53_ISig_4 7;
BA_ "Platform_VMCU1_Sig" SG_ 2564485459 PhysDiagRespSig_F1_53_ISig_4 1;
BA_ "GenSigSendType" SG_ 2564485392 PhysDiagRespSig_F1_10_extra 7;
BA_ "Platform_VMCU1_Sig" SG_ 2564485392 PhysDiagRespSig_F1_10_extra 1;
BA_ "GenSigSendType" SG_ 2671833360 PhysDiagRespSig_F1_10_ISig_4 7;
BA_ "Platform_VMCU1_Sig" SG_ 2671833360 PhysDiagRespSig_F1_10_ISig_4 1;
BA_ "GenSigSendType" SG_ 2671833700 PhysDiagRespSig_F2_64_ISig_4 7;
BA_ "GenSigSendType" SG_ 2671830770 PhysDiagReqSig_E6_F2_ISig_4 7;
BA_ "Platform_VMCU1_Sig" SG_ 2671830770 PhysDiagReqSig_E6_F2_ISig_4 1;
BA_ "GenSigSendType" SG_ 2671830514 PhysDiagReqSig_E5_F2_ISig_4 7;
BA_ "GenSigSendType" SG_ 2671821042 PhysDiagReqSig_C0_F2_ISig_4 7;
BA_ "Platform_VMCU1_Sig" SG_ 2671821042 PhysDiagReqSig_C0_F2_ISig_4 1;
BA_ "GenSigSendType" SG_ 2671813362 PhysDiagReqSig_A2_F2_ISig_4 7;
BA_ "Platform_VMCU1_Sig" SG_ 2671813362 PhysDiagReqSig_A2_F2_ISig_4 1;
BA_ "GenSigSendType" SG_ 2671813106 PhysDiagReqSig_A1_F2_ISig_4 7;
BA_ "Platform_VMCU1_Sig" SG_ 2671813106 PhysDiagReqSig_A1_F2_ISig_4 1;
BA_ "GenSigSendType" SG_ 2671812850 PhysDiagReqSig_A0_F2_ISig_4 7;
BA_ "Platform_VMCU1_Sig" SG_ 2671812850 PhysDiagReqSig_A0_F2_ISig_4 1;
BA_ "GenSigSendType" SG_ 2671810802 PhysDiagReqSig_98_F2_ISig_4 7;
BA_ "Platform_VMCU1_Sig" SG_ 2671810802 PhysDiagReqSig_98_F2_ISig_4 1;
BA_ "GenSigSendType" SG_ 2671805426 PhysDiagReqSig_83_F2_ISig_4 7;
BA_ "GenSigSendType" SG_ 2671805170 PhysDiagReqSig_82_F2_ISig_4 7;
BA_ "Platform_VMCU1_Sig" SG_ 2671805170 PhysDiagReqSig_82_F2_ISig_4 1;
BA_ "GenSigSendType" SG_ 2671797490 PhysDiagReqSig_64_F2_ISig_4 7;
BA_ "GenSigSendType" SG_ 2671796722 PhysDiagReqSig_61_F2_ISig_4 7;
BA_ "Platform_VMCU1_Sig" SG_ 2671796722 PhysDiagReqSig_61_F2_ISig_4 1;
BA_ "GenSigSendType" SG_ 2671796466 PhysDiagReqSig_60_F2_ISig_4 7;
BA_ "Platform_VMCU1_Sig" SG_ 2671796466 PhysDiagReqSig_60_F2_ISig_4 1;
BA_ "GenSigSendType" SG_ 2671793138 PhysDiagReqSig_53_F2_ISig_4 7;
BA_ "Platform_VMCU1_Sig" SG_ 2671793138 PhysDiagReqSig_53_F2_ISig_4 1;
BA_ "GenSigSendType" SG_ 2564445169 PhysDiagReqSig_53_F1_ISig_4 7;
BA_ "Platform_VMCU1_Sig" SG_ 2564445169 PhysDiagReqSig_53_F1_ISig_4 1;
BA_ "GenSigSendType" SG_ 2671792882 PhysDiagReqSig_52_F2_ISig_4 7;
BA_ "Platform_VMCU1_Sig" SG_ 2671792882 PhysDiagReqSig_52_F2_ISig_4 1;
BA_ "GenSigSendType" SG_ 2671792626 PhysDiagReqSig_51_F2_ISig_4 7;
BA_ "Platform_VMCU1_Sig" SG_ 2671792626 PhysDiagReqSig_51_F2_ISig_4 1;
BA_ "GenSigSendType" SG_ 2671792370 PhysDiagReqSig_50_F2_ISig_4 7;
BA_ "Platform_VMCU1_Sig" SG_ 2671792370 PhysDiagReqSig_50_F2_ISig_4 1;
BA_ "GenSigSendType" SG_ 2671788530 PhysDiagReqSig_41_F2_ISig_4 7;
BA_ "Platform_VMCU1_Sig" SG_ 2671788530 PhysDiagReqSig_41_F2_ISig_4 1;
BA_ "GenSigSendType" SG_ 2671788274 PhysDiagReqSig_40_F2_ISig_4 7;
BA_ "Platform_VMCU1_Sig" SG_ 2671788274 PhysDiagReqSig_40_F2_ISig_4 1;
BA_ "GenSigSendType" SG_ 2671781618 PhysDiagReqSig_26_F2_ISig_4 7;
BA_ "Platform_VMCU1_Sig" SG_ 2671781618 PhysDiagReqSig_26_F2_ISig_4 1;
BA_ "GenSigSendType" SG_ 2671778034 PhysDiagReqSig_18_F2_ISig_4 7;
BA_ "Platform_VMCU1_Sig" SG_ 2671778034 PhysDiagReqSig_18_F2_ISig_4 1;
BA_ "GenSigSendType" SG_ 2671775986 PhysDiagReqSig_10_F2_ISig_4 7;
BA_ "Platform_VMCU1_Sig" SG_ 2671775986 PhysDiagReqSig_10_F2_ISig_4 1;
BA_ "GenSigSendType" SG_ 2564428017 PhysDiagReqSig_10_F1_extra 7;
BA_ "Platform_VMCU1_Sig" SG_ 2564428017 PhysDiagReqSig_10_F1_extra 1;
BA_ "GenSigSendType" SG_ 2671775985 PhysDiagReqSig_10_F1_ISig_4 7;
BA_ "Platform_VMCU1_Sig" SG_ 2671775985 PhysDiagReqSig_10_F1_ISig_4 1;
BA_ "GenSigSendType" SG_ 2564502513 FuncDiagDataOBD_extra 7;
BA_ "Platform_VMCU1_Sig" SG_ 2564502513 FuncDiagDataOBD_extra 1;
BA_REL_ "GenSigFirstTimeoutTime" BU_SG_REL_ BBM SG_ 2147484579 Pto1BadCondition 3000;
BA_REL_ "GenSigTimeoutTime" BU_SG_REL_ BBM SG_ 2147484579 Pto1BadCondition 450;
BA_REL_ "GenSigFirstTimeoutTime" BU_SG_REL_ IC3 SG_ 2147484579 Pto1BadCondition 3000;
BA_REL_ "GenSigTimeoutTime" BU_SG_REL_ IC3 SG_ 2147484579 Pto1BadCondition 450;
BA_REL_ "GenSigFirstTimeoutTime" BU_SG_REL_ IC3 SG_ 2147484579 Pto4BadCondition 3000;
BA_REL_ "GenSigTimeoutTime" BU_SG_REL_ IC3 SG_ 2147484579 Pto4BadCondition 450;
BA_REL_ "GenSigFirstTimeoutTime" BU_SG_REL_ BBM SG_ 2147484579 Pto4BadCondition 3000;
BA_REL_ "GenSigTimeoutTime" BU_SG_REL_ BBM SG_ 2147484579 Pto4BadCondition 450;
BA_REL_ "GenSigFirstTimeoutTime" BU_SG_REL_ IC3 SG_ 2147484579 Pto2BadCondition 3000;
BA_REL_ "GenSigTimeoutTime" BU_SG_REL_ IC3 SG_ 2147484579 Pto2BadCondition 450;
BA_REL_ "GenSigFirstTimeoutTime" BU_SG_REL_ BBM SG_ 2147484579 Pto2BadCondition 3000;
BA_REL_ "GenSigTimeoutTime" BU_SG_REL_ BBM SG_ 2147484579 Pto2BadCondition 450;
BA_REL_ "GenSigFirstTimeoutTime" BU_SG_REL_ EMS SG_ 2147484579 PtoRequest 3000;
BA_REL_ "GenSigTimeoutTime" BU_SG_REL_ EMS SG_ 2147484579 PtoRequest 450;
BA_REL_ "GenSigFirstTimeoutTime" BU_SG_REL_ TECU SG_ 2147484579 Pto2ConsentRequest 3000;
BA_REL_ "GenSigTimeoutTime" BU_SG_REL_ TECU SG_ 2147484579 Pto2ConsentRequest 450;
BA_REL_ "GenSigFirstTimeoutTime" BU_SG_REL_ IC3 SG_ 2147484579 PBStatusDisplay_cmd_ISig_4 3000;
BA_REL_ "GenSigTimeoutTime" BU_SG_REL_ IC3 SG_ 2147484579 PBStatusDisplay_cmd_ISig_4 450;
BA_REL_ "GenSigFirstTimeoutTime" BU_SG_REL_ BBM SG_ 2147484579 Pto4DrivingRequest 3000;
BA_REL_ "GenSigTimeoutTime" BU_SG_REL_ BBM SG_ 2147484579 Pto4DrivingRequest 450;
BA_REL_ "GenSigFirstTimeoutTime" BU_SG_REL_ CIOM SG_ 2147484579 Pto3Indication 3000;
BA_REL_ "GenSigTimeoutTime" BU_SG_REL_ CIOM SG_ 2147484579 Pto3Indication 450;
BA_REL_ "GenSigFirstTimeoutTime" BU_SG_REL_ IC3 SG_ 2147484579 Pto2Status_ISig_4 3000;
BA_REL_ "GenSigTimeoutTime" BU_SG_REL_ IC3 SG_ 2147484579 Pto2Status_ISig_4 450;
BA_REL_ "GenSigFirstTimeoutTime" BU_SG_REL_ TECU SG_ 2147484579 Pto2Status_ISig_4 3000;
BA_REL_ "GenSigTimeoutTime" BU_SG_REL_ TECU SG_ 2147484579 Pto2Status_ISig_4 450;
BA_REL_ "GenSigFirstTimeoutTime" BU_SG_REL_ CIOM SG_ 2147484579 Pto2Status_ISig_4 3000;
BA_REL_ "GenSigTimeoutTime" BU_SG_REL_ CIOM SG_ 2147484579 Pto2Status_ISig_4 450;
BA_REL_ "GenSigFirstTimeoutTime" BU_SG_REL_ BBM SG_ 2147484579 Pto2Status_ISig_4 3000;
BA_REL_ "GenSigTimeoutTime" BU_SG_REL_ BBM SG_ 2147484579 Pto2Status_ISig_4 450;
BA_REL_ "GenSigFirstTimeoutTime" BU_SG_REL_ CIOM SG_ 2147484579 Pto4Status_ISig_4 3000;
BA_REL_ "GenSigTimeoutTime" BU_SG_REL_ CIOM SG_ 2147484579 Pto4Status_ISig_4 450;
BA_REL_ "GenSigFirstTimeoutTime" BU_SG_REL_ IC3 SG_ 2147484579 Pto4Status_ISig_4 3000;
BA_REL_ "GenSigTimeoutTime" BU_SG_REL_ IC3 SG_ 2147484579 Pto4Status_ISig_4 450;
BA_REL_ "GenSigFirstTimeoutTime" BU_SG_REL_ BBM SG_ 2147484579 Pto4Status_ISig_4 3000;
BA_REL_ "GenSigTimeoutTime" BU_SG_REL_ BBM SG_ 2147484579 Pto4Status_ISig_4 450;
BA_REL_ "GenSigFirstTimeoutTime" BU_SG_REL_ CIOM SG_ 2147484579 RampLevelRequestACK_ISig_4 3000;
BA_REL_ "GenSigTimeoutTime" BU_SG_REL_ CIOM SG_ 2147484579 RampLevelRequestACK_ISig_4 450;
BA_REL_ "GenSigFirstTimeoutTime" BU_SG_REL_ IC3 SG_ 2147484579 Pto3BadCondition 3000;
BA_REL_ "GenSigTimeoutTime" BU_SG_REL_ IC3 SG_ 2147484579 Pto3BadCondition 450;
BA_REL_ "GenSigFirstTimeoutTime" BU_SG_REL_ BBM SG_ 2147484579 Pto3BadCondition 3000;
BA_REL_ "GenSigTimeoutTime" BU_SG_REL_ BBM SG_ 2147484579 Pto3BadCondition 450;
BA_REL_ "GenSigFirstTimeoutTime" BU_SG_REL_ BBM SG_ 2147484579 PtosStatus_ISig_4 3000;
BA_REL_ "GenSigTimeoutTime" BU_SG_REL_ BBM SG_ 2147484579 PtosStatus_ISig_4 600;
BA_REL_ "GenSigFirstTimeoutTime" BU_SG_REL_ CIOM SG_ 2147484579 PtosStatus_ISig_4 3000;
BA_REL_ "GenSigTimeoutTime" BU_SG_REL_ CIOM SG_ 2147484579 PtosStatus_ISig_4 600;
BA_REL_ "GenSigFirstTimeoutTime" BU_SG_REL_ EMS SG_ 2147484579 PtosStatus_ISig_4 3000;
BA_REL_ "GenSigTimeoutTime" BU_SG_REL_ EMS SG_ 2147484579 PtosStatus_ISig_4 600;
BA_REL_ "GenSigFirstTimeoutTime" BU_SG_REL_ IC3 SG_ 2147484579 PtosStatus_ISig_4 3000;
BA_REL_ "GenSigTimeoutTime" BU_SG_REL_ IC3 SG_ 2147484579 PtosStatus_ISig_4 450;
BA_REL_ "GenSigFirstTimeoutTime" BU_SG_REL_ BBM SG_ 2147484579 FrontWheelDriveAutoStatus_ISig_4 3000;
BA_REL_ "GenSigTimeoutTime" BU_SG_REL_ BBM SG_ 2147484579 FrontWheelDriveAutoStatus_ISig_4 450;
BA_REL_ "GenSigFirstTimeoutTime" BU_SG_REL_ IC3 SG_ 2147484579 FrontWheelDriveAutoStatus_ISig_4 3000;
BA_REL_ "GenSigTimeoutTime" BU_SG_REL_ IC3 SG_ 2147484579 FrontWheelDriveAutoStatus_ISig_4 450;
BA_REL_ "GenSigFirstTimeoutTime" BU_SG_REL_ TECU SG_ 2147484579 Pto1ConsentRequest 3000;
BA_REL_ "GenSigTimeoutTime" BU_SG_REL_ TECU SG_ 2147484579 Pto1ConsentRequest 450;
BA_REL_ "GenSigFirstTimeoutTime" BU_SG_REL_ CIOM SG_ 2147484579 Pto4Indication 3000;
BA_REL_ "GenSigTimeoutTime" BU_SG_REL_ CIOM SG_ 2147484579 Pto4Indication 450;
BA_REL_ "GenSigFirstTimeoutTime" BU_SG_REL_ CIOM SG_ 2147484579 Pto1Indication 3000;
BA_REL_ "GenSigTimeoutTime" BU_SG_REL_ CIOM SG_ 2147484579 Pto1Indication 450;
BA_REL_ "GenSigFirstTimeoutTime" BU_SG_REL_ BBM SG_ 2147484579 Pto3Status_ISig_4 3000;
BA_REL_ "GenSigTimeoutTime" BU_SG_REL_ BBM SG_ 2147484579 Pto3Status_ISig_4 450;
BA_REL_ "GenSigFirstTimeoutTime" BU_SG_REL_ IC3 SG_ 2147484579 Pto3Status_ISig_4 3000;
BA_REL_ "GenSigTimeoutTime" BU_SG_REL_ IC3 SG_ 2147484579 Pto3Status_ISig_4 450;
BA_REL_ "GenSigFirstTimeoutTime" BU_SG_REL_ CIOM SG_ 2147484579 Pto3Status_ISig_4 3000;
BA_REL_ "GenSigTimeoutTime" BU_SG_REL_ CIOM SG_ 2147484579 Pto3Status_ISig_4 450;
BA_REL_ "GenSigFirstTimeoutTime" BU_SG_REL_ CIOM SG_ 2147484579 Pto2Indication 3000;
BA_REL_ "GenSigTimeoutTime" BU_SG_REL_ CIOM SG_ 2147484579 Pto2Indication 450;
BA_REL_ "GenSigFirstTimeoutTime" BU_SG_REL_ BBM SG_ 2147484579 Pto1FeedbackStatus_ISig_4 3000;
BA_REL_ "GenSigTimeoutTime" BU_SG_REL_ BBM SG_ 2147484579 Pto1FeedbackStatus_ISig_4 500;
BA_REL_ "GenSigFirstTimeoutTime" BU_SG_REL_ TECU SG_ 2147484579 TransferCaseOrSplitboxPTOMode_IS 3000;
BA_REL_ "GenSigTimeoutTime" BU_SG_REL_ TECU SG_ 2147484579 TransferCaseOrSplitboxPTOMode_IS 450;
BA_REL_ "GenSigFirstTimeoutTime" BU_SG_REL_ BBM SG_ 2147484579 TransferCaseOrSplitboxPTOMode_IS 3000;
BA_REL_ "GenSigTimeoutTime" BU_SG_REL_ BBM SG_ 2147484579 TransferCaseOrSplitboxPTOMode_IS 450;
BA_REL_ "GenSigFirstTimeoutTime" BU_SG_REL_ IC3 SG_ 2147484579 DirIndRearLamp_Stat_ISig_4 3000;
BA_REL_ "GenSigTimeoutTime" BU_SG_REL_ IC3 SG_ 2147484579 DirIndRearLamp_Stat_ISig_4 450;
BA_REL_ "GenSigFirstTimeoutTime" BU_SG_REL_ CIOM SG_ 2147484579 Pto1Status_ISig_4 3000;
BA_REL_ "GenSigTimeoutTime" BU_SG_REL_ CIOM SG_ 2147484579 Pto1Status_ISig_4 450;
BA_REL_ "GenSigFirstTimeoutTime" BU_SG_REL_ TECU SG_ 2147484579 Pto1Status_ISig_4 3000;
BA_REL_ "GenSigTimeoutTime" BU_SG_REL_ TECU SG_ 2147484579 Pto1Status_ISig_4 450;
BA_REL_ "GenSigFirstTimeoutTime" BU_SG_REL_ BBM SG_ 2147484579 Pto1Status_ISig_4 3000;
BA_REL_ "GenSigTimeoutTime" BU_SG_REL_ BBM SG_ 2147484579 Pto1Status_ISig_4 450;
BA_REL_ "GenSigFirstTimeoutTime" BU_SG_REL_ IC3 SG_ 2147484579 Pto1Status_ISig_4 3000;
BA_REL_ "GenSigTimeoutTime" BU_SG_REL_ IC3 SG_ 2147484579 Pto1Status_ISig_4 450;
BA_REL_ "GenSigFirstTimeoutTime" BU_SG_REL_ BBM SG_ 2147484579 Pto3DrivingRequest 3000;
BA_REL_ "GenSigTimeoutTime" BU_SG_REL_ BBM SG_ 2147484579 Pto3DrivingRequest 450;
BA_REL_ "GenSigFirstTimeoutTime" BU_SG_REL_ EMS SG_ 2147484379 CCBTargetSpeedRequest 3000;
BA_REL_ "GenSigTimeoutTime" BU_SG_REL_ EMS SG_ 2147484379 CCBTargetSpeedRequest 270;
BA_REL_ "GenSigFirstTimeoutTime" BU_SG_REL_ TECU SG_ 2147484379 CCBTargetSpeedRequest 3000;
BA_REL_ "GenSigTimeoutTime" BU_SG_REL_ TECU SG_ 2147484379 CCBTargetSpeedRequest 270;
BA_REL_ "GenSigFirstTimeoutTime" BU_SG_REL_ IC3 SG_ 2147484379 EngineStartControlStatus_ISig_4 3000;
BA_REL_ "GenSigTimeoutTime" BU_SG_REL_ IC3 SG_ 2147484379 EngineStartControlStatus_ISig_4 270;
BA_REL_ "GenSigFirstTimeoutTime" BU_SG_REL_ BBM SG_ 2147484379 EngineStartControlStatus_ISig_4 3000;
BA_REL_ "GenSigTimeoutTime" BU_SG_REL_ BBM SG_ 2147484379 EngineStartControlStatus_ISig_4 270;
BA_REL_ "GenSigFirstTimeoutTime" BU_SG_REL_ TECU SG_ 2147484379 CCTargetSpeedRequest 3000;
BA_REL_ "GenSigTimeoutTime" BU_SG_REL_ TECU SG_ 2147484379 CCTargetSpeedRequest 270;
BA_REL_ "GenSigFirstTimeoutTime" BU_SG_REL_ EMS SG_ 2147484379 CCTargetSpeedRequest 3000;
BA_REL_ "GenSigTimeoutTime" BU_SG_REL_ EMS SG_ 2147484379 CCTargetSpeedRequest 270;
BA_REL_ "GenSigFirstTimeoutTime" BU_SG_REL_ IC3 SG_ 2147484373 StoreIdleValue 3000;
BA_REL_ "GenSigTimeoutTime" BU_SG_REL_ IC3 SG_ 2147484373 StoreIdleValue 270;
BA_REL_ "GenSigFirstTimeoutTime" BU_SG_REL_ EMS SG_ 2147484373 StoreIdleValue 3000;
BA_REL_ "GenSigTimeoutTime" BU_SG_REL_ EMS SG_ 2147484373 StoreIdleValue 270;
BA_REL_ "GenSigFirstTimeoutTime" BU_SG_REL_ EMS SG_ 2147484373 ESCReqEMS_CtrlTrimMode_ISig_4 3000;
BA_REL_ "GenSigTimeoutTime" BU_SG_REL_ EMS SG_ 2147484373 ESCReqEMS_CtrlTrimMode_ISig_4 270;
BA_REL_ "GenSigFirstTimeoutTime" BU_SG_REL_ TECU SG_ 2147484373 ESCReqEMS_CtrlTrimMode_ISig_4 3000;
BA_REL_ "GenSigTimeoutTime" BU_SG_REL_ TECU SG_ 2147484373 ESCReqEMS_CtrlTrimMode_ISig_4 300;
BA_REL_ "GenSigFirstTimeoutTime" BU_SG_REL_ IC3 SG_ 2147484373 ESCReqEMS_CtrlTrimMode_ISig_4 3000;
BA_REL_ "GenSigTimeoutTime" BU_SG_REL_ IC3 SG_ 2147484373 ESCReqEMS_CtrlTrimMode_ISig_4 270;
BA_REL_ "GenSigFirstTimeoutTime" BU_SG_REL_ CIOM SG_ 2147484373 ESCReqESC_CtrlTrimMode_ISig_4 3000;
BA_REL_ "GenSigTimeoutTime" BU_SG_REL_ CIOM SG_ 2147484373 ESCReqESC_CtrlTrimMode_ISig_4 270;
BA_REL_ "GenSigFirstTimeoutTime" BU_SG_REL_ IC3 SG_ 2147484373 ESCReqESC_CtrlTrimMode_ISig_4 3000;
BA_REL_ "GenSigTimeoutTime" BU_SG_REL_ IC3 SG_ 2147484373 ESCReqESC_CtrlTrimMode_ISig_4 270;
BA_REL_ "GenSigFirstTimeoutTime" BU_SG_REL_ BBM SG_ 2147484373 ESCReqESC_CtrlTrimMode_ISig_4 3000;
BA_REL_ "GenSigTimeoutTime" BU_SG_REL_ BBM SG_ 2147484373 ESCReqESC_CtrlTrimMode_ISig_4 270;
BA_REL_ "GenSigFirstTimeoutTime" BU_SG_REL_ IC3 SG_ 2147484373 ESCReqEMS_CtrlTrimStat_ISig_4 3000;
BA_REL_ "GenSigTimeoutTime" BU_SG_REL_ IC3 SG_ 2147484373 ESCReqEMS_CtrlTrimStat_ISig_4 270;
BA_REL_ "GenSigFirstTimeoutTime" BU_SG_REL_ EMS SG_ 2147484373 ESCReqEMS_CtrlTrimStat_ISig_4 3000;
BA_REL_ "GenSigTimeoutTime" BU_SG_REL_ EMS SG_ 2147484373 ESCReqEMS_CtrlTrimStat_ISig_4 270;
BA_REL_ "GenSigFirstTimeoutTime" BU_SG_REL_ TECU SG_ 2147484373 ESCReqEMS_CtrlTrimStat_ISig_4 3000;
BA_REL_ "GenSigTimeoutTime" BU_SG_REL_ TECU SG_ 2147484373 ESCReqEMS_CtrlTrimStat_ISig_4 300;
BA_REL_ "GenSigFirstTimeoutTime" BU_SG_REL_ TECU SG_ 2147484373 TrailerConnected_ISig_4 3000;
BA_REL_ "GenSigTimeoutTime" BU_SG_REL_ TECU SG_ 2147484373 TrailerConnected_ISig_4 500;
BA_REL_ "GenSigFirstTimeoutTime" BU_SG_REL_ IC3 SG_ 2147484373 TrailerConnected_ISig_4 3000;
BA_REL_ "GenSigTimeoutTime" BU_SG_REL_ IC3 SG_ 2147484373 TrailerConnected_ISig_4 500;
BA_REL_ "GenSigFirstTimeoutTime" BU_SG_REL_ EMS SG_ 2147484373 TrailerConnected_ISig_4 3000;
BA_REL_ "GenSigTimeoutTime" BU_SG_REL_ EMS SG_ 2147484373 TrailerConnected_ISig_4 500;
BA_REL_ "GenSigFirstTimeoutTime" BU_SG_REL_ DACU SG_ 2147484373 TrailerConnected_ISig_4 3000;
BA_REL_ "GenSigTimeoutTime" BU_SG_REL_ DACU SG_ 2147484373 TrailerConnected_ISig_4 500;
BA_REL_ "GenSigFirstTimeoutTime" BU_SG_REL_ BBM SG_ 2147484373 TrailerConnected_ISig_4 3000;
BA_REL_ "GenSigTimeoutTime" BU_SG_REL_ BBM SG_ 2147484373 TrailerConnected_ISig_4 500;
BA_REL_ "GenSigFirstTimeoutTime" BU_SG_REL_ BBM SG_ 2147484373 ESCReqESC_CtrlTrimValue_ISig_4 3000;
BA_REL_ "GenSigTimeoutTime" BU_SG_REL_ BBM SG_ 2147484373 ESCReqESC_CtrlTrimValue_ISig_4 270;
BA_REL_ "GenSigFirstTimeoutTime" BU_SG_REL_ IC3 SG_ 2147484373 ESCReqESC_CtrlTrimValue_ISig_4 3000;
BA_REL_ "GenSigTimeoutTime" BU_SG_REL_ IC3 SG_ 2147484373 ESCReqESC_CtrlTrimValue_ISig_4 270;
BA_REL_ "GenSigFirstTimeoutTime" BU_SG_REL_ CIOM SG_ 2147484373 ESCReqESC_CtrlTrimValue_ISig_4 3000;
BA_REL_ "GenSigTimeoutTime" BU_SG_REL_ CIOM SG_ 2147484373 ESCReqESC_CtrlTrimValue_ISig_4 270;
BA_REL_ "GenSigFirstTimeoutTime" BU_SG_REL_ CIOM SG_ 2147484373 ESCReqESC_CtrlTrimStat_ISig_4 3000;
BA_REL_ "GenSigTimeoutTime" BU_SG_REL_ CIOM SG_ 2147484373 ESCReqESC_CtrlTrimStat_ISig_4 270;
BA_REL_ "GenSigFirstTimeoutTime" BU_SG_REL_ BBM SG_ 2147484373 ESCReqESC_CtrlTrimStat_ISig_4 3000;
BA_REL_ "GenSigTimeoutTime" BU_SG_REL_ BBM SG_ 2147484373 ESCReqESC_CtrlTrimStat_ISig_4 270;
BA_REL_ "GenSigFirstTimeoutTime" BU_SG_REL_ IC3 SG_ 2147484373 ESCReqESC_CtrlTrimStat_ISig_4 3000;
BA_REL_ "GenSigTimeoutTime" BU_SG_REL_ IC3 SG_ 2147484373 ESCReqESC_CtrlTrimStat_ISig_4 270;
BA_REL_ "GenSigFirstTimeoutTime" BU_SG_REL_ CIOM SG_ 2147484373 SCLLogicEnable_rqst 3000;
BA_REL_ "GenSigTimeoutTime" BU_SG_REL_ CIOM SG_ 2147484373 SCLLogicEnable_rqst 270;
BA_REL_ "GenSigFirstTimeoutTime" BU_SG_REL_ IC3 SG_ 2147484373 ESCReqESC_CtrlTrimReq_ISig_4 3000;
BA_REL_ "GenSigTimeoutTime" BU_SG_REL_ IC3 SG_ 2147484373 ESCReqESC_CtrlTrimReq_ISig_4 270;
BA_REL_ "GenSigFirstTimeoutTime" BU_SG_REL_ CIOM SG_ 2147484373 ESCReqESC_CtrlTrimReq_ISig_4 3000;
BA_REL_ "GenSigTimeoutTime" BU_SG_REL_ CIOM SG_ 2147484373 ESCReqESC_CtrlTrimReq_ISig_4 270;
BA_REL_ "GenSigFirstTimeoutTime" BU_SG_REL_ BBM SG_ 2147484373 ESCReqESC_CtrlTrimReq_ISig_4 3000;
BA_REL_ "GenSigTimeoutTime" BU_SG_REL_ BBM SG_ 2147484373 ESCReqESC_CtrlTrimReq_ISig_4 270;
BA_REL_ "GenSigFirstTimeoutTime" BU_SG_REL_ BBM SG_ 2147484373 BrakeLight_rqst_ISig_4 3000;
BA_REL_ "GenSigTimeoutTime" BU_SG_REL_ BBM SG_ 2147484373 BrakeLight_rqst_ISig_4 500;
BA_REL_ "GenSigFirstTimeoutTime" BU_SG_REL_ IC3 SG_ 2147484373 ESCReqEMS_CtrlTrimValue_ISig_4 3000;
BA_REL_ "GenSigTimeoutTime" BU_SG_REL_ IC3 SG_ 2147484373 ESCReqEMS_CtrlTrimValue_ISig_4 270;
BA_REL_ "GenSigFirstTimeoutTime" BU_SG_REL_ TECU SG_ 2147484373 ESCReqEMS_CtrlTrimValue_ISig_4 3000;
BA_REL_ "GenSigTimeoutTime" BU_SG_REL_ TECU SG_ 2147484373 ESCReqEMS_CtrlTrimValue_ISig_4 300;
BA_REL_ "GenSigFirstTimeoutTime" BU_SG_REL_ EMS SG_ 2147484373 ESCReqEMS_CtrlTrimValue_ISig_4 3000;
BA_REL_ "GenSigTimeoutTime" BU_SG_REL_ EMS SG_ 2147484373 ESCReqEMS_CtrlTrimValue_ISig_4 270;
BA_REL_ "GenSigFirstTimeoutTime" BU_SG_REL_ IC3 SG_ 2147484373 ESCReqEMS_CtrlTrimReq_ISig_4 3000;
BA_REL_ "GenSigTimeoutTime" BU_SG_REL_ IC3 SG_ 2147484373 ESCReqEMS_CtrlTrimReq_ISig_4 270;
BA_REL_ "GenSigFirstTimeoutTime" BU_SG_REL_ TECU SG_ 2147484373 ESCReqEMS_CtrlTrimReq_ISig_4 3000;
BA_REL_ "GenSigTimeoutTime" BU_SG_REL_ TECU SG_ 2147484373 ESCReqEMS_CtrlTrimReq_ISig_4 300;
BA_REL_ "GenSigFirstTimeoutTime" BU_SG_REL_ EMS SG_ 2147484373 ESCReqEMS_CtrlTrimReq_ISig_4 3000;
BA_REL_ "GenSigTimeoutTime" BU_SG_REL_ EMS SG_ 2147484373 ESCReqEMS_CtrlTrimReq_ISig_4 270;
BA_REL_ "GenSigFirstTimeoutTime" BU_SG_REL_ IC3 SG_ 2147484369 TrailerTest_stat 3000;
BA_REL_ "GenSigTimeoutTime" BU_SG_REL_ IC3 SG_ 2147484369 TrailerTest_stat 270;
BA_REL_ "GenSigFirstTimeoutTime" BU_SG_REL_ CIOM SG_ 2147484369 Washing_HMI_rqst_ISig_4 3000;
BA_REL_ "GenSigTimeoutTime" BU_SG_REL_ CIOM SG_ 2147484369 Washing_HMI_rqst_ISig_4 270;
BA_REL_ "GenSigFirstTimeoutTime" BU_SG_REL_ IC3 SG_ 2147484369 AuxBrakesDwngrdModeInd_rqst 3000;
BA_REL_ "GenSigTimeoutTime" BU_SG_REL_ IC3 SG_ 2147484369 AuxBrakesDwngrdModeInd_rqst 270;
BA_REL_ "GenSigFirstTimeoutTime" BU_SG_REL_ EMS SG_ 2147484369 XRSLTargetSpeedRequest 3000;
BA_REL_ "GenSigTimeoutTime" BU_SG_REL_ EMS SG_ 2147484369 XRSLTargetSpeedRequest 270;
BA_REL_ "GenSigFirstTimeoutTime" BU_SG_REL_ IC3 SG_ 2147484369 DirInd_StalkStatus_1 3000;
BA_REL_ "GenSigTimeoutTime" BU_SG_REL_ IC3 SG_ 2147484369 DirInd_StalkStatus_1 270;
BA_REL_ "GenSigFirstTimeoutTime" BU_SG_REL_ DACU SG_ 2147484369 XPRsystemstate_ISig_4 3000;
BA_REL_ "GenSigTimeoutTime" BU_SG_REL_ DACU SG_ 2147484369 XPRsystemstate_ISig_4 270;
BA_REL_ "GenSigFirstTimeoutTime" BU_SG_REL_ BBM SG_ 2147484369 XPRsystemstate_ISig_4 3000;
BA_REL_ "GenSigTimeoutTime" BU_SG_REL_ BBM SG_ 2147484369 XPRsystemstate_ISig_4 270;
BA_REL_ "GenSigFirstTimeoutTime" BU_SG_REL_ CIOM SG_ 2147484369 KeyAuthentication_rqst 3000;
BA_REL_ "GenSigTimeoutTime" BU_SG_REL_ CIOM SG_ 2147484369 KeyAuthentication_rqst 270;
BA_REL_ "GenSigFirstTimeoutTime" BU_SG_REL_ CIOM SG_ 2147484369 EngineSpeedControlStatus 3000;
BA_REL_ "GenSigTimeoutTime" BU_SG_REL_ CIOM SG_ 2147484369 EngineSpeedControlStatus 270;
BA_REL_ "GenSigFirstTimeoutTime" BU_SG_REL_ IC3 SG_ 2147484369 EngineSpeedControlStatus 3000;
BA_REL_ "GenSigTimeoutTime" BU_SG_REL_ IC3 SG_ 2147484369 EngineSpeedControlStatus 270;
BA_REL_ "GenSigFirstTimeoutTime" BU_SG_REL_ BBM SG_ 2147484369 EngineSpeedControlStatus 3000;
BA_REL_ "GenSigTimeoutTime" BU_SG_REL_ BBM SG_ 2147484369 EngineSpeedControlStatus 270;
BA_REL_ "GenSigFirstTimeoutTime" BU_SG_REL_ EMS SG_ 2147484369 SecondThrottle 3000;
BA_REL_ "GenSigTimeoutTime" BU_SG_REL_ EMS SG_ 2147484369 SecondThrottle 270;
BA_REL_ "GenSigFirstTimeoutTime" BU_SG_REL_ DACU SG_ 2147484369 SecondThrottle 3000;
BA_REL_ "GenSigTimeoutTime" BU_SG_REL_ DACU SG_ 2147484369 SecondThrottle 270;
BA_REL_ "GenSigFirstTimeoutTime" BU_SG_REL_ IC3 SG_ 2147484369 PredeliveryModeIndication_cmd 3000;
BA_REL_ "GenSigTimeoutTime" BU_SG_REL_ IC3 SG_ 2147484369 PredeliveryModeIndication_cmd 270;
BA_REL_ "GenSigFirstTimeoutTime" BU_SG_REL_ CIOM SG_ 2147484369 PredeliveryModeIndication_cmd 3000;
BA_REL_ "GenSigTimeoutTime" BU_SG_REL_ CIOM SG_ 2147484369 PredeliveryModeIndication_cmd 270;
BA_REL_ "GenSigFirstTimeoutTime" BU_SG_REL_ IC3 SG_ 2147484369 LoadCutOffIndication_cmd_ISig_4 3000;
BA_REL_ "GenSigTimeoutTime" BU_SG_REL_ IC3 SG_ 2147484369 LoadCutOffIndication_cmd_ISig_4 270;
BA_REL_ "GenSigFirstTimeoutTime" BU_SG_REL_ CIOM SG_ 2147484369 ExitPreDeliveryModeHMI_rqst_ISig 3000;
BA_REL_ "GenSigTimeoutTime" BU_SG_REL_ CIOM SG_ 2147484369 ExitPreDeliveryModeHMI_rqst_ISig 270;
BA_REL_ "GenSigFirstTimeoutTime" BU_SG_REL_ BBM SG_ 2147484369 FdEquipmentStatus1_ISig_4 3000;
BA_REL_ "GenSigTimeoutTime" BU_SG_REL_ BBM SG_ 2147484369 FdEquipmentStatus1_ISig_4 270;
BA_REL_ "GenSigFirstTimeoutTime" BU_SG_REL_ IC3 SG_ 2147484369 FdEquipmentStatus1_ISig_4 3000;
BA_REL_ "GenSigTimeoutTime" BU_SG_REL_ IC3 SG_ 2147484369 FdEquipmentStatus1_ISig_4 270;
BA_REL_ "GenSigFirstTimeoutTime" BU_SG_REL_ CIOM SG_ 2147484369 FdEquipmentStatus1_ISig_4 3000;
BA_REL_ "GenSigTimeoutTime" BU_SG_REL_ CIOM SG_ 2147484369 FdEquipmentStatus1_ISig_4 270;
BA_REL_ "GenSigFirstTimeoutTime" BU_SG_REL_ IC3 SG_ 2147484182 ParkBrakeAlert_ISig_4 3000;
BA_REL_ "GenSigTimeoutTime" BU_SG_REL_ IC3 SG_ 2147484182 ParkBrakeAlert_ISig_4 150;
BA_REL_ "GenSigFirstTimeoutTime" BU_SG_REL_ IC3 SG_ 2147484182 IntLightMode_CoreRqst_IL_Mode 3000;
BA_REL_ "GenSigTimeoutTime" BU_SG_REL_ IC3 SG_ 2147484182 IntLightMode_CoreRqst_IL_Mode 150;
BA_REL_ "GenSigFirstTimeoutTime" BU_SG_REL_ CIOM SG_ 2147484182 IntLightMode_CoreRqst_IL_Mode 6000;
BA_REL_ "GenSigTimeoutTime" BU_SG_REL_ CIOM SG_ 2147484182 IntLightMode_CoreRqst_IL_Mode 6000;
BA_REL_ "GenSigFirstTimeoutTime" BU_SG_REL_ IC3 SG_ 2147484182 SteeringColumnLockErrInd_rqst 3000;
BA_REL_ "GenSigTimeoutTime" BU_SG_REL_ IC3 SG_ 2147484182 SteeringColumnLockErrInd_rqst 150;
BA_REL_ "GenSigFirstTimeoutTime" BU_SG_REL_ CIOM SG_ 2147484182 ParkingLight_Indication 6000;
BA_REL_ "GenSigTimeoutTime" BU_SG_REL_ CIOM SG_ 2147484182 ParkingLight_Indication 6000;
BA_REL_ "GenSigFirstTimeoutTime" BU_SG_REL_ CIOM SG_ 2147484182 DaytimeRunningLight_Indication 6000;
BA_REL_ "GenSigTimeoutTime" BU_SG_REL_ CIOM SG_ 2147484182 DaytimeRunningLight_Indication 6000;
BA_REL_ "GenSigFirstTimeoutTime" BU_SG_REL_ IC3 SG_ 2147484182 EPBBackupMode_ISig_4 3000;
BA_REL_ "GenSigTimeoutTime" BU_SG_REL_ IC3 SG_ 2147484182 EPBBackupMode_ISig_4 150;
BA_REL_ "GenSigFirstTimeoutTime" BU_SG_REL_ CIOM SG_ 2147484182 WiperModeStatus_ISig_4 3000;
BA_REL_ "GenSigTimeoutTime" BU_SG_REL_ CIOM SG_ 2147484182 WiperModeStatus_ISig_4 500;
BA_REL_ "GenSigFirstTimeoutTime" BU_SG_REL_ DACU SG_ 2147484182 WiperModeStatus_ISig_4 3000;
BA_REL_ "GenSigTimeoutTime" BU_SG_REL_ DACU SG_ 2147484182 WiperModeStatus_ISig_4 500;
BA_REL_ "GenSigFirstTimeoutTime" BU_SG_REL_ IC3 SG_ 2147484182 WiperModeStatus_ISig_4 3000;
BA_REL_ "GenSigTimeoutTime" BU_SG_REL_ IC3 SG_ 2147484182 WiperModeStatus_ISig_4 500;
BA_REL_ "GenSigFirstTimeoutTime" BU_SG_REL_ BBM SG_ 2147484182 WiperModeStatus_ISig_4 3000;
BA_REL_ "GenSigTimeoutTime" BU_SG_REL_ BBM SG_ 2147484182 WiperModeStatus_ISig_4 500;
BA_REL_ "GenSigFirstTimeoutTime" BU_SG_REL_ CIOM SG_ 2147484182 FrontFog_Indication 6000;
BA_REL_ "GenSigTimeoutTime" BU_SG_REL_ CIOM SG_ 2147484182 FrontFog_Indication 6000;
BA_REL_ "GenSigFirstTimeoutTime" BU_SG_REL_ IC3 SG_ 2147484182 PBReleaseAcceptance_stat_ISig_4 3000;
BA_REL_ "GenSigTimeoutTime" BU_SG_REL_ IC3 SG_ 2147484182 PBReleaseAcceptance_stat_ISig_4 150;
BA_REL_ "GenSigFirstTimeoutTime" BU_SG_REL_ CIOM SG_ 2147484182 DrivingLightPlus_Indication 6000;
BA_REL_ "GenSigTimeoutTime" BU_SG_REL_ CIOM SG_ 2147484182 DrivingLightPlus_Indication 6000;
BA_REL_ "GenSigFirstTimeoutTime" BU_SG_REL_ CIOM SG_ 2147484182 IntLightMode_CoreRqst_EventFlag 6000;
BA_REL_ "GenSigTimeoutTime" BU_SG_REL_ CIOM SG_ 2147484182 IntLightMode_CoreRqst_EventFlag 6000;
BA_REL_ "GenSigFirstTimeoutTime" BU_SG_REL_ IC3 SG_ 2147484182 IntLightMode_CoreRqst_EventFlag 3000;
BA_REL_ "GenSigTimeoutTime" BU_SG_REL_ IC3 SG_ 2147484182 IntLightMode_CoreRqst_EventFlag 150;
BA_REL_ "GenSigFirstTimeoutTime" BU_SG_REL_ EMS SG_ 2147484182 ParkingBrake_stat_ISig_4 3000;
BA_REL_ "GenSigTimeoutTime" BU_SG_REL_ EMS SG_ 2147484182 ParkingBrake_stat_ISig_4 500;
BA_REL_ "GenSigFirstTimeoutTime" BU_SG_REL_ IC3 SG_ 2147484182 ParkingBrake_stat_ISig_4 3000;
BA_REL_ "GenSigTimeoutTime" BU_SG_REL_ IC3 SG_ 2147484182 ParkingBrake_stat_ISig_4 500;
BA_REL_ "GenSigFirstTimeoutTime" BU_SG_REL_ CIOM SG_ 2147484182 ParkingBrake_stat_ISig_4 3000;
BA_REL_ "GenSigTimeoutTime" BU_SG_REL_ CIOM SG_ 2147484182 ParkingBrake_stat_ISig_4 500;
BA_REL_ "GenSigFirstTimeoutTime" BU_SG_REL_ BBM SG_ 2147484182 ParkingBrake_stat_ISig_4 3000;
BA_REL_ "GenSigTimeoutTime" BU_SG_REL_ BBM SG_ 2147484182 ParkingBrake_stat_ISig_4 500;
BA_REL_ "GenSigFirstTimeoutTime" BU_SG_REL_ TECU SG_ 2147484182 ParkingBrake_stat_ISig_4 3000;
BA_REL_ "GenSigTimeoutTime" BU_SG_REL_ TECU SG_ 2147484182 ParkingBrake_stat_ISig_4 500;
BA_REL_ "GenSigFirstTimeoutTime" BU_SG_REL_ CIOM SG_ 2147484182 DrivingLight_Indication 6000;
BA_REL_ "GenSigTimeoutTime" BU_SG_REL_ CIOM SG_ 2147484182 DrivingLight_Indication 6000;
BA_REL_ "GenSigFirstTimeoutTime" BU_SG_REL_ CIOM SG_ 2147484182 MirrorHeatingMode_ISig_4 6000;
BA_REL_ "GenSigTimeoutTime" BU_SG_REL_ CIOM SG_ 2147484182 MirrorHeatingMode_ISig_4 6000;
BA_REL_ "GenSigFirstTimeoutTime" BU_SG_REL_ CIOM SG_ 2147484182 RearFog_Indication 6000;
BA_REL_ "GenSigTimeoutTime" BU_SG_REL_ CIOM SG_ 2147484182 RearFog_Indication 6000;
BA_REL_ "GenSigFirstTimeoutTime" BU_SG_REL_ CIOM SG_ 2147484182 InteriorLightLevelInd_cmd 6000;
BA_REL_ "GenSigTimeoutTime" BU_SG_REL_ CIOM SG_ 2147484182 InteriorLightLevelInd_cmd 6000;
BA_REL_ "GenSigFirstTimeoutTime" BU_SG_REL_ IC3 SG_ 2147484180 LiftAxle2LiftFuncSelected_ISig_4 3000;
BA_REL_ "GenSigTimeoutTime" BU_SG_REL_ IC3 SG_ 2147484180 LiftAxle2LiftFuncSelected_ISig_4 150;
BA_REL_ "GenSigFirstTimeoutTime" BU_SG_REL_ CIOM SG_ 2147484180 StopLevelChangeAck_ISig_4 3000;
BA_REL_ "GenSigTimeoutTime" BU_SG_REL_ CIOM SG_ 2147484180 StopLevelChangeAck_ISig_4 150;
BA_REL_ "GenSigFirstTimeoutTime" BU_SG_REL_ CIOM SG_ 2147484180 HeightAdjustmentAllowed_ISig_4 3000;
BA_REL_ "GenSigTimeoutTime" BU_SG_REL_ CIOM SG_ 2147484180 HeightAdjustmentAllowed_ISig_4 150;
BA_REL_ "GenSigFirstTimeoutTime" BU_SG_REL_ IC3 SG_ 2147484180 LiftAxle2LowerACK_ISig_4 3000;
BA_REL_ "GenSigTimeoutTime" BU_SG_REL_ IC3 SG_ 2147484180 LiftAxle2LowerACK_ISig_4 150;
BA_REL_ "GenSigFirstTimeoutTime" BU_SG_REL_ CIOM SG_ 2147484180 LiftAxle2UpRequestACK_ISig_4 3000;
BA_REL_ "GenSigTimeoutTime" BU_SG_REL_ CIOM SG_ 2147484180 LiftAxle2UpRequestACK_ISig_4 150;
BA_REL_ "GenSigFirstTimeoutTime" BU_SG_REL_ IC3 SG_ 2147484180 LiftAxle2UpRequestACK_ISig_4 3000;
BA_REL_ "GenSigTimeoutTime" BU_SG_REL_ IC3 SG_ 2147484180 LiftAxle2UpRequestACK_ISig_4 150;
BA_REL_ "GenSigFirstTimeoutTime" BU_SG_REL_ CIOM SG_ 2147484180 RideHeightStatus_ISig_4 3000;
BA_REL_ "GenSigTimeoutTime" BU_SG_REL_ CIOM SG_ 2147484180 RideHeightStatus_ISig_4 150;
BA_REL_ "GenSigFirstTimeoutTime" BU_SG_REL_ BBM SG_ 2147484180 RideHeightStatus_ISig_4 3000;
BA_REL_ "GenSigTimeoutTime" BU_SG_REL_ BBM SG_ 2147484180 RideHeightStatus_ISig_4 150;
BA_REL_ "GenSigFirstTimeoutTime" BU_SG_REL_ IC3 SG_ 2147484180 RideHeightOutsideTargetRange_ISi 3000;
BA_REL_ "GenSigTimeoutTime" BU_SG_REL_ IC3 SG_ 2147484180 RideHeightOutsideTargetRange_ISi 150;
BA_REL_ "GenSigFirstTimeoutTime" BU_SG_REL_ CIOM SG_ 2147484180 RideHeightOutsideTargetRange_ISi 3000;
BA_REL_ "GenSigTimeoutTime" BU_SG_REL_ CIOM SG_ 2147484180 RideHeightOutsideTargetRange_ISi 150;
BA_REL_ "GenSigFirstTimeoutTime" BU_SG_REL_ CIOM SG_ 2147484180 LoadDistributionFuncSelected_ISi 3000;
BA_REL_ "GenSigTimeoutTime" BU_SG_REL_ CIOM SG_ 2147484180 LoadDistributionFuncSelected_ISi 150;
BA_REL_ "GenSigFirstTimeoutTime" BU_SG_REL_ CIOM SG_ 2147484180 RideHeightStorageAck_ISig_4 3000;
BA_REL_ "GenSigTimeoutTime" BU_SG_REL_ CIOM SG_ 2147484180 RideHeightStorageAck_ISig_4 150;
BA_REL_ "GenSigFirstTimeoutTime" BU_SG_REL_ IC3 SG_ 2147484180 LiftAxle2AutoLiftSelected_ISig_4 3000;
BA_REL_ "GenSigTimeoutTime" BU_SG_REL_ IC3 SG_ 2147484180 LiftAxle2AutoLiftSelected_ISig_4 150;
BA_REL_ "GenSigFirstTimeoutTime" BU_SG_REL_ IC3 SG_ 2147484180 LiftAxle1UpRequestACK_ISig_4 3000;
BA_REL_ "GenSigTimeoutTime" BU_SG_REL_ IC3 SG_ 2147484180 LiftAxle1UpRequestACK_ISig_4 150;
BA_REL_ "GenSigFirstTimeoutTime" BU_SG_REL_ CIOM SG_ 2147484180 LiftAxle1UpRequestACK_ISig_4 3000;
BA_REL_ "GenSigTimeoutTime" BU_SG_REL_ CIOM SG_ 2147484180 LiftAxle1UpRequestACK_ISig_4 150;
BA_REL_ "GenSigFirstTimeoutTime" BU_SG_REL_ BBM SG_ 2147484180 LiftAxle1PositionStatus_ISig_4 3000;
BA_REL_ "GenSigTimeoutTime" BU_SG_REL_ BBM SG_ 2147484180 LiftAxle1PositionStatus_ISig_4 150;
BA_REL_ "GenSigFirstTimeoutTime" BU_SG_REL_ CIOM SG_ 2147484180 LiftAxle1PositionStatus_ISig_4 3000;
BA_REL_ "GenSigTimeoutTime" BU_SG_REL_ CIOM SG_ 2147484180 LiftAxle1PositionStatus_ISig_4 150;
BA_REL_ "GenSigFirstTimeoutTime" BU_SG_REL_ DACU SG_ 2147484180 LiftAxle1PositionStatus_ISig_4 3000;
BA_REL_ "GenSigTimeoutTime" BU_SG_REL_ DACU SG_ 2147484180 LiftAxle1PositionStatus_ISig_4 600;
BA_REL_ "GenSigFirstTimeoutTime" BU_SG_REL_ IC3 SG_ 2147484180 LiftAxle1PositionStatus_ISig_4 3000;
BA_REL_ "GenSigTimeoutTime" BU_SG_REL_ IC3 SG_ 2147484180 LiftAxle1PositionStatus_ISig_4 150;
BA_REL_ "GenSigFirstTimeoutTime" BU_SG_REL_ IC3 SG_ 2147484180 LiftAxle1LowerACK_ISig_4 3000;
BA_REL_ "GenSigTimeoutTime" BU_SG_REL_ IC3 SG_ 2147484180 LiftAxle1LowerACK_ISig_4 150;
BA_REL_ "GenSigFirstTimeoutTime" BU_SG_REL_ IC3 SG_ 2147484180 LiftAxle1AutoLiftSelected_ISig_4 3000;
BA_REL_ "GenSigTimeoutTime" BU_SG_REL_ IC3 SG_ 2147484180 LiftAxle1AutoLiftSelected_ISig_4 150;
BA_REL_ "GenSigFirstTimeoutTime" BU_SG_REL_ IC3 SG_ 2147484180 LiftAxle2PositionStatus_ISig_4 3000;
BA_REL_ "GenSigTimeoutTime" BU_SG_REL_ IC3 SG_ 2147484180 LiftAxle2PositionStatus_ISig_4 150;
BA_REL_ "GenSigFirstTimeoutTime" BU_SG_REL_ BBM SG_ 2147484180 LiftAxle2PositionStatus_ISig_4 3000;
BA_REL_ "GenSigTimeoutTime" BU_SG_REL_ BBM SG_ 2147484180 LiftAxle2PositionStatus_ISig_4 150;
BA_REL_ "GenSigFirstTimeoutTime" BU_SG_REL_ CIOM SG_ 2147484180 LiftAxle2PositionStatus_ISig_4 3000;
BA_REL_ "GenSigTimeoutTime" BU_SG_REL_ CIOM SG_ 2147484180 LiftAxle2PositionStatus_ISig_4 150;
BA_REL_ "GenSigFirstTimeoutTime" BU_SG_REL_ TECU SG_ 2147484180 LevelControlInformation_ISig_4 3000;
BA_REL_ "GenSigTimeoutTime" BU_SG_REL_ TECU SG_ 2147484180 LevelControlInformation_ISig_4 500;
BA_REL_ "GenSigFirstTimeoutTime" BU_SG_REL_ IC3 SG_ 2147484180 LevelControlInformation_ISig_4 3000;
BA_REL_ "GenSigTimeoutTime" BU_SG_REL_ IC3 SG_ 2147484180 LevelControlInformation_ISig_4 500;
BA_REL_ "GenSigFirstTimeoutTime" BU_SG_REL_ CIOM SG_ 2147484180 LevelControlInformation_ISig_4 3000;
BA_REL_ "GenSigTimeoutTime" BU_SG_REL_ CIOM SG_ 2147484180 LevelControlInformation_ISig_4 500;
BA_REL_ "GenSigFirstTimeoutTime" BU_SG_REL_ IC3 SG_ 2147484180 LiftAxle1LiftFuncSelected_ISig_4 3000;
BA_REL_ "GenSigTimeoutTime" BU_SG_REL_ IC3 SG_ 2147484180 LiftAxle1LiftFuncSelected_ISig_4 150;
BA_REL_ "GenSigFirstTimeoutTime" BU_SG_REL_ CIOM SG_ 2147484180 LoadDistributionChangeACK_ISig_4 3000;
BA_REL_ "GenSigTimeoutTime" BU_SG_REL_ CIOM SG_ 2147484180 LoadDistributionChangeACK_ISig_4 150;
BA_REL_ "GenSigFirstTimeoutTime" BU_SG_REL_ IC3 SG_ 2147484180 LoadDistributionChangeACK_ISig_4 3000;
BA_REL_ "GenSigTimeoutTime" BU_SG_REL_ IC3 SG_ 2147484180 LoadDistributionChangeACK_ISig_4 150;
BA_REL_ "GenSigFirstTimeoutTime" BU_SG_REL_ CIOM SG_ 2147484180 RampLevelStorageAck_ISig_4 3000;
BA_REL_ "GenSigTimeoutTime" BU_SG_REL_ CIOM SG_ 2147484180 RampLevelStorageAck_ISig_4 150;
BA_REL_ "GenSigFirstTimeoutTime" BU_SG_REL_ IC3 SG_ 2147484180 LoadDistributionSelected_ISig_4 3000;
BA_REL_ "GenSigTimeoutTime" BU_SG_REL_ IC3 SG_ 2147484180 LoadDistributionSelected_ISig_4 150;
BA_REL_ "GenSigFirstTimeoutTime" BU_SG_REL_ BBM SG_ 2147484180 LoadDistributionSelected_ISig_4 3000;
BA_REL_ "GenSigTimeoutTime" BU_SG_REL_ BBM SG_ 2147484180 LoadDistributionSelected_ISig_4 150;
BA_REL_ "GenSigFirstTimeoutTime" BU_SG_REL_ CIOM SG_ 2147484180 LoadDistributionSelected_ISig_4 3000;
BA_REL_ "GenSigTimeoutTime" BU_SG_REL_ CIOM SG_ 2147484180 LoadDistributionSelected_ISig_4 150;
BA_REL_ "GenSigFirstTimeoutTime" BU_SG_REL_ CIOM SG_ 2147484180 RideHeightFunctionStatus_ISig_4 3000;
BA_REL_ "GenSigTimeoutTime" BU_SG_REL_ CIOM SG_ 2147484180 RideHeightFunctionStatus_ISig_4 150;
BA_REL_ "GenSigFirstTimeoutTime" BU_SG_REL_ IC3 SG_ 2147484168 TransmLowRangeSenseSwitch_ISig_4 3000;
BA_REL_ "GenSigTimeoutTime" BU_SG_REL_ IC3 SG_ 2147484168 TransmLowRangeSenseSwitch_ISig_4 120;
BA_REL_ "GenSigFirstTimeoutTime" BU_SG_REL_ EMS SG_ 2147484168 TransmLowRangeSenseSwitch_ISig_4 3000;
BA_REL_ "GenSigTimeoutTime" BU_SG_REL_ EMS SG_ 2147484168 TransmLowRangeSenseSwitch_ISig_4 120;
BA_REL_ "GenSigFirstTimeoutTime" BU_SG_REL_ TECU SG_ 2147484168 TransmSystemPowerDown_rqst 3000;
BA_REL_ "GenSigTimeoutTime" BU_SG_REL_ TECU SG_ 2147484168 TransmSystemPowerDown_rqst 500;
BA_REL_ "GenSigFirstTimeoutTime" BU_SG_REL_ BBM SG_ 2147484168 TransmissionNeutralSwitch_ISig_4 3000;
BA_REL_ "GenSigTimeoutTime" BU_SG_REL_ BBM SG_ 2147484168 TransmissionNeutralSwitch_ISig_4 500;
BA_REL_ "GenSigFirstTimeoutTime" BU_SG_REL_ EMS SG_ 2147484168 TransmissionNeutralSwitch_ISig_4 3000;
BA_REL_ "GenSigTimeoutTime" BU_SG_REL_ EMS SG_ 2147484168 TransmissionNeutralSwitch_ISig_4 500;
BA_REL_ "GenSigFirstTimeoutTime" BU_SG_REL_ EMS SG_ 2147484168 SecuredNeutralPosition_ISig_4 3000;
BA_REL_ "GenSigTimeoutTime" BU_SG_REL_ EMS SG_ 2147484168 SecuredNeutralPosition_ISig_4 500;
BA_REL_ "GenSigFirstTimeoutTime" BU_SG_REL_ IC3 SG_ 2147484168 SecuredNeutralPosition_ISig_4 3000;
BA_REL_ "GenSigTimeoutTime" BU_SG_REL_ IC3 SG_ 2147484168 SecuredNeutralPosition_ISig_4 500;
BA_REL_ "GenSigFirstTimeoutTime" BU_SG_REL_ BBM SG_ 2147484168 SecuredNeutralPosition_ISig_4 6000;
BA_REL_ "GenSigTimeoutTime" BU_SG_REL_ BBM SG_ 2147484168 SecuredNeutralPosition_ISig_4 500;
BA_REL_ "GenSigFirstTimeoutTime" BU_SG_REL_ EMS SG_ 2147484168 EngineStopRequest_ISig_4 3000;
BA_REL_ "GenSigTimeoutTime" BU_SG_REL_ EMS SG_ 2147484168 EngineStopRequest_ISig_4 120;
BA_REL_ "GenSigFirstTimeoutTime" BU_SG_REL_ DACU SG_ 2147484168 ReverseGearEngaged_ISig_4 3000;
BA_REL_ "GenSigTimeoutTime" BU_SG_REL_ DACU SG_ 2147484168 ReverseGearEngaged_ISig_4 500;
BA_REL_ "GenSigFirstTimeoutTime" BU_SG_REL_ EMS SG_ 2147484168 ReverseGearEngaged_ISig_4 3000;
BA_REL_ "GenSigTimeoutTime" BU_SG_REL_ EMS SG_ 2147484168 ReverseGearEngaged_ISig_4 500;
BA_REL_ "GenSigFirstTimeoutTime" BU_SG_REL_ CIOM SG_ 2147484168 ReverseGearEngaged_ISig_4 3000;
BA_REL_ "GenSigTimeoutTime" BU_SG_REL_ CIOM SG_ 2147484168 ReverseGearEngaged_ISig_4 500;
BA_REL_ "GenSigFirstTimeoutTime" BU_SG_REL_ BBM SG_ 2147484168 ReverseGearEngaged_ISig_4 3000;
BA_REL_ "GenSigTimeoutTime" BU_SG_REL_ BBM SG_ 2147484168 ReverseGearEngaged_ISig_4 500;
BA_REL_ "GenSigFirstTimeoutTime" BU_SG_REL_ IC3 SG_ 2147484168 ReverseGearEngaged_ISig_4 3000;
BA_REL_ "GenSigTimeoutTime" BU_SG_REL_ IC3 SG_ 2147484168 ReverseGearEngaged_ISig_4 500;
BA_REL_ "GenSigFirstTimeoutTime" BU_SG_REL_ EMS SG_ 2147484168 EngineCrankRequest 3000;
BA_REL_ "GenSigTimeoutTime" BU_SG_REL_ EMS SG_ 2147484168 EngineCrankRequest 120;
BA_REL_ "GenSigFirstTimeoutTime" BU_SG_REL_ TECU SG_ 2147484168 ParkBrakeActuationStatus 3000;
BA_REL_ "GenSigTimeoutTime" BU_SG_REL_ TECU SG_ 2147484168 ParkBrakeActuationStatus 500;
BA_REL_ "GenSigFirstTimeoutTime" BU_SG_REL_ DACU SG_ 2147484168 ParkBrakeActuationStatus 3000;
BA_REL_ "GenSigTimeoutTime" BU_SG_REL_ DACU SG_ 2147484168 ParkBrakeActuationStatus 120;
BA_REL_ "GenSigFirstTimeoutTime" BU_SG_REL_ BBM SG_ 2147484168 ParkBrakeActuationStatus 3000;
BA_REL_ "GenSigTimeoutTime" BU_SG_REL_ BBM SG_ 2147484168 ParkBrakeActuationStatus 500;
BA_REL_ "GenSigFirstTimeoutTime" BU_SG_REL_ IC3 SG_ 2147484168 ParkBrakeActuationStatus 3000;
BA_REL_ "GenSigTimeoutTime" BU_SG_REL_ IC3 SG_ 2147484168 ParkBrakeActuationStatus 500;
BA_REL_ "GenSigFirstTimeoutTime" BU_SG_REL_ EMS SG_ 2147484168 EnginePreheat_rqst 3000;
BA_REL_ "GenSigTimeoutTime" BU_SG_REL_ EMS SG_ 2147484168 EnginePreheat_rqst 120;
BA_REL_ "GenSigFirstTimeoutTime" BU_SG_REL_ EMS SG_ 2147484168 AcceleratorPedalPositionBackup 3000;
BA_REL_ "GenSigTimeoutTime" BU_SG_REL_ EMS SG_ 2147484168 AcceleratorPedalPositionBackup 120;
BA_REL_ "GenSigFirstTimeoutTime" BU_SG_REL_ TECU SG_ 2147484168 AcceleratorPedalPositionBackup 3000;
BA_REL_ "GenSigTimeoutTime" BU_SG_REL_ TECU SG_ 2147484168 AcceleratorPedalPositionBackup 120;
BA_REL_ "GenSigFirstTimeoutTime" BU_SG_REL_ CIOM SG_ 2147484168 KeyPosition_ISig_4 3000;
BA_REL_ "GenSigTimeoutTime" BU_SG_REL_ CIOM SG_ 2147484168 KeyPosition_ISig_4 120;
BA_REL_ "GenSigFirstTimeoutTime" BU_SG_REL_ IC3 SG_ 2147484168 KeyPosition_ISig_4 3000;
BA_REL_ "GenSigTimeoutTime" BU_SG_REL_ IC3 SG_ 2147484168 KeyPosition_ISig_4 120;
BA_REL_ "GenSigFirstTimeoutTime" BU_SG_REL_ IC3 SG_ 2147484168 GearSplit_Status_ISig_4 3000;
BA_REL_ "GenSigTimeoutTime" BU_SG_REL_ IC3 SG_ 2147484168 GearSplit_Status_ISig_4 500;
BA_REL_ "GenSigFirstTimeoutTime" BU_SG_REL_ BBM SG_ 2147484168 GearSplit_Status_ISig_4 3000;
BA_REL_ "GenSigTimeoutTime" BU_SG_REL_ BBM SG_ 2147484168 GearSplit_Status_ISig_4 500;
BA_REL_ "GenSigFirstTimeoutTime" BU_SG_REL_ CIOM SG_ 2147484168 FerryFunctionSwitchChangeACK_ISi 3000;
BA_REL_ "GenSigTimeoutTime" BU_SG_REL_ CIOM SG_ 2147484168 FerryFunctionSwitchChangeACK_ISi 120;
BA_REL_ "GenSigFirstTimeoutTime" BU_SG_REL_ IC3 SG_ 2147484168 DirectionIndication_cmd 3000;
BA_REL_ "GenSigTimeoutTime" BU_SG_REL_ IC3 SG_ 2147484168 DirectionIndication_cmd 120;
BA_REL_ "GenSigFirstTimeoutTime" BU_SG_REL_ IC3 SG_ 2147484168 IdleShutdownWarning 3000;
BA_REL_ "GenSigTimeoutTime" BU_SG_REL_ IC3 SG_ 2147484168 IdleShutdownWarning 120;
BA_REL_ "GenSigFirstTimeoutTime" BU_SG_REL_ CIOM SG_ 2147484168 BackToDriveReqACK_ISig_4 3000;
BA_REL_ "GenSigTimeoutTime" BU_SG_REL_ CIOM SG_ 2147484168 BackToDriveReqACK_ISig_4 120;
BA_REL_ "GenSigFirstTimeoutTime" BU_SG_REL_ EMS SG_ 2147484168 EngineSystemPowerDownRequest_ISi 3000;
BA_REL_ "GenSigTimeoutTime" BU_SG_REL_ EMS SG_ 2147484168 EngineSystemPowerDownRequest_ISi 120;
BA_REL_ "GenSigFirstTimeoutTime" BU_SG_REL_ IC3 SG_ 2147484168 EngineSystemPowerDownRequest_ISi 3000;
BA_REL_ "GenSigTimeoutTime" BU_SG_REL_ IC3 SG_ 2147484168 EngineSystemPowerDownRequest_ISi 120;
BA_REL_ "GenSigFirstTimeoutTime" BU_SG_REL_ IC3 SG_ 2147484897 OilLevelDrvInstr_IncorrEngSpe 12000;
BA_REL_ "GenSigTimeoutTime" BU_SG_REL_ IC3 SG_ 2147484897 OilLevelDrvInstr_IncorrEngSpe 3000;
BA_REL_ "GenSigFirstTimeoutTime" BU_SG_REL_ IC3 SG_ 2147484897 OilLevelDrvInstr_StopVehicle 12000;
BA_REL_ "GenSigTimeoutTime" BU_SG_REL_ IC3 SG_ 2147484897 OilLevelDrvInstr_StopVehicle 3000;
BA_REL_ "GenSigFirstTimeoutTime" BU_SG_REL_ VMCU SG_ 2147484897 SchwungStatus 12000;
BA_REL_ "GenSigTimeoutTime" BU_SG_REL_ VMCU SG_ 2147484897 SchwungStatus 3000;
BA_REL_ "GenSigFirstTimeoutTime" BU_SG_REL_ IC3 SG_ 2147484897 HillDataCtrlTECU_State_ISig_4 12000;
BA_REL_ "GenSigTimeoutTime" BU_SG_REL_ IC3 SG_ 2147484897 HillDataCtrlTECU_State_ISig_4 3000;
BA_REL_ "GenSigFirstTimeoutTime" BU_SG_REL_ IC3 SG_ 2147484897 OilLevelDrvInstr_Wait60SecTxt 12000;
BA_REL_ "GenSigTimeoutTime" BU_SG_REL_ IC3 SG_ 2147484897 OilLevelDrvInstr_Wait60SecTxt 3000;
BA_REL_ "GenSigFirstTimeoutTime" BU_SG_REL_ IC3 SG_ 2147484897 ClutchAbuseStatus 12000;
BA_REL_ "GenSigTimeoutTime" BU_SG_REL_ IC3 SG_ 2147484897 ClutchAbuseStatus 3000;
BA_REL_ "GenSigFirstTimeoutTime" BU_SG_REL_ IC3 SG_ 2147484897 TransmissionSplitboxPTOMode 12000;
BA_REL_ "GenSigTimeoutTime" BU_SG_REL_ IC3 SG_ 2147484897 TransmissionSplitboxPTOMode 3000;
BA_REL_ "GenSigFirstTimeoutTime" BU_SG_REL_ IC3 SG_ 2147484897 ClutchCalibration_stat 12000;
BA_REL_ "GenSigTimeoutTime" BU_SG_REL_ IC3 SG_ 2147484897 ClutchCalibration_stat 3000;
BA_REL_ "GenSigFirstTimeoutTime" BU_SG_REL_ IC3 SG_ 2147484897 OilLevelDrvInstr_ChangeGearTxt 12000;
BA_REL_ "GenSigTimeoutTime" BU_SG_REL_ IC3 SG_ 2147484897 OilLevelDrvInstr_ChangeGearTxt 3000;
BA_REL_ "GenSigFirstTimeoutTime" BU_SG_REL_ IC3 SG_ 2147484897 OilLevelDrvInstr_NotHorizonTxt 12000;
BA_REL_ "GenSigTimeoutTime" BU_SG_REL_ IC3 SG_ 2147484897 OilLevelDrvInstr_NotHorizonTxt 3000;
BA_REL_ "GenSigFirstTimeoutTime" BU_SG_REL_ IC3 SG_ 2147484897 ISeeStatus 12000;
BA_REL_ "GenSigTimeoutTime" BU_SG_REL_ IC3 SG_ 2147484897 ISeeStatus 3000;
BA_REL_ "GenSigFirstTimeoutTime" BU_SG_REL_ IC3 SG_ 2147484897 EcoRollEnabledStatus 12000;
BA_REL_ "GenSigTimeoutTime" BU_SG_REL_ IC3 SG_ 2147484897 EcoRollEnabledStatus 3000;
BA_REL_ "GenSigFirstTimeoutTime" BU_SG_REL_ IC3 SG_ 2147484897 OilLevelDrvInstr_OilTempTxt 12000;
BA_REL_ "GenSigTimeoutTime" BU_SG_REL_ IC3 SG_ 2147484897 OilLevelDrvInstr_OilTempTxt 3000;
BA_REL_ "GenSigFirstTimeoutTime" BU_SG_REL_ IC3 SG_ 2147484897 HillDataCtrlTECU_AckCnt_ISig_4 12000;
BA_REL_ "GenSigTimeoutTime" BU_SG_REL_ IC3 SG_ 2147484897 HillDataCtrlTECU_AckCnt_ISig_4 3000;
BA_REL_ "GenSigFirstTimeoutTime" BU_SG_REL_ IC3 SG_ 2147484689 GearShiftingRec_Steps 3000;
BA_REL_ "GenSigTimeoutTime" BU_SG_REL_ IC3 SG_ 2147484689 GearShiftingRec_Steps 600;
BA_REL_ "GenSigFirstTimeoutTime" BU_SG_REL_ IC3 SG_ 2147484689 GearShiftingRec_Direction 3000;
BA_REL_ "GenSigTimeoutTime" BU_SG_REL_ IC3 SG_ 2147484689 GearShiftingRec_Direction 600;
BA_REL_ "GenSigFirstTimeoutTime" BU_SG_REL_ IC3 SG_ 2147484689 BrakeInterlockStatus 3000;
BA_REL_ "GenSigTimeoutTime" BU_SG_REL_ IC3 SG_ 2147484689 BrakeInterlockStatus 600;
BA_REL_ "GenSigFirstTimeoutTime" BU_SG_REL_ VMCU SG_ 2147484689 BrakeInterlockStatus 3000;
BA_REL_ "GenSigTimeoutTime" BU_SG_REL_ VMCU SG_ 2147484689 BrakeInterlockStatus 600;
BA_REL_ "GenSigFirstTimeoutTime" BU_SG_REL_ IC3 SG_ 2147484689 AutGearSplitPosition 3000;
BA_REL_ "GenSigTimeoutTime" BU_SG_REL_ IC3 SG_ 2147484689 AutGearSplitPosition 600;
BA_REL_ "GenSigFirstTimeoutTime" BU_SG_REL_ IC3 SG_ 2147484689 TransmissionBrakeMode 3000;
BA_REL_ "GenSigTimeoutTime" BU_SG_REL_ IC3 SG_ 2147484689 TransmissionBrakeMode 600;
BA_REL_ "GenSigFirstTimeoutTime" BU_SG_REL_ IC3 SG_ 2147484689 AvailableGearsWithLowerRatio 3000;
BA_REL_ "GenSigTimeoutTime" BU_SG_REL_ IC3 SG_ 2147484689 AvailableGearsWithLowerRatio 600;
BA_REL_ "GenSigFirstTimeoutTime" BU_SG_REL_ VMCU SG_ 2147484689 FuelEcoDrvStatus 3000;
BA_REL_ "GenSigTimeoutTime" BU_SG_REL_ VMCU SG_ 2147484689 FuelEcoDrvStatus 600;
BA_REL_ "GenSigFirstTimeoutTime" BU_SG_REL_ IC3 SG_ 2147484689 EcoCruiseStatus_ISig_4 3000;
BA_REL_ "GenSigTimeoutTime" BU_SG_REL_ IC3 SG_ 2147484689 EcoCruiseStatus_ISig_4 600;
BA_REL_ "GenSigFirstTimeoutTime" BU_SG_REL_ EMS SG_ 2147484689 EcoCruiseStatus_ISig_4 3000;
BA_REL_ "GenSigTimeoutTime" BU_SG_REL_ EMS SG_ 2147484689 EcoCruiseStatus_ISig_4 600;
BA_REL_ "GenSigFirstTimeoutTime" BU_SG_REL_ IC3 SG_ 2147484689 TransmissionDrivingMode 3000;
BA_REL_ "GenSigTimeoutTime" BU_SG_REL_ IC3 SG_ 2147484689 TransmissionDrivingMode 600;
BA_REL_ "GenSigFirstTimeoutTime" BU_SG_REL_ VMCU SG_ 2147484689 ClutchWearStatus 3000;
BA_REL_ "GenSigTimeoutTime" BU_SG_REL_ VMCU SG_ 2147484689 ClutchWearStatus 600;
BA_REL_ "GenSigFirstTimeoutTime" BU_SG_REL_ EMS SG_ 2147484689 AutoWheelBrakeInhibited 3000;
BA_REL_ "GenSigTimeoutTime" BU_SG_REL_ EMS SG_ 2147484689 AutoWheelBrakeInhibited 600;
BA_REL_ "GenSigFirstTimeoutTime" BU_SG_REL_ VMCU SG_ 2147484689 DrivingMode_ISig_4 3000;
BA_REL_ "GenSigTimeoutTime" BU_SG_REL_ VMCU SG_ 2147484689 DrivingMode_ISig_4 600;
BA_REL_ "GenSigFirstTimeoutTime" BU_SG_REL_ IC3 SG_ 2147484689 DrivingMode_ISig_4 3000;
BA_REL_ "GenSigTimeoutTime" BU_SG_REL_ IC3 SG_ 2147484689 DrivingMode_ISig_4 600;
BA_REL_ "GenSigFirstTimeoutTime" BU_SG_REL_ IC3 SG_ 2147484689 AutoWheelBrakesDownshiftSugges 3000;
BA_REL_ "GenSigTimeoutTime" BU_SG_REL_ IC3 SG_ 2147484689 AutoWheelBrakesDownshiftSugges 600;
BA_REL_ "GenSigFirstTimeoutTime" BU_SG_REL_ BBM SG_ 2147484689 TransmissionOilTempHigh_ISig_4 3000;
BA_REL_ "GenSigTimeoutTime" BU_SG_REL_ BBM SG_ 2147484689 TransmissionOilTempHigh_ISig_4 600;
BA_REL_ "GenSigFirstTimeoutTime" BU_SG_REL_ IC3 SG_ 2147484689 TransmissionOilTempHigh_ISig_4 3000;
BA_REL_ "GenSigTimeoutTime" BU_SG_REL_ IC3 SG_ 2147484689 TransmissionOilTempHigh_ISig_4 600;
BA_REL_ "GenSigFirstTimeoutTime" BU_SG_REL_ VMCU SG_ 2147484689 AvailableGearsWithHigherRatio 3000;
BA_REL_ "GenSigTimeoutTime" BU_SG_REL_ VMCU SG_ 2147484689 AvailableGearsWithHigherRatio 600;
BA_REL_ "GenSigFirstTimeoutTime" BU_SG_REL_ IC3 SG_ 2147484689 AvailableGearsWithHigherRatio 3000;
BA_REL_ "GenSigTimeoutTime" BU_SG_REL_ IC3 SG_ 2147484689 AvailableGearsWithHigherRatio 600;
BA_REL_ "GenSigFirstTimeoutTime" BU_SG_REL_ BBM SG_ 2147484164 Pto1Consent_ISig_4 3000;
BA_REL_ "GenSigTimeoutTime" BU_SG_REL_ BBM SG_ 2147484164 Pto1Consent_ISig_4 150;
BA_REL_ "GenSigFirstTimeoutTime" BU_SG_REL_ VMCU SG_ 2147484164 Pto1Consent_ISig_4 3000;
BA_REL_ "GenSigTimeoutTime" BU_SG_REL_ VMCU SG_ 2147484164 Pto1Consent_ISig_4 150;
BA_REL_ "GenSigFirstTimeoutTime" BU_SG_REL_ BBM SG_ 2147484164 Pto2Consent_ISig_4 3000;
BA_REL_ "GenSigTimeoutTime" BU_SG_REL_ BBM SG_ 2147484164 Pto2Consent_ISig_4 150;
BA_REL_ "GenSigFirstTimeoutTime" BU_SG_REL_ VMCU SG_ 2147484164 Pto2Consent_ISig_4 3000;
BA_REL_ "GenSigTimeoutTime" BU_SG_REL_ VMCU SG_ 2147484164 Pto2Consent_ISig_4 150;
BA_REL_ "GenSigFirstTimeoutTime" BU_SG_REL_ VMCU SG_ 2147484164 DirectionGearAllowed 3000;
BA_REL_ "GenSigTimeoutTime" BU_SG_REL_ VMCU SG_ 2147484164 DirectionGearAllowed 150;
BA_REL_ "GenSigFirstTimeoutTime" BU_SG_REL_ VMCU SG_ 2147484164 TransmissionSystemPowerDownAck 3000;
BA_REL_ "GenSigTimeoutTime" BU_SG_REL_ VMCU SG_ 2147484164 TransmissionSystemPowerDownAck 150;
BA_REL_ "GenSigFirstTimeoutTime" BU_SG_REL_ IC3 SG_ 2147484164 EcoRollActiveStatus_ISig_4 3000;
BA_REL_ "GenSigTimeoutTime" BU_SG_REL_ IC3 SG_ 2147484164 EcoRollActiveStatus_ISig_4 150;
BA_REL_ "GenSigFirstTimeoutTime" BU_SG_REL_ VMCU SG_ 2147484164 EcoRollActiveStatus_ISig_4 3000;
BA_REL_ "GenSigTimeoutTime" BU_SG_REL_ VMCU SG_ 2147484164 EcoRollActiveStatus_ISig_4 150;
BA_REL_ "GenSigFirstTimeoutTime" BU_SG_REL_ IC3 SG_ 2147484164 TransmissionAirPressureLow 3000;
BA_REL_ "GenSigTimeoutTime" BU_SG_REL_ IC3 SG_ 2147484164 TransmissionAirPressureLow 150;
BA_REL_ "GenSigFirstTimeoutTime" BU_SG_REL_ CIOM SG_ 2147484164 GearBoxUnlockAuth_rqst 3000;
BA_REL_ "GenSigTimeoutTime" BU_SG_REL_ CIOM SG_ 2147484164 GearBoxUnlockAuth_rqst 150;
BA_REL_ "GenSigFirstTimeoutTime" BU_SG_REL_ EMS SG_ 2147484164 TransmEngineStop_req 3000;
BA_REL_ "GenSigTimeoutTime" BU_SG_REL_ EMS SG_ 2147484164 TransmEngineStop_req 150;
BA_REL_ "GenSigFirstTimeoutTime" BU_SG_REL_ IC3 SG_ 2147484164 RoadInclination_ISig_4 3000;
BA_REL_ "GenSigTimeoutTime" BU_SG_REL_ IC3 SG_ 2147484164 RoadInclination_ISig_4 150;
BA_REL_ "GenSigFirstTimeoutTime" BU_SG_REL_ VMCU SG_ 2147484164 RoadInclination_ISig_4 3000;
BA_REL_ "GenSigTimeoutTime" BU_SG_REL_ VMCU SG_ 2147484164 RoadInclination_ISig_4 150;
BA_REL_ "GenSigFirstTimeoutTime" BU_SG_REL_ EMS SG_ 2147484164 RoadInclination_ISig_4 3000;
BA_REL_ "GenSigTimeoutTime" BU_SG_REL_ EMS SG_ 2147484164 RoadInclination_ISig_4 150;
BA_REL_ "GenSigFirstTimeoutTime" BU_SG_REL_ DACU SG_ 2147484164 RoadInclination_ISig_4 3000;
BA_REL_ "GenSigTimeoutTime" BU_SG_REL_ DACU SG_ 2147484164 RoadInclination_ISig_4 150;
BA_REL_ "GenSigFirstTimeoutTime" BU_SG_REL_ EMS SG_ 2147484164 ACC_SGO_TransmissionStatus 3000;
BA_REL_ "GenSigTimeoutTime" BU_SG_REL_ EMS SG_ 2147484164 ACC_SGO_TransmissionStatus 150;
BA_REL_ "GenSigFirstTimeoutTime" BU_SG_REL_ DACU SG_ 2147484164 ACC_SGO_TransmissionStatus 3000;
BA_REL_ "GenSigTimeoutTime" BU_SG_REL_ DACU SG_ 2147484164 ACC_SGO_TransmissionStatus 150;
BA_REL_ "GenSigFirstTimeoutTime" BU_SG_REL_ DACU SG_ 2147484164 TransmOutputShaftSpeedSigned 3000;
BA_REL_ "GenSigTimeoutTime" BU_SG_REL_ DACU SG_ 2147484164 TransmOutputShaftSpeedSigned 150;
BA_REL_ "GenSigFirstTimeoutTime" BU_SG_REL_ IC3 SG_ 2147484164 ClutchOverloadStatus_ISig_4 3000;
BA_REL_ "GenSigTimeoutTime" BU_SG_REL_ IC3 SG_ 2147484164 ClutchOverloadStatus_ISig_4 150;
BA_REL_ "GenSigFirstTimeoutTime" BU_SG_REL_ BBM SG_ 2147484164 ClutchOverloadStatus_ISig_4 3000;
BA_REL_ "GenSigTimeoutTime" BU_SG_REL_ BBM SG_ 2147484164 ClutchOverloadStatus_ISig_4 150;
BA_REL_ "GenSigTimeoutTime" BU_SG_REL_ VMCU SG_ 2564485459 PhysDiagRespSig_F1_53_ISig_4 600;
BA_REL_ "GenSigFirstTimeoutTime" BU_SG_REL_ CIOM SG_ 2564445169 PhysDiagReqSig_53_F1_ISig_4 3000;
BA_REL_ "GenSigTimeoutTime" BU_SG_REL_ CIOM SG_ 2564445169 PhysDiagReqSig_53_F1_ISig_4 600;
VAL_ 2147484579 Pto1BadCondition 15 "PtoBadCondition_NotAvailable" 14 "PtoBadCondition_Error" 13 "PtoBadCondition_Spare_02" 12 "PtoBadCondition_TransferBoxNotInNeutral" 11 "PtoBadCondition_CrossCountryAlreadyactive" 10 "PtoBadCondition_AirPressureTooLow" 9 "PtoBadCondition_WrongGearSplitSelected" 8 "PtoBadCondition_ClutchPedalNotPressed" 7 "PtoBadCondition_ServiceBrakeNotApplied" 6 "PtoBadCondition_ParkbrakeNotActive" 5 "PtoBadCondition_VehicleSpeedTooHigh" 4 "PtoBadCondition_EngineSpeedTooLow" 3 "PtoBadCondition_EngineSpeedTooHigh" 2 "PtoBadCondition_GearboxNotInNeutral" 1 "PtoBadCondition_BadConditionsForEngagementGeneric" 0 "PtoBadCondition_NoBadConditionForEngagement" ;
VAL_ 2147484579 Pto4BadCondition 15 "PtoBadCondition_NotAvailable" 14 "PtoBadCondition_Error" 13 "PtoBadCondition_Spare_02" 12 "PtoBadCondition_TransferBoxNotInNeutral" 11 "PtoBadCondition_CrossCountryAlreadyactive" 10 "PtoBadCondition_AirPressureTooLow" 9 "PtoBadCondition_WrongGearSplitSelected" 8 "PtoBadCondition_ClutchPedalNotPressed" 7 "PtoBadCondition_ServiceBrakeNotApplied" 6 "PtoBadCondition_ParkbrakeNotActive" 5 "PtoBadCondition_VehicleSpeedTooHigh" 4 "PtoBadCondition_EngineSpeedTooLow" 3 "PtoBadCondition_EngineSpeedTooHigh" 2 "PtoBadCondition_GearboxNotInNeutral" 1 "PtoBadCondition_BadConditionsForEngagementGeneric" 0 "PtoBadCondition_NoBadConditionForEngagement" ;
VAL_ 2147484579 Pto2BadCondition 15 "PtoBadCondition_NotAvailable" 14 "PtoBadCondition_Error" 13 "PtoBadCondition_Spare_02" 12 "PtoBadCondition_TransferBoxNotInNeutral" 11 "PtoBadCondition_CrossCountryAlreadyactive" 10 "PtoBadCondition_AirPressureTooLow" 9 "PtoBadCondition_WrongGearSplitSelected" 8 "PtoBadCondition_ClutchPedalNotPressed" 7 "PtoBadCondition_ServiceBrakeNotApplied" 6 "PtoBadCondition_ParkbrakeNotActive" 5 "PtoBadCondition_VehicleSpeedTooHigh" 4 "PtoBadCondition_EngineSpeedTooLow" 3 "PtoBadCondition_EngineSpeedTooHigh" 2 "PtoBadCondition_GearboxNotInNeutral" 1 "PtoBadCondition_BadConditionsForEngagementGeneric" 0 "PtoBadCondition_NoBadConditionForEngagement" ;
VAL_ 2147484579 PtoRequest 3 "InactiveActive_NotAvailable" 2 "InactiveActive_Error" 1 "InactiveActive_Active" 0 "InactiveActive_Inactive" ;
VAL_ 2147484579 Pto2ConsentRequest 3 "PtoConsentRequest_NotAvailable" 2 "PtoConsentRequest_Error" 1 "PtoConsentRequest_PTOOperationDesired" 0 "PtoConsentRequest_PTOOperationNotDesired" ;
VAL_ 2147484579 PBStatusDisplay_cmd_ISig_4 3 "DisableEnable_NotAvailable" 2 "DisableEnable_Error" 1 "DisableEnable_Enable" 0 "DisableEnable_Disable" ;
VAL_ 2147484579 Pto4DrivingRequest 3 "OffOn_NotAvailable" 2 "OffOn_Error" 1 "OffOn_On" 0 "OffOn_Off" ;
VAL_ 2147484579 Pto3Indication 3 "Request_NotAvailable" 2 "Request_Error" 1 "Request_RequestActive" 0 "Request_NotRequested" ;
VAL_ 2147484579 Pto2Status_ISig_4 3 "InactiveActive_NotAvailable" 2 "InactiveActive_Error" 1 "InactiveActive_Active" 0 "InactiveActive_Inactive" ;
VAL_ 2147484579 Pto4Status_ISig_4 3 "InactiveActive_NotAvailable" 2 "InactiveActive_Error" 1 "InactiveActive_Active" 0 "InactiveActive_Inactive" ;
VAL_ 2147484579 RampLevelRequestACK_ISig_4 3 "ChangeRequest2Bit_NotAvailable" 2 "ChangeRequest2Bit_Error" 1 "ChangeRequest2Bit_Change" 0 "ChangeRequest2Bit_TakeNoAction" ;
VAL_ 2147484579 Pto3BadCondition 15 "PtoBadCondition_NotAvailable" 14 "PtoBadCondition_Error" 13 "PtoBadCondition_Spare_02" 12 "PtoBadCondition_TransferBoxNotInNeutral" 11 "PtoBadCondition_CrossCountryAlreadyactive" 10 "PtoBadCondition_AirPressureTooLow" 9 "PtoBadCondition_WrongGearSplitSelected" 8 "PtoBadCondition_ClutchPedalNotPressed" 7 "PtoBadCondition_ServiceBrakeNotApplied" 6 "PtoBadCondition_ParkbrakeNotActive" 5 "PtoBadCondition_VehicleSpeedTooHigh" 4 "PtoBadCondition_EngineSpeedTooLow" 3 "PtoBadCondition_EngineSpeedTooHigh" 2 "PtoBadCondition_GearboxNotInNeutral" 1 "PtoBadCondition_BadConditionsForEngagementGeneric" 0 "PtoBadCondition_NoBadConditionForEngagement" ;
VAL_ 2147484579 PtosStatus_ISig_4 3 "PtosStatus_NotAvailable" 2 "PtosStatus_Error" 1 "PtosStatus_OneOrMorePTOEngaged" 0 "PtosStatus_NoPTOEngaged" ;
VAL_ 2147484579 FrontWheelDriveAutoStatus_ISig_4 3 "OffAutomatic_NotAvailable" 2 "OffAutomatic_Error" 1 "OffAutomatic_Automatic" 0 "OffAutomatic_Off" ;
VAL_ 2147484579 Pto1ConsentRequest 3 "PtoConsentRequest_NotAvailable" 2 "PtoConsentRequest_Error" 1 "PtoConsentRequest_PTOOperationDesired" 0 "PtoConsentRequest_PTOOperationNotDesired" ;
VAL_ 2147484579 Pto4Indication 3 "Request_NotAvailable" 2 "Request_Error" 1 "Request_RequestActive" 0 "Request_NotRequested" ;
VAL_ 2147484579 Pto1Indication 3 "Request_NotAvailable" 2 "Request_Error" 1 "Request_RequestActive" 0 "Request_NotRequested" ;
VAL_ 2147484579 Pto3Status_ISig_4 3 "InactiveActive_NotAvailable" 2 "InactiveActive_Error" 1 "InactiveActive_Active" 0 "InactiveActive_Inactive" ;
VAL_ 2147484579 Pto2Indication 3 "Request_NotAvailable" 2 "Request_Error" 1 "Request_RequestActive" 0 "Request_NotRequested" ;
VAL_ 2147484579 Pto1FeedbackStatus_ISig_4 3 "OffOn_NotAvailable" 2 "OffOn_Error" 1 "OffOn_On" 0 "OffOn_Off" ;
VAL_ 2147484579 TransferCaseOrSplitboxPTOMode_IS 3 "InactiveActive_NotAvailable" 2 "InactiveActive_Error" 1 "InactiveActive_Active" 0 "InactiveActive_Inactive" ;
VAL_ 2147484579 DirIndRearLamp_Stat_ISig_4 7 "LampCheckLeftRight_stat_NotAvailable" 6 "LampCheckLeftRight_stat_Error" 5 "LampCheckLeftRight_stat_Spare" 4 "LampCheckLeftRight_stat_TestedLeftAndRightLampNOK" 3 "LampCheckLeftRight_stat_TestedRightLampNOK" 2 "LampCheckLeftRight_stat_TestedLeftLampNOK" 1 "LampCheckLeftRight_stat_TestedLampOK" 0 "LampCheckLeftRight_stat_NotTested" ;
VAL_ 2147484579 Pto1Status_ISig_4 3 "InactiveActive_NotAvailable" 2 "InactiveActive_Error" 1 "InactiveActive_Active" 0 "InactiveActive_Inactive" ;
VAL_ 2147484579 Pto3DrivingRequest 3 "OffOn_NotAvailable" 2 "OffOn_Error" 1 "OffOn_On" 0 "OffOn_Off" ;
VAL_ 2147484373 StoreIdleValue 3 "StoreIdleValue_NotAvailable" 2 "StoreIdleValue_Error" 1 "StoreIdleValue_StoreSetValue" 0 "StoreIdleValue_DoNOTStoreValue" ;
VAL_ 2147484373 ESCReqEMS_CtrlTrimMode_ISig_4 15 "CtrlTrimMode_NotAvailable" 14 "CtrlTrimMode_Error" 13 "CtrlTrimMode_Spare_08" 12 "CtrlTrimMode_Spare_07" 11 "CtrlTrimMode_Spare_06" 10 "CtrlTrimMode_Spare_05" 9 "CtrlTrimMode_Spare_04" 8 "CtrlTrimMode_Spare_03" 7 "CtrlTrimMode_Spare_02" 6 "CtrlTrimMode_Spare_01" 5 "CtrlTrimMode_Spare" 4 "CtrlTrimMode_MuddySiteEngineSpeedControl" 3 "CtrlTrimMode_AirManagementEngineSpeedControl" 2 "CtrlTrimMode_IdleAdjust" 1 "CtrlTrimMode_PTOEngineSpeedControl" 0 "CtrlTrimMode_NoRequest" ;
VAL_ 2147484373 ESCReqESC_CtrlTrimMode_ISig_4 15 "CtrlTrimMode_NotAvailable" 14 "CtrlTrimMode_Error" 13 "CtrlTrimMode_Spare_08" 12 "CtrlTrimMode_Spare_07" 11 "CtrlTrimMode_Spare_06" 10 "CtrlTrimMode_Spare_05" 9 "CtrlTrimMode_Spare_04" 8 "CtrlTrimMode_Spare_03" 7 "CtrlTrimMode_Spare_02" 6 "CtrlTrimMode_Spare_01" 5 "CtrlTrimMode_Spare" 4 "CtrlTrimMode_MuddySiteEngineSpeedControl" 3 "CtrlTrimMode_AirManagementEngineSpeedControl" 2 "CtrlTrimMode_IdleAdjust" 1 "CtrlTrimMode_PTOEngineSpeedControl" 0 "CtrlTrimMode_NoRequest" ;
VAL_ 2147484373 ESCReqEMS_CtrlTrimStat_ISig_4 7 "CtrlTrimStat_NotAvailable" 6 "CtrlTrimStat_Error" 5 "CtrlTrimStat_Spare_02" 4 "CtrlTrimStat_Spare_01" 3 "CtrlTrimStat_Spare" 2 "CtrlTrimStat_TrimActive" 1 "CtrlTrimStat_ControlActive" 0 "CtrlTrimStat_NoRequestActive" ;
VAL_ 2147484373 TrailerConnected_ISig_4 3 "NoYes_NotAvailable" 2 "NoYes_Error" 1 "NoYes_Yes" 0 "NoYes_No" ;
VAL_ 2147484373 ESCReqESC_CtrlTrimStat_ISig_4 7 "CtrlTrimStat_NotAvailable" 6 "CtrlTrimStat_Error" 5 "CtrlTrimStat_Spare_02" 4 "CtrlTrimStat_Spare_01" 3 "CtrlTrimStat_Spare" 2 "CtrlTrimStat_TrimActive" 1 "CtrlTrimStat_ControlActive" 0 "CtrlTrimStat_NoRequestActive" ;
VAL_ 2147484373 SCLLogicEnable_rqst 7 "SCLLogicEnable_rqst_NotAvailable" 6 "SCLLogicEnable_rqst_Error" 5 "SCLLogicEnable_rqst_Spare_disable_value_02" 4 "SCLLogicEnable_rqst_Spare_disable_value_01" 3 "SCLLogicEnable_rqst_Enable_locking" 2 "SCLLogicEnable_rqst_Enable_unlocking" 1 "SCLLogicEnable_rqst_Retry_disable" 0 "SCLLogicEnable_rqst_Disable" ;
VAL_ 2147484373 ESCReqESC_CtrlTrimReq_ISig_4 7 "CtrlTrimReq_NotAvailable" 6 "CtrlTrimReq_Error" 5 "CtrlTrimReq_Spare_02" 4 "CtrlTrimReq_Spare_01" 3 "CtrlTrimReq_Spare" 2 "CtrlTrimReq_TrimRampDown" 1 "CtrlTrimReq_TrimRampUp" 0 "CtrlTrimReq_NoRamp" ;
VAL_ 2147484373 BrakeLight_rqst_ISig_4 7 "BrakeLight_rqst_NotAvailable" 6 "BrakeLight_rqst_SpareValue_03" 5 "BrakeLight_rqst_SpareValue_02" 4 "BrakeLight_rqst_SpareValue_01" 3 "BrakeLight_rqst_SpareValue" 2 "BrakeLight_rqst_EmergencyBrakeLightOn" 1 "BrakeLight_rqst_BrakeLightOn" 0 "BrakeLight_rqst_BrakeLightAndEmergencyBrakeLightOff" ;
VAL_ 2147484373 ESCReqEMS_CtrlTrimReq_ISig_4 7 "CtrlTrimReq_NotAvailable" 6 "CtrlTrimReq_Error" 5 "CtrlTrimReq_Spare_02" 4 "CtrlTrimReq_Spare_01" 3 "CtrlTrimReq_Spare" 2 "CtrlTrimReq_TrimRampDown" 1 "CtrlTrimReq_TrimRampUp" 0 "CtrlTrimReq_NoRamp" ;
VAL_ 2147484369 TrailerTest_stat 7 "TrailerTest_stat_NotAvailable" 6 "TrailerTest_stat_Error" 5 "TrailerTest_stat_InProgress_TrailerNotConnected" 4 "TrailerTest_stat_NotPossibleLowVoltgeOrLowPressure" 3 "TrailerTest_stat_TrailerTestIncentive" 2 "TrailerTest_stat_NotPossibleServiceBrakeApplied" 1 "TrailerTest_stat_InProgress" 0 "TrailerTest_stat_IdleNoTrailerTest" ;
VAL_ 2147484369 Washing_HMI_rqst_ISig_4 3 "InactiveActive_NotAvailable" 2 "InactiveActive_Error" 1 "InactiveActive_Active" 0 "InactiveActive_Inactive" ;
VAL_ 2147484369 AuxBrakesDwngrdModeInd_rqst 7 "AuxBrakesDwngrdModeInd_rqst_NotAvailable" 6 "AuxBrakesDwngrdModeInd_rqst_Error" 5 "AuxBrakesDwngrdModeInd_rqst_Spare_3" 4 "AuxBrakesDwngrdModeInd_rqst_Spare_2" 3 "AuxBrakesDwngrdModeInd_rqst_Spare_1" 2 "AuxBrakesDwngrdModeInd_rqst_AuxiliaryBrakesShutdown" 1 "AuxBrakesDwngrdModeInd_rqst_ABSDowngradedMode" 0 "AuxBrakesDwngrdModeInd_rqst_NoRequest" ;
VAL_ 2147484369 DirInd_StalkStatus_1 7 "DirInd_StalkStatus_NotAvailable" 6 "DirInd_StalkStatus_Error" 5 "DirInd_StalkStatus_Spare" 4 "DirInd_StalkStatus_RightTemporaryTurningIndication" 3 "DirInd_StalkStatus_LeftTemporaryTurningIndication" 2 "DirInd_StalkStatus_RightTurningIndication" 1 "DirInd_StalkStatus_LeftTurningIndication" 0 "DirInd_StalkStatus_NeutralRestingPositon" ;
VAL_ 2147484369 KeyAuthentication_rqst 7 "KeyAuthentication_rqst_NotAvailable" 6 "KeyAuthentication_rqst_Error" 5 "KeyAuthentication_rqst_Spare02" 4 "KeyAuthentication_rqst_Spare01" 3 "KeyAuthentication_rqst_Spare" 2 "KeyAuthentication_rqst_RequestAuthentication" 1 "KeyAuthentication_rqst_KeyIsInserted" 0 "KeyAuthentication_rqst_KeyNotPresent" ;
VAL_ 2147484369 EngineSpeedControlStatus 7 "EngineSpeedControlStatus_NotAvailable" 6 "EngineSpeedControlStatus_Error" 5 "EngineSpeedControlStatus_Spare_01" 4 "EngineSpeedControlStatus_AutoPtoMin_AutoNeutral" 3 "EngineSpeedControlStatus_CrossCountryEngineSpeedControlActive" 2 "EngineSpeedControlStatus_ActiveExternalSource" 1 "EngineSpeedControlStatus_ActiveManual" 0 "EngineSpeedControlStatus_Inactive" ;
VAL_ 2147484369 SecondThrottle 3 "InactiveActive_NotAvailable" 2 "InactiveActive_Error" 1 "InactiveActive_Active" 0 "InactiveActive_Inactive" ;
VAL_ 2147484369 PredeliveryModeIndication_cmd 3 "DeactivateActivate_NotAvailable" 2 "DeactivateActivate_Error" 1 "DeactivateActivate_Activate" 0 "DeactivateActivate_Deactivate" ;
VAL_ 2147484369 LoadCutOffIndication_cmd_ISig_4 3 "LoadCutOffIndication_cmd_NotAvailable" 2 "LoadCutOffIndication_cmd_Error" 1 "LoadCutOffIndication_cmd_LoadCutOffIndication" 0 "LoadCutOffIndication_cmd_NoIndication" ;
VAL_ 2147484369 ExitPreDeliveryModeHMI_rqst_ISig 3 "FalseTrue_NotAvaiable" 2 "FalseTrue_Error" 1 "FalseTrue_True" 0 "FalseTrue_False" ;
VAL_ 2147484369 FdEquipmentStatus1_ISig_4 3 "InactiveActive_NotAvailable" 2 "InactiveActive_Error" 1 "InactiveActive_Active" 0 "InactiveActive_Inactive" ;
VAL_ 2147484182 ParkBrakeAlert_ISig_4 3 "Alert_NotAvailable" 2 "Alert_Error" 1 "Alert_Alert" 0 "Alert_NoAlert" ;
VAL_ 2147484182 IntLightMode_CoreRqst_IL_Mode 7 "IL_ModeReq_NotAvailable" 6 "IL_ModeReq_ErrorIndicator" 5 "IL_ModeReq_NonHMIModeMax" 4 "IL_ModeReq_NonHMIModeResting" 3 "IL_ModeReq_Max" 2 "IL_ModeReq_Resting" 1 "IL_ModeReq_NightDriving" 0 "IL_ModeReq_OFF" ;
VAL_ 2147484182 SteeringColumnLockErrInd_rqst 7 "SteeringColumnLockErrInd_rqst_NotAvailable" 6 "SteeringColumnLockErrInd_rqst_Error" 5 "SteeringColumnLockErrInd_rqst_SpareValue01" 4 "SteeringColumnLockErrInd_rqst_SpareValue" 3 "SteeringColumnLockErrInd_rqst_OtherError" 2 "SteeringColumnLockErrInd_rqst_NotPossibleToUnlock" 1 "SteeringColumnLockErrInd_rqst_NotPossibleToLock" 0 "SteeringColumnLockErrInd_rqst_NoErrorIndication" ;
VAL_ 2147484182 ParkingLight_Indication 3 "DeviceIndication_SpareValue" 2 "DeviceIndication_Blink" 1 "DeviceIndication_On" 0 "DeviceIndication_Off" ;
VAL_ 2147484182 DaytimeRunningLight_Indication 3 "DeviceIndication_SpareValue" 2 "DeviceIndication_Blink" 1 "DeviceIndication_On" 0 "DeviceIndication_Off" ;
VAL_ 2147484182 EPBBackupMode_ISig_4 15 "EPBBackupMode_NotAvailable" 14 "EPBBackupMode_Error" 13 "EPBBackupMode_Level13" 12 "EPBBackupMode_Level12" 11 "EPBBackupMode_Level11" 10 "EPBBackupMode_Level10" 9 "EPBBackupMode_Level9" 8 "EPBBackupMode_Level8" 7 "EPBBackupMode_Level7" 6 "EPBBackupMode_Level6" 5 "EPBBackupMode_Level5" 4 "EPBBackupMode_Level4" 3 "EPBBackupMode_Level3" 2 "EPBBackupMode_Level2" 1 "EPBBackupMode_Level1" 0 "EPBBackupMode_Level0_NoBackUp" ;
VAL_ 2147484182 WiperModeStatus_ISig_4 7 "WiperModeStatus_NotAvailable" 6 "WiperModeStatus_ErrorIndicator" 5 "WiperModeStatus_Spare02" 4 "WiperModeStatus_Spare01" 3 "WiperModeStatus_Spare" 2 "WiperModeStatus_HighSpeedWiping" 1 "WiperModeStatus_LowSpeedWiping" 0 "WiperModeStatus_WiperOff" ;
VAL_ 2147484182 FrontFog_Indication 3 "DeviceIndication_SpareValue" 2 "DeviceIndication_Blink" 1 "DeviceIndication_On" 0 "DeviceIndication_Off" ;
VAL_ 2147484182 PBReleaseAcceptance_stat_ISig_4 7 "PBReleaseAcceptance_stat_NotAvailable" 6 "PBReleaseAcceptance_stat_Error" 5 "PBReleaseAcceptance_stat_Spare_03" 4 "PBReleaseAcceptance_stat_AccelPedalOrHCURequested" 3 "PBReleaseAcceptance_stat_ReleaseRequestAccepted" 2 "PBReleaseAcceptance_stat_BrakeOrAccelPedalRequested" 1 "PBReleaseAcceptance_stat_BrakePedalRequested" 0 "PBReleaseAcceptance_stat_NoRequestDetectedOrRequestAborted" ;
VAL_ 2147484182 DrivingLightPlus_Indication 3 "DeviceIndication_SpareValue" 2 "DeviceIndication_Blink" 1 "DeviceIndication_On" 0 "DeviceIndication_Off" ;
VAL_ 2147484182 IntLightMode_CoreRqst_EventFlag 1 "EventFlag_High" 0 "EventFlag_Low" ;
VAL_ 2147484182 ParkingBrake_stat_ISig_4 3 "ParkingBrake_stat_NotAvailable" 2 "ParkingBrake_stat_Error" 1 "ParkingBrake_stat_ParkingBrakeActivated" 0 "ParkingBrake_stat_ParkingBrakeReleased" ;
VAL_ 2147484182 DrivingLight_Indication 3 "DeviceIndication_SpareValue" 2 "DeviceIndication_Blink" 1 "DeviceIndication_On" 0 "DeviceIndication_Off" ;
VAL_ 2147484182 MirrorHeatingMode_ISig_4 7 "MirrorHeat_NotAvailable" 6 "MirrorHeat_ErrorIndicator" 5 "MirrorHeat_SpareValue_02" 4 "MirrorHeat_SpareValue_01" 3 "MirrorHeat_SpareValue" 2 "MirrorHeat_ONExtendedMode" 1 "MirrorHeat_ONNormalMode" 0 "MirrorHeat_OFF" ;
VAL_ 2147484182 RearFog_Indication 3 "DeviceIndication_SpareValue" 2 "DeviceIndication_Blink" 1 "DeviceIndication_On" 0 "DeviceIndication_Off" ;
VAL_ 2147484180 LiftAxle2LiftFuncSelected_ISig_4 7 "LiftAxleLiftAutoFuncSelected_NotAvailable" 6 "LiftAxleLiftAutoFuncSelected_Error" 5 "LiftAxleLiftAutoFuncSelected_Reserved" 4 "LiftAxleLiftAutoFuncSelected_UnlimitedLift" 3 "LiftAxleLiftAutoFuncSelected_LiftOverload" 2 "LiftAxleLiftAutoFuncSelected_LiftPlus30" 1 "LiftAxleLiftAutoFuncSelected_Lift" 0 "LiftAxleLiftAutoFuncSelected_NoLift" ;
VAL_ 2147484180 StopLevelChangeAck_ISig_4 3 "StopLevelChangeStatus_NotAvailable" 2 "StopLevelChangeStatus_ErrorIndicator" 1 "StopLevelChangeStatus_LevelChangedStopped" 0 "StopLevelChangeStatus_NoStopRequest" ;
VAL_ 2147484180 HeightAdjustmentAllowed_ISig_4 3 "FalseTrue_NotAvaiable" 2 "FalseTrue_Error" 1 "FalseTrue_True" 0 "FalseTrue_False" ;
VAL_ 2147484180 LiftAxle2LowerACK_ISig_4 7 "LiftAxle2LowerACK_NotAvailable" 6 "LiftAxle2LowerACK_Error" 5 "LiftAxle2LowerACK_SystemDeniedVersatile" 4 "LiftAxle2LowerACK_Spare_01" 3 "LiftAxle2LowerACK_Spare" 2 "LiftAxle2LowerACK_LowerDeniedRAS_EC" 1 "LiftAxle2LowerACK_ChangeAcknowledged" 0 "LiftAxle2LowerACK_NoAction" ;
VAL_ 2147484180 LiftAxle2UpRequestACK_ISig_4 7 "LiftAxleUpRequestACK_NotAvailable" 6 "LiftAxleUpRequestACK_Error" 5 "LiftAxleUpRequestACK_SystemDeniedVersatile" 4 "LiftAxleUpRequestACK_LiftDeniedPBrakeActive" 3 "LiftAxleUpRequestACK_LiftDeniedRearOverload" 2 "LiftAxleUpRequestACK_LiftDeniedFrontOverload" 1 "LiftAxleUpRequestACK_ChangeAcknowledged" 0 "LiftAxleUpRequestACK_NoAction" ;
VAL_ 2147484180 RideHeightStatus_ISig_4 15 "RideHeightStatus_NotAvailable" 14 "RideHeightStatus_ErrorIndicator" 13 "RideHeightStatus_NotDefined_03" 12 "RideHeightStatus_NotDefined_02" 11 "RideHeightStatus_NotDefined_01" 10 "RideHeightStatus_NotDefined" 9 "RideHeightStatus_AlternativeDrivePosition2" 8 "RideHeightStatus_AlternativeDrivePosition1" 7 "RideHeightStatus_AlternativeDrivePosition" 6 "RideHeightStatus_HighDrivePosition" 5 "RideHeightStatus_LowDrivePosition" 4 "RideHeightStatus_SpeedDependentDrivePositionHighSpeed" 3 "RideHeightStatus_SpeedDependentDrivePositionLowSpeed" 2 "RideHeightStatus_StandardUserDrivePosition" 1 "RideHeightStatus_StandardFactoryDrivePosition" 0 "RideHeightStatus_Inactive" ;
VAL_ 2147484180 RideHeightOutsideTargetRange_ISi 7 "HeightOutsideTargetRange_NotAvailable" 6 "HeightOutsideTargetRange_Error" 5 "HeightOutsideTargetRange_NotDefined_02" 4 "HeightOutsideTargetRange_NotDefined_01" 3 "HeightOutsideTargetRange_NotDefined" 2 "HeightOutsideTargetRange_ToHigh" 1 "HeightOutsideTargetRange_ToLow" 0 "HeightOutsideTargetRange_Inactive" ;
VAL_ 2147484180 LoadDistributionFuncSelected_ISi 15 "LoadDistributionFuncSelected_NotAvaiable" 14 "LoadDistributionFuncSelected_ErrorIndicator" 13 "LoadDistributionFuncSelected_SpareValue_08" 12 "LoadDistributionFuncSelected_SpareValue_07" 11 "LoadDistributionFuncSelected_SpareValue_06" 10 "LoadDistributionFuncSelected_SpareValue_05" 9 "LoadDistributionFuncSelected_SpareValue_04" 8 "LoadDistributionFuncSelected_SpareValue_03" 7 "LoadDistributionFuncSelected_SpareValue_02" 6 "LoadDistributionFuncSelected_MaximumTractionStartingHelp" 5 "LoadDistributionFuncSelected_VariableAxleLoad" 4 "LoadDistributionFuncSelected_NoLoadDistribution" 3 "LoadDistributionFuncSelected_AlternativeLoad" 2 "LoadDistributionFuncSelected_MaximumTractionTractionHelp" 1 "LoadDistributionFuncSelected_OptimisedTraction" 0 "LoadDistributionFuncSelected_NormalLoad" ;
VAL_ 2147484180 RideHeightStorageAck_ISig_4 3 "StorageAck_NotAvaiable" 2 "StorageAck_Error" 1 "StorageAck_ChangeAcknowledged" 0 "StorageAck_TakeNoAction" ;
VAL_ 2147484180 LiftAxle2AutoLiftSelected_ISig_4 3 "FalseTrue_NotAvaiable" 2 "FalseTrue_Error" 1 "FalseTrue_True" 0 "FalseTrue_False" ;
VAL_ 2147484180 LiftAxle1UpRequestACK_ISig_4 7 "LiftAxleUpRequestACK_NotAvailable" 6 "LiftAxleUpRequestACK_Error" 5 "LiftAxleUpRequestACK_SystemDeniedVersatile" 4 "LiftAxleUpRequestACK_LiftDeniedPBrakeActive" 3 "LiftAxleUpRequestACK_LiftDeniedRearOverload" 2 "LiftAxleUpRequestACK_LiftDeniedFrontOverload" 1 "LiftAxleUpRequestACK_ChangeAcknowledged" 0 "LiftAxleUpRequestACK_NoAction" ;
VAL_ 2147484180 LiftAxle1PositionStatus_ISig_4 7 "LiftAxlePositionStatus_NotAvailable" 6 "LiftAxlePositionStatus_Error" 5 "LiftAxlePositionStatus_Reserved_01" 4 "LiftAxlePositionStatus_Reserved" 3 "LiftAxlePositionStatus_Lifting" 2 "LiftAxlePositionStatus_Lowering" 1 "LiftAxlePositionStatus_Lifted" 0 "LiftAxlePositionStatus_Lowered" ;
VAL_ 2147484180 LiftAxle1LowerACK_ISig_4 7 "LiftAxle1LowerACK_NotAvailable" 6 "LiftAxle1LowerACK_Error" 5 "LiftAxle1LowerACK_SystemDeniedVersatile" 4 "LiftAxle1LowerACK_Spare_01" 3 "LiftAxle1LowerACK_Spare" 2 "LiftAxle1LowerACK_LowerDeniedRAS_EC" 1 "LiftAxle1LowerACK_ChangeAcknowledged" 0 "LiftAxle1LowerACK_NoAction" ;
VAL_ 2147484180 LiftAxle1AutoLiftSelected_ISig_4 3 "FalseTrue_NotAvaiable" 2 "FalseTrue_Error" 1 "FalseTrue_True" 0 "FalseTrue_False" ;
VAL_ 2147484180 LiftAxle2PositionStatus_ISig_4 7 "LiftAxlePositionStatus_NotAvailable" 6 "LiftAxlePositionStatus_Error" 5 "LiftAxlePositionStatus_Reserved_01" 4 "LiftAxlePositionStatus_Reserved" 3 "LiftAxlePositionStatus_Lifting" 2 "LiftAxlePositionStatus_Lowering" 1 "LiftAxlePositionStatus_Lifted" 0 "LiftAxlePositionStatus_Lowered" ;
VAL_ 2147484180 LevelControlInformation_ISig_4 15 "LevelControlInformation_NotAvailable" 14 "LevelControlInformation_Error" 13 "LevelControlInformation_Reserved_06" 12 "LevelControlInformation_Reserved_05" 11 "LevelControlInformation_Reserved_04" 10 "LevelControlInformation_Reserved_03" 9 "LevelControlInformation_Reserved_02" 8 "LevelControlInformation_Reserved_01" 7 "LevelControlInformation_Reserved" 6 "LevelControlInformation_LimpHome" 5 "LevelControlInformation_FerryFunction" 4 "LevelControlInformation_KneelingHeight" 3 "LevelControlInformation_DriveHeight" 2 "LevelControlInformation_DockingHeight" 1 "LevelControlInformation_HeightAdjustment" 0 "LevelControlInformation_Prohibit" ;
VAL_ 2147484180 LiftAxle1LiftFuncSelected_ISig_4 7 "LiftAxleLiftAutoFuncSelected_NotAvailable" 6 "LiftAxleLiftAutoFuncSelected_Error" 5 "LiftAxleLiftAutoFuncSelected_Reserved" 4 "LiftAxleLiftAutoFuncSelected_UnlimitedLift" 3 "LiftAxleLiftAutoFuncSelected_LiftOverload" 2 "LiftAxleLiftAutoFuncSelected_LiftPlus30" 1 "LiftAxleLiftAutoFuncSelected_Lift" 0 "LiftAxleLiftAutoFuncSelected_NoLift" ;
VAL_ 2147484180 LoadDistributionChangeACK_ISig_4 7 "LoadDistributionChangeACK_NotAvailable" 6 "LoadDistributionChangeACK_Error" 5 "LoadDistributionChangeACK_SystemDeniedVersatile" 4 "LoadDistributionChangeACK_Reserved_2" 3 "LoadDistributionChangeACK_Reserved_1" 2 "LoadDistributionChangeACK_LoadShiftDeniedFALIMOverload" 1 "LoadDistributionChangeACK_ChangeAcknowledged" 0 "LoadDistributionChangeACK_NoAction" ;
VAL_ 2147484180 RampLevelStorageAck_ISig_4 3 "StorageAck_NotAvaiable" 2 "StorageAck_Error" 1 "StorageAck_ChangeAcknowledged" 0 "StorageAck_TakeNoAction" ;
VAL_ 2147484180 LoadDistributionSelected_ISig_4 15 "LoadDistributionSelected_NotAvailable" 14 "LoadDistributionSelected_Error" 13 "LoadDistributionSelected_Reserved_05" 12 "LoadDistributionSelected_Reserved_04" 11 "LoadDistributionSelected_Reserved_03" 10 "LoadDistributionSelected_TractionHelp2" 9 "LoadDistributionSelected_StartingHelp2" 8 "LoadDistributionSelected_VariableAxleLoad" 7 "LoadDistributionSelected_NoLoadDistribution" 6 "LoadDistributionSelected_TractionHelpInterDiff" 5 "LoadDistributionSelected_StartingHelpInterDiff" 4 "LoadDistributionSelected_AlternativeLoad" 3 "LoadDistributionSelected_TractionHelp" 2 "LoadDistributionSelected_StartingHelp" 1 "LoadDistributionSelected_OptimisedTraction" 0 "LoadDistributionSelected_NormalLoad" ;
VAL_ 2147484180 RideHeightFunctionStatus_ISig_4 15 "RideHeightFunction_NotAvailable" 14 "RideHeightFunction_ErrorIndicator" 13 "RideHeightFunction_NotDefined_05" 12 "RideHeightFunction_NotDefined_04" 11 "RideHeightFunction_NotDefined_03" 10 "RideHeightFunction_NotDefined_02" 9 "RideHeightFunction_NotDefined_01" 8 "RideHeightFunction_NotDefined" 7 "RideHeightFunction_AlternativeDrivePosition2" 6 "RideHeightFunction_AlternativeDrivePosition1" 5 "RideHeightFunction_LowDrivePosition" 4 "RideHeightFunction_HighDrivePosition" 3 "RideHeightFunction_SpeedDependentDrivePosition" 2 "RideHeightFunction_AlternativeDrivePosition" 1 "RideHeightFunction_StandardDrivePosition" 0 "RideHeightFunction_Inactive" ;
VAL_ 2147484168 TransmLowRangeSenseSwitch_ISig_4 3 "OffOn_NotAvailable" 2 "OffOn_Error" 1 "OffOn_On" 0 "OffOn_Off" ;
VAL_ 2147484168 TransmSystemPowerDown_rqst 3 "TransmSystemPowerDown_rqst_DontCare" 2 "TransmSystemPowerDown_rqst_NotDefined" 1 "TransmSystemPowerDown_rqst_PowerDownRequestActive" 0 "TransmSystemPowerDown_rqst_PowerDownRequestInactive" ;
VAL_ 2147484168 TransmissionNeutralSwitch_ISig_4 3 "TransmissionNeutralSwitch_NotAvailable" 2 "TransmissionNeutralSwitch_Error" 1 "TransmissionNeutralSwitch_TransmissionInNeutral" 0 "TransmissionNeutralSwitch_TransmissionNotInNeutral" ;
VAL_ 2147484168 SecuredNeutralPosition_ISig_4 3 "SecuredNeutralPosition_NotAvailable" 2 "SecuredNeutralPosition_Error" 1 "SecuredNeutralPosition_SecuredNeutralPosition" 0 "SecuredNeutralPosition_NotInSecuredNeutralPosition" ;
VAL_ 2147484168 EngineStopRequest_ISig_4 3 "Request_NotAvailable" 2 "Request_Error" 1 "Request_RequestActive" 0 "Request_NotRequested" ;
VAL_ 2147484168 ReverseGearEngaged_ISig_4 3 "ReverseGearEngaged_NotAvailable" 2 "ReverseGearEngaged_Error" 1 "ReverseGearEngaged_ReverseGearEngaged" 0 "ReverseGearEngaged_ReverseGearNotEngaged" ;
VAL_ 2147484168 EngineCrankRequest 3 "Request_NotAvailable" 2 "Request_Error" 1 "Request_RequestActive" 0 "Request_NotRequested" ;
VAL_ 2147484168 ParkBrakeActuationStatus 7 "ParkBrakeActuationStatus_NotAvailable" 6 "ParkBrakeActuationStatus_Error" 5 "ParkBrakeActuationStatus_SpareValue_01" 4 "ParkBrakeActuationStatus_SpareValue" 3 "ParkBrakeActuationStatus_AntiCompound" 2 "ParkBrakeActuationStatus_Parked" 1 "ParkBrakeActuationStatus_PartiallyParked" 0 "ParkBrakeActuationStatus_Released" ;
VAL_ 2147484168 EnginePreheat_rqst 3 "Request_NotAvailable" 2 "Request_Error" 1 "Request_RequestActive" 0 "Request_NotRequested" ;
VAL_ 2147484168 KeyPosition_ISig_4 7 "KeyPosition_NotAvailable" 6 "KeyPosition_ErrorIndicator" 5 "KeyPosition_IgnitionKeyInCrankPosition" 4 "KeyPosition_IgnitionKeyInPreheatPosition" 3 "KeyPosition_IgnitionKeyIn15PositionNormalDrivingPosition" 2 "KeyPosition_IgnitionKeyInAccessoryPosition" 1 "KeyPosition_IgnitionKeyInOffPosition" 0 "KeyPosition_KeyOut" ;
VAL_ 2147484168 GearSplit_Status_ISig_4 3 "GearSplit_Status_NotAvailable" 2 "GearSplit_Status_Error" 1 "GearSplit_Status_HighSplit" 0 "GearSplit_Status_LowSplit" ;
VAL_ 2147484168 FerryFunctionSwitchChangeACK_ISi 3 "Ack2Bit_NotAvailable" 2 "Ack2Bit_Error" 1 "Ack2Bit_ChangeAcknowledged" 0 "Ack2Bit_NoAction" ;
VAL_ 2147484168 DirectionIndication_cmd 15 "DirectionIndication_cmd_NotAvailable" 14 "DirectionIndication_cmd_Error" 13 "DirectionIndication_cmd_ActBothTruckTrailerTelltalesFaultInd" 12 "DirectionIndication_cmd_ActBothTruckTelltalesFaultInd" 11 "DirectionIndication_cmd_ActRghtTruckRghtTrailTelltaleFaultInd" 10 "DirectionIndication_cmd_ActLeftTruckLeftTrailTelltaleFaultInd" 9 "DirectionIndication_cmd_ActRghtTruckTelltaleFaultInd" 8 "DirectionIndication_cmd_ActLeftTruckTelltaleFaultInd" 7 "DirectionIndication_cmd_ActivateBothTruckAndTrailer_Hazard" 6 "DirectionIndication_cmd_ActivateBothTruck_Hazard" 5 "DirectionIndication_cmd_ActivateRightTruckAndTrailer" 4 "DirectionIndication_cmd_ActivateLeftTruckAndTrailer" 3 "DirectionIndication_cmd_ActivateRightTruck" 2 "DirectionIndication_cmd_ActivateLeftTruck" 1 "DirectionIndication_cmd_ActivateLow" 0 "DirectionIndication_cmd_Deactivate" ;
VAL_ 2147484168 IdleShutdownWarning 3 "InactiveActive_NotAvailable" 2 "InactiveActive_Error" 1 "InactiveActive_Active" 0 "InactiveActive_Inactive" ;
VAL_ 2147484168 BackToDriveReqACK_ISig_4 3 "BackToDriveReqACK_NotAvailable" 2 "BackToDriveReqACK_Error" 1 "BackToDriveReqACK_ChangeAcknowledged" 0 "BackToDriveReqACK_TakNoAction" ;
VAL_ 2147484168 EngineSystemPowerDownRequest_ISi 3 "Request_NotAvailable" 2 "Request_Error" 1 "Request_RequestActive" 0 "Request_NotRequested" ;
VAL_ 2147484897 OilLevelDrvInstr_IncorrEngSpe 3 "DisplayText_NotAvailable" 2 "DisplayText_Error" 1 "DisplayText_DisplayText" 0 "DisplayText_DoNotDisplayText" ;
VAL_ 2147484897 OilLevelDrvInstr_StopVehicle 3 "DisplayText_NotAvailable" 2 "DisplayText_Error" 1 "DisplayText_DisplayText" 0 "DisplayText_DoNotDisplayText" ;
VAL_ 2147484897 SchwungStatus 3 "InactiveActive_NotAvailable" 2 "InactiveActive_Error" 1 "InactiveActive_Active" 0 "InactiveActive_Inactive" ;
VAL_ 2147484897 HillDataCtrlTECU_State_ISig_4 7 "HillDataState_NotAvailable" 6 "HillDataState_Error" 5 "HillDataState_Spare_03" 4 "HillDataState_Spare_02" 3 "HillDataState_Spare_01" 2 "HillDataState_Receive" 1 "HillDataState_Request" 0 "HillDataState_Idle" ;
VAL_ 2147484897 OilLevelDrvInstr_Wait60SecTxt 3 "DisplayText_NotAvailable" 2 "DisplayText_Error" 1 "DisplayText_DisplayText" 0 "DisplayText_DoNotDisplayText" ;
VAL_ 2147484897 ClutchAbuseStatus 3 "ClutchAbuseStatus_NotAvailable" 2 "ClutchAbuseStatus_Error" 1 "ClutchAbuseStatus_ClutchAbused" 0 "ClutchAbuseStatus_ClutchNotAbused" ;
VAL_ 2147484897 TransmissionSplitboxPTOMode 7 "TransmissionSplitboxPTOMode_NotAvailable" 6 "TransmissionSplitboxPTOMode_Error" 5 "TransmissionSplitboxPTOMode_Spare3" 4 "TransmissionSplitboxPTOMode_Spare2" 3 "TransmissionSplitboxPTOMode_Spare1" 2 "TransmissionSplitboxPTOMode_Running" 1 "TransmissionSplitboxPTOMode_Standby" 0 "TransmissionSplitboxPTOMode_Inactive" ;
VAL_ 2147484897 ClutchCalibration_stat 3 "InactiveActive_NotAvailable" 2 "InactiveActive_Error" 1 "InactiveActive_Active" 0 "InactiveActive_Inactive" ;
VAL_ 2147484897 OilLevelDrvInstr_ChangeGearTxt 3 "DisplayText_NotAvailable" 2 "DisplayText_Error" 1 "DisplayText_DisplayText" 0 "DisplayText_DoNotDisplayText" ;
VAL_ 2147484897 OilLevelDrvInstr_NotHorizonTxt 3 "DisplayText_NotAvailable" 2 "DisplayText_Error" 1 "DisplayText_DisplayText" 0 "DisplayText_DoNotDisplayText" ;
VAL_ 2147484897 ISeeStatus 7 "ISeeStatus_NotAvailable" 6 "ISeeStatus_Error" 5 "ISeeStatus_Spare2" 4 "ISeeStatus_Spare1" 3 "ISeeStatus_EnabledAndActive" 2 "ISeeStatus_EnabledButInactive" 1 "ISeeStatus_Disabled" 0 "ISeeStatus_Off" ;
VAL_ 2147484897 EcoRollEnabledStatus 3 "DisableEnable_NotAvailable" 2 "DisableEnable_Error" 1 "DisableEnable_Enable" 0 "DisableEnable_Disable" ;
VAL_ 2147484897 OilLevelDrvInstr_OilTempTxt 3 "DisplayText_NotAvailable" 2 "DisplayText_Error" 1 "DisplayText_DisplayText" 0 "DisplayText_DoNotDisplayText" ;
VAL_ 2147484689 GearShiftingRec_Steps 7 "GearShiftingSteps_NotAvailable" 6 "GearShiftingSteps_Error" 5 "GearShiftingSteps_6step" 4 "GearShiftingSteps_5step" 3 "GearShiftingSteps_4step" 2 "GearShiftingSteps_3step" 1 "GearShiftingSteps_2step" 0 "GearShiftingSteps_1step" ;
VAL_ 2147484689 GearShiftingRec_Direction 7 "GearShiftingDirection_NotAvailable" 6 "GearShiftingDirection_Error" 5 "GearShiftingDirection_Spare3" 4 "GearShiftingDirection_Spare2" 3 "GearShiftingDirection_Spare1" 2 "GearShiftingDirection_Down" 1 "GearShiftingDirection_Up" 0 "GearShiftingDirection_NoShiftRecommendation" ;
VAL_ 2147484689 BrakeInterlockStatus 3 "OffOn_NotAvailable" 2 "OffOn_Error" 1 "OffOn_On" 0 "OffOn_Off" ;
VAL_ 2147484689 AutGearSplitPosition 7 "GearSplitPosition_NotAvailable" 6 "GearSplitPosition_Error" 5 "GearSplitPosition_Spare2" 4 "GearSplitPosition_Spare1" 3 "GearSplitPosition_Crawler" 2 "GearSplitPosition_NoSplit" 1 "GearSplitPosition_HighSplit" 0 "GearSplitPosition_LowSplit" ;
VAL_ 2147484689 TransmissionBrakeMode 3 "InactiveActive_NotAvailable" 2 "InactiveActive_Error" 1 "InactiveActive_Active" 0 "InactiveActive_Inactive" ;
VAL_ 2147484689 FuelEcoDrvStatus 3 "InactiveActive_NotAvailable" 2 "InactiveActive_Error" 1 "InactiveActive_Active" 0 "InactiveActive_Inactive" ;
VAL_ 2147484689 EcoCruiseStatus_ISig_4 7 "EcoCruiseStatus_NotAvailable" 6 "EcoCruiseStatus_Error" 5 "EcoCruiseStatus_Spare02" 4 "EcoCruiseStatus_Spare01" 3 "EcoCruiseStatus_Spare" 2 "EcoCruiseStatus_TemporarilyInactive" 1 "EcoCruiseStatus_Active" 0 "EcoCruiseStatus_Inactive" ;
VAL_ 2147484689 TransmissionDrivingMode 7 "TransmissionDrivingMode_NotAvailable" 6 "TransmissionDrivingMode_Spare" 5 "TransmissionDrivingMode_Dynamometer" 4 "TransmissionDrivingMode_HeavyDuty" 3 "TransmissionDrivingMode_PowerPlus" 2 "TransmissionDrivingMode_Power" 1 "TransmissionDrivingMode_EconomyPlus" 0 "TransmissionDrivingMode_Economy" ;
VAL_ 2147484689 AutoWheelBrakeInhibited 3 "InhibitedStatus_NotAvailable" 2 "InhibitedStatus_Error" 1 "InhibitedStatus_Inhibited" 0 "InhibitedStatus_NotInhibited" ;
VAL_ 2147484689 AutoWheelBrakesDownshiftSugges 3 "DownshiftSuggest_NotAvailable" 2 "DownshiftSuggest_Error" 1 "DownshiftSuggest_SuggestDownshift" 0 "DownshiftSuggest_NoSuggestion" ;
VAL_ 2147484689 TransmissionOilTempHigh_ISig_4 7 "TransmissionOilTempHigh_NotAvailable" 6 "TransmissionOilTempHigh_ErrorIndicator" 5 "TransmissionOilTempHigh_SpareValue_02" 4 "TransmissionOilTempHigh_SpareValue_01" 3 "TransmissionOilTempHigh_SpareValue" 2 "TransmissionOilTempHigh_ActiveVeryHighTemp" 1 "TransmissionOilTempHigh_ActiveHighTemp" 0 "TransmissionOilTempHigh_Inactive" ;
VAL_ 2147484164 Pto1Consent_ISig_4 3 "PtoConsent_NotAvailable" 2 "PtoConsent_Error" 1 "PtoConsent_ConsentGivenPTODriveMayBeEngaged" 0 "PtoConsent_ConsentNotGivenPTODriveShouldNotBeEngaged" ;
VAL_ 2147484164 Pto2Consent_ISig_4 3 "PtoConsent_NotAvailable" 2 "PtoConsent_Error" 1 "PtoConsent_ConsentGivenPTODriveMayBeEngaged" 0 "PtoConsent_ConsentNotGivenPTODriveShouldNotBeEngaged" ;
VAL_ 2147484164 DirectionGearAllowed 7 "DirectionGearAllowed_NotAvailable" 6 "DirectionGearAllowed_Error" 5 "DirectionGearAllowed_NotUsed_01" 4 "DirectionGearAllowed_NotUsed" 3 "DirectionGearAllowed_ForwardOrReverseGearAllowed" 2 "DirectionGearAllowed_ReverseGearAllowed" 1 "DirectionGearAllowed_ForwardGearAllowed" 0 "DirectionGearAllowed_NoChangePossible" ;
VAL_ 2147484164 TransmissionSystemPowerDownAck 3 "TransmissionSystemPowerDownAck_DontCare" 2 "TransmissionSystemPowerDownAck_NotDefined" 1 "TransmissionSystemPowerDownAck_OKToPowerDownTECU" 0 "TransmissionSystemPowerDownAck_NotOKToPowerDownTECU" ;
VAL_ 2147484164 EcoRollActiveStatus_ISig_4 3 "InactiveActive_NotAvailable" 2 "InactiveActive_Error" 1 "InactiveActive_Active" 0 "InactiveActive_Inactive" ;
VAL_ 2147484164 TransmissionAirPressureLow 3 "TransmissionAirPressureLow_NotAvailable" 2 "TransmissionAirPressureLow_Error" 1 "TransmissionAirPressureLow_AirPressureLow" 0 "TransmissionAirPressureLow_AirPressureOk" ;
VAL_ 2147484164 GearBoxUnlockAuth_rqst 3 "GearBoxUnlockAuth_rqst_NotAvaiable" 2 "GearBoxUnlockAuth_rqst_Error" 1 "GearBoxUnlockAuth_rqst_GearEngagementRequested" 0 "GearBoxUnlockAuth_rqst_GearEngagementNotRequested" ;
VAL_ 2147484164 TransmEngineStop_req 3 "InactiveActive_NotAvailable" 2 "InactiveActive_Error" 1 "InactiveActive_Active" 0 "InactiveActive_Inactive" ;
VAL_ 2147484164 ACC_SGO_TransmissionStatus 7 "ACC_SGO_TransmissionStatus_NotAvailable" 6 "ACC_SGO_TransmissionStatus_Error" 5 "ACC_SGO_TransmissionStatus_Spare2" 4 "ACC_SGO_TransmissionStatus_ReadyForTakeOff" 3 "ACC_SGO_TransmissionStatus_LowestPossibleSpeedReached" 2 "ACC_SGO_TransmissionStatus_Normal" 1 "ACC_SGO_TransmissionStatus_Take_off_InProgress" 0 "ACC_SGO_TransmissionStatus_ACC_SGO_CanNotBeSupported" ;
VAL_ 2147484164 ClutchOverloadStatus_ISig_4 3 "ClutchOverloadStatus_NotAvailable" 2 "ClutchOverloadStatus_Error" 1 "ClutchOverloadStatus_Overloaded" 0 "ClutchOverloadStatus_NotOverloaded" ;
SIG_GROUP_ 2147484373 ESCReqEMS_sg_ISig_4 1 : ESCReqEMS_CtrlTrimMode_ISig_4 ESCReqEMS_CtrlTrimStat_ISig_4 ESCReqEMS_CtrlTrimValue_ISig_4 ESCReqEMS_CtrlTrimReq_ISig_4;
SIG_GROUP_ 2147484373 ESCReqESC_sg_ISig_4 1 : ESCReqESC_CtrlTrimMode_ISig_4 ESCReqESC_CtrlTrimValue_ISig_4 ESCReqESC_CtrlTrimStat_ISig_4 ESCReqESC_CtrlTrimReq_ISig_4;
SIG_GROUP_ 2147484182 IntLightMode_CoreRqst_sg 1 : IntLightMode_CoreRqst_IL_Mode IntLightMode_CoreRqst_EventFlag;
SIG_GROUP_ 2147484897 OilLevelDrvInstr_sg 1 : OilLevelDrvInstr_IncorrEngSpe OilLevelDrvInstr_StopVehicle OilLevelDrvInstr_Wait60SecTxt OilLevelDrvInstr_ChangeGearTxt OilLevelDrvInstr_NotHorizonTxt OilLevelDrvInstr_OilTempTxt;
SIG_GROUP_ 2147484897 HillDataCtrlTECU_sg_ISig_4 1 : HillDataCtrlTECU_State_ISig_4 HillDataCtrlTECU_AckCnt_ISig_4;
SIG_GROUP_ 2147484689 GearShiftingRec_sg 1 : GearShiftingRec_Steps GearShiftingRec_Direction;
